VERSION "created by canmatrix"

NS_ :

BS_:

BU_: MD1_ECM ETC NODE_5 BSM_EBS RM_IRCS IC_Multic SGW BCM_NBM VCM NODE_31 ETS NODE_45 FCCU DICO NODE_72 FMReceiver SGW2 VCU ADCU MRGEN DTCO MBMS TPMS AI_CAID ELC ELC_R NODE_F7 BMS3 TUROLLA PCM SRR_Front_Left SRR_Rear_Right SRR_Front_Right SRR_Front SRR_Rear_Left ELFA3_S THERMOKING_M TMU_HP_Rr NODE_B1 NODE_B2 NODE_B3 NODE_B4 NODE_B5 NODE_B6 NODE_B7 NODE_B8 BMS2 NODE_B9 NODE_BA NODE_FC NODE_BB NODE_BC NODE_BE NODE_BD NODE_BF ACU NODE_C0 BMS1 NODE_C1 FCU NODE_C3 NODE_C4 NODE_EC NODE_C5 NODE_C6 NODE_C7 NODE_C8 VCU2 NODE_CA NODE_CB NODE_CD NODE_CE NODE_CF NODE_ED ST_ScanTool MASTER68_STD1 NODE_D1 NODE_F2 NODE_FD NODE_D2 MCSL NODE_EB NODE_D3 NODE_D4 NODE_D5 NODE_D6 VCCU NODE_D8 NODE_D9 NODE_F9 DiagTool NODE_DA NODE_DB NODE_DC NODE_DD NODE_DE NODE_DF NODE_E0 NODE_E1 NODE_E2 NODE_E9 NODE_E3 SAS NODE_FB NODE_F8 NODE_E6 ELFA3 NODE_F THERMOKING_D FMS MULTIC_S MULTIC_2 BMS4 BMS5 BMS6 BMS7 BMS8 BMS9 BMS10 BMS11 NODE_71

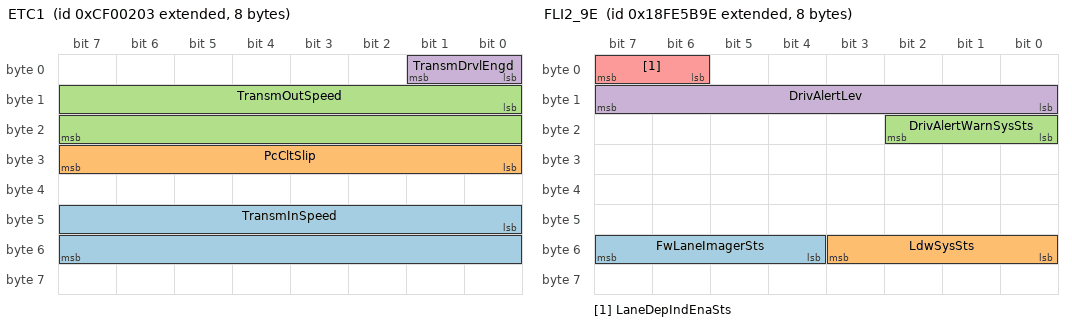
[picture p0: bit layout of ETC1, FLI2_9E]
BO_ 2364539395 ETC1: 8 ETC
 SG_ TransmInSpeed : 40|16@1+ (0.125,0) [0|8031.875] "rpm"  PCM
 SG_ PcCltSlip : 24|8@1+ (0.4,0) [0|100] "%"  PCM
 SG_ TransmOutSpeed : 8|16@1+ (0.125,0) [0|8031.875] "rpm"  PCM
 SG_ TransmDrvlEngd : 0|2@1+ (1,0) [0|3] ""  PCM

BO_ 2565866755 ETC2: 8 ETC
 SG_ TransmCurGear : 24|8@1+ (1,-125) [-125|125] "gear value"  PCM
 SG_ TransmSelGear : 0|8@1+ (1,-125) [-125|125] "gear value"  PCM

BO_ 2566826755 ETC6_P6: 8 ETC
 SG_ LowPossGear : 16|8@1+ (1,-125) [-125|125] "gear value"  PCM
 SG_ HighPossGear : 8|8@1+ (1,-125) [-125|125] "gear value"  PCM

BO_ 2364541955 ETC8: 8 ETC
 SG_ TransmTrqConvRatio : 0|16@1+ (0.001,0) [0|64.255] ""  PCM

BO_ 2566831393 FD1_21: 8 BCM_NBM
 SG_ FanSpeed : 16|16@1+ (0.125,0) [0|8031.875] "rpm"  PCM

BO_ 2431649694 FLI1_9E: 8 ADCU
 SG_ LaneDepImmLh : 6|2@1+ (1,0) [0|3] ""  PCM
 SG_ LaneDepImmRh : 4|2@1+ (1,0) [0|3] ""  PCM

BO_ 2566806430 FLI2_9E: 8 ADCU
 SG_ FwLaneImagerSts : 52|4@1+ (1,0) [0|15] ""  PCM
 SG_ LdwSysSts : 48|4@1+ (1,0) [0|15] ""  PCM
 SG_ DrivAlertWarnSysSts : 16|3@1+ (1,0) [0|7] ""  PCM
 SG_ DrivAlertLev : 8|8@1+ (0.4,0) [0|100] "%"  PCM
 SG_ LaneDepIndEnaSts : 6|2@1+ (1,0) [0|3] ""  PCM

BO_ 2566841600 HOURS: 8 MD1_ECM
 SG_ EngTotHrOfOp : 0|32@1+ (0.05,0) [0|210554060.75] "h"  PCM

BO_ 2566719744 HRLFC: 8 MD1_ECM
 SG_ EngTotFuelUsedHr : 32|32@1+ (0.001,0) [0|4211081.215] "L"  PCM

BO_ 2566837793 HSI1_21: 8 BCM_NBM
 SG_ HybSysCoastRegenBrkLevSel : 16|8@1+ (0.4,0) [0|100] "%"  PCM
 SG_ HybSysPwrElnCoolLevSw : 4|2@1+ (1,0) [0|3] ""  PCM

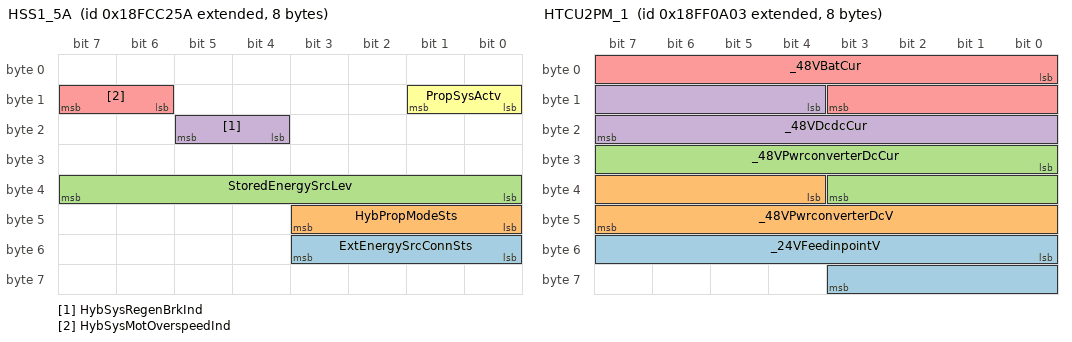
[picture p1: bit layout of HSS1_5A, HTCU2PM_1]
BO_ 2566701658 HSS1_5A: 8 DICO
 SG_ ExtEnergySrcConnSts : 48|4@1+ (1,0) [0|15] ""  PCM
 SG_ HybPropModeSts : 40|4@1+ (1,0) [0|15] ""  PCM
 SG_ StoredEnergySrcLev : 32|8@1+ (0.4,0) [0|100] "%"  PCM
 SG_ HybSysRegenBrkInd : 20|2@1+ (1,0) [0|3] ""  PCM
 SG_ HybSysMotOverspeedInd : 14|2@1+ (1,0) [0|3] ""  PCM
 SG_ PropSysActv : 8|2@1+ (1,0) [0|3] ""  PCM

BO_ 2566698842 HSS2_5A: 8 DICO
 SG_ HybSysEassRemPc : 16|8@1+ (0.4,0) [0|100] "%"  PCM
 SG_ HybBatRemChg : 0|16@1+ (0.0025,0) [0|160.6375] "%"  PCM

BO_ 2566850819 HTCU2BC_03: 8 ETC
 SG_ StsOfHealt : 56|8@1+ (0.5,0) [0|100] "%"  PCM
 SG_ Soc : 44|12@1+ (0.1,-200) [-200|209.5] "%"  PCM

BO_ 2566851075 HTCU2PM_1: 8 ETC
 SG_ _24VFeedinpointV : 48|12@1+ (0.025,0) [0|100.375] "V"  PCM
 SG_ _48VPwrconverterDcV : 36|12@1+ (0.025,0) [0|100.375] "V"  PCM
 SG_ _48VPwrconverterDcCur : 24|12@1+ (0.5,-1000) [-1000|1007.5] "A"  PCM
 SG_ _48VDcdcCur : 12|12@1+ (0.5,-1000) [-1000|1007.5] "A"  PCM
 SG_ _48VBatCur : 0|12@1+ (0.5,-1000) [-1000|1007.5] "A"  PCM

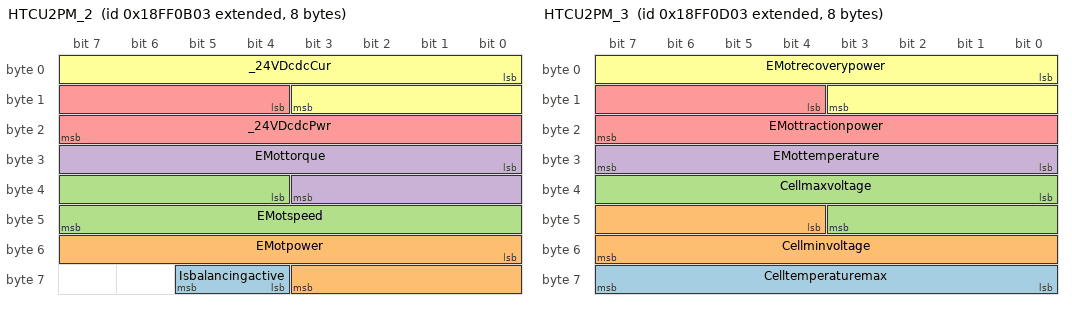
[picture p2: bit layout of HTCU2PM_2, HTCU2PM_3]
BO_ 2566851331 HTCU2PM_2: 8 ETC
 SG_ Isbalancingactive : 60|2@1+ (1,0) [0|3] ""  PCM
 SG_ EMotpower : 48|12@1+ (25,-50000) [-50000|52375] ""  PCM
 SG_ EMotspeed : 36|12@1+ (1,-500) [-500|3515] "rpm"  PCM
 SG_ EMottorque : 24|12@1+ (0.2,-400) [-400|403] "Nm"  PCM
 SG_ _24VDcdcPwr : 12|12@1+ (25,-50000) [-50000|52375] "W"  PCM
 SG_ _24VDcdcCur : 0|12@1+ (0.5,-1000) [-1000|1007.5] "A"  PCM

BO_ 2566851843 HTCU2PM_3: 8 ETC
 SG_ Celltemperaturemax : 56|8@1+ (1,-40) [-40|210] "°C"  PCM
 SG_ Cellminvoltage : 44|12@1+ (0.002,0) [0|8.03] "V"  PCM
 SG_ Cellmaxvoltage : 32|12@1+ (0.002,0) [0|8.03] "V"  PCM
 SG_ EMottemperature : 24|8@1+ (1,-40) [-40|210] "°C"  PCM
 SG_ EMottractionpower : 12|12@1+ (25,-50000) [-50000|52375] "W"  PCM
 SG_ EMotrecoverypower : 0|12@1+ (25,-50000) [-50000|52375] "W"  PCM

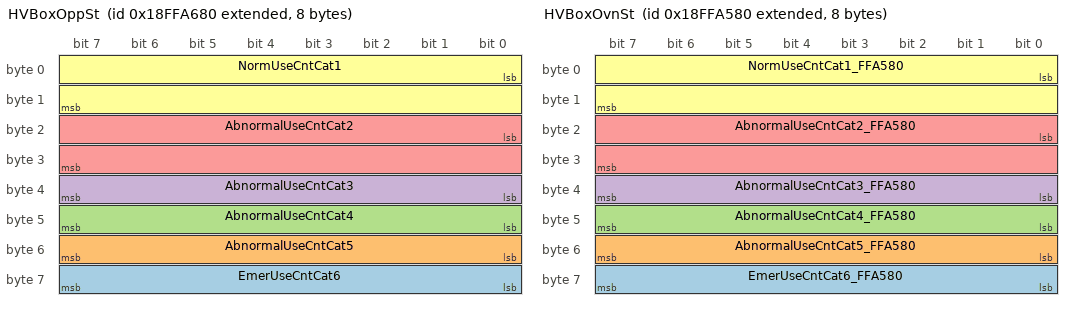
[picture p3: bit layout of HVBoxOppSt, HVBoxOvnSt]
BO_ 2566891136 HVBoxOppSt: 8 VCU
 SG_ EmerUseCntCat6 : 56|8@1+ (1,0) [0|250] "count"  PCM
 SG_ AbnormalUseCntCat5 : 48|8@1+ (1,0) [0|250] "count"  PCM
 SG_ AbnormalUseCntCat4 : 40|8@1+ (5,0) [0|1250] "count"  PCM
 SG_ AbnormalUseCntCat3 : 32|8@1+ (200,0) [0|50000] "count"  PCM
 SG_ AbnormalUseCntCat2 : 16|16@1+ (2,0) [0|128510] "count"  PCM
 SG_ NormUseCntCat1 : 0|16@1+ (5,0) [0|321275] "count"  PCM

BO_ 2566890880 HVBoxOvnSt: 8 VCU
 SG_ EmerUseCntCat6_FFA580 : 56|8@1+ (1,0) [0|250] "count"  PCM
 SG_ AbnormalUseCntCat5_FFA580 : 48|8@1+ (1,0) [0|250] "count"  PCM
 SG_ AbnormalUseCntCat4_FFA580 : 40|8@1+ (5,0) [0|1250] "count"  PCM
 SG_ AbnormalUseCntCat3_FFA580 : 32|8@1+ (200,0) [0|50000] "count"  PCM
 SG_ AbnormalUseCntCat2_FFA580 : 16|16@1+ (2,0) [0|128510] "count"  PCM
 SG_ NormUseCntCat1_FFA580 : 0|16@1+ (5,0) [0|321275] "count"  PCM

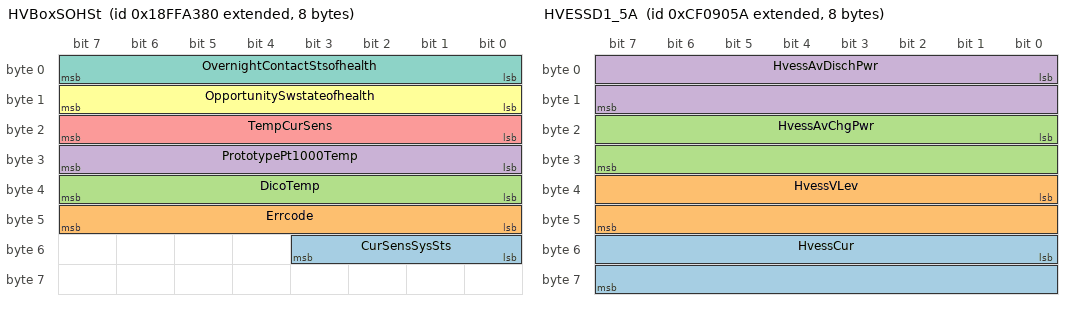
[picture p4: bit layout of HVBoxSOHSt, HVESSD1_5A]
BO_ 2566890368 HVBoxSOHSt: 8 VCU
 SG_ CurSensSysSts : 48|4@1+ (1,0) [0|15] ""  PCM
 SG_ Errcode : 40|8@1+ (1,0) [0|250] ""  PCM
 SG_ DicoTemp : 32|8@1+ (1,-40) [-40|120] "°C"  PCM
 SG_ PrototypePt1000Temp : 24|8@1+ (1,-40) [-40|120] "°C"  PCM
 SG_ TempCurSens : 16|8@1+ (1,-40) [-40|80] "°C"  PCM
 SG_ OpportunitySwstateofhealth : 8|8@1+ (0.4,0) [0|100] "%"  PCM
 SG_ OvernightContactStsofhealth : 0|8@1+ (0.4,0) [0|100] "%"  PCM

BO_ 2364575834 HVESSD1_5A: 8 DICO
 SG_ HvessCur : 48|16@1+ (0.05,-1600) [-1600|1612.75] "A"  PCM
 SG_ HvessVLev : 32|16@1+ (0.05,0) [0|3212.75] "V"  PCM
 SG_ HvessAvChgPwr : 16|16@1+ (0.05,0) [0|3212.75] "kW"  PCM
 SG_ HvessAvDischPwr : 0|16@1+ (0.05,0) [0|3212.75] "kW"  PCM

BO_ 2365349619 HVESSHIST_F3: 11 MBMS
 SG_ HvessTotAccumChg : 56|32@1+ (100,0) [0|421108121500] "Ah"  PCM
 SG_ HvessTotEnergyTput : 24|32@1+ (100,0) [0|421108121500] "Watt-hour"  PCM
 SG_ HvessSoh : 0|8@1+ (0.4,0) [0|100] "%"  PCM

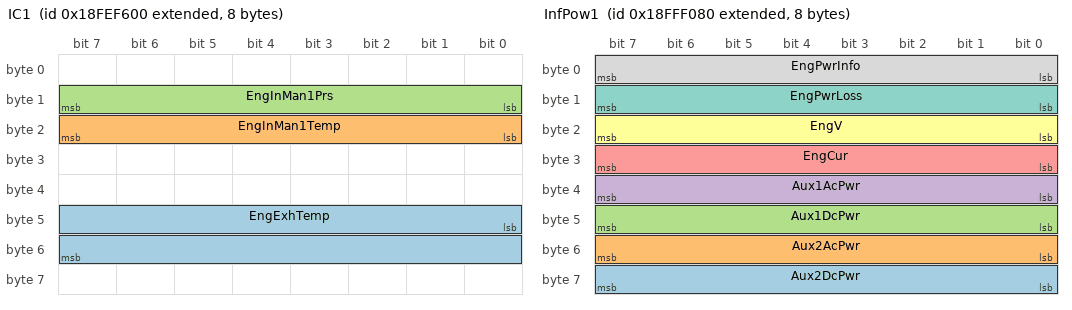
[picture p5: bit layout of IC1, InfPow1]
BO_ 2566845952 IC1: 8 MD1_ECM
 SG_ EngExhTemp : 40|16@1+ (0.03125,-273) [-273|1734.96875] "°C"  PCM
 SG_ EngInMan1Temp : 16|8@1+ (1,-40) [-40|210] "°C"  PCM
 SG_ EngInMan1Prs : 8|8@1+ (2,0) [0|500] "kPa"  PCM

BO_ 2566910080 InfPow1: 8 VCU
 SG_ Aux2DcPwr : 56|8@1+ (0.2,0) [0|50] "KW"  PCM
 SG_ Aux2AcPwr : 48|8@1+ (0.2,0) [0|50] "KW"  PCM
 SG_ Aux1DcPwr : 40|8@1+ (0.2,0) [0|50] "KW"  PCM
 SG_ Aux1AcPwr : 32|8@1+ (0.2,0) [0|50] "KW"  PCM
 SG_ EngCur : 24|8@1+ (4,-500) [-500|500] "A"  PCM
 SG_ EngV : 16|8@1+ (3.4,0) [0|850] "V"  PCM
 SG_ EngPwrLoss : 8|8@1+ (0.2,0) [0|50] "KW"  PCM
 SG_ EngPwrInfo : 0|8@1+ (4,-500) [-500|500] "KW"  PCM

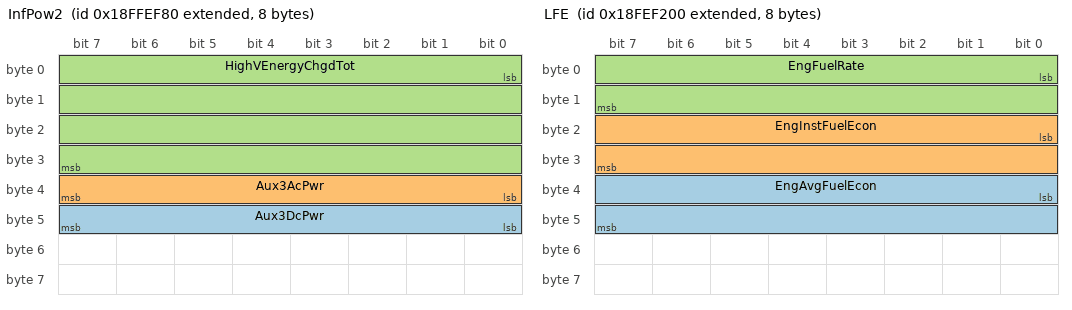
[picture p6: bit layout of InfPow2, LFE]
BO_ 2566909824 InfPow2: 8 VCU
 SG_ Aux3DcPwr : 40|8@1+ (0.2,0) [0|50] "KW"  PCM
 SG_ Aux3AcPwr : 32|8@1+ (0.2,0) [0|50] "KW"  PCM
 SG_ HighVEnergyChgdTot : 0|32@1+ (0.1,0) [0|199999999.9] "KWh"  PCM

BO_ 2566786839 LC_17: 8 IC_Multic
 SG_ LangCodeCmd : 0|16@1+ (1,0) [0|65535] "ASCII"  PCM

BO_ 2566842624 LFC: 8 MD1_ECM
 SG_ EngTotFuelUsed : 32|32@1+ (0.5,0) [0|2105540607.5] "L"  PCM

BO_ 2566844928 LFE: 8 MD1_ECM
 SG_ EngAvgFuelEcon : 32|16@1+ (0.001953125,0) [0|125.498046875] "km/L"  PCM
 SG_ EngInstFuelEcon : 16|16@1+ (0.001953125,0) [0|125.498046875] "km/L"  PCM
 SG_ EngFuelRate : 0|16@1+ (0.05,0) [0|3212.75] "L/h"  PCM

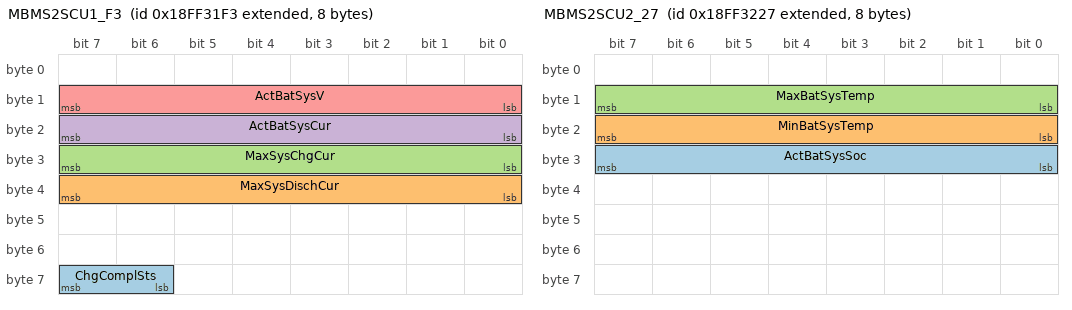
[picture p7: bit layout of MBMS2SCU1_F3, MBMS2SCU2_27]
BO_ 2566861299 MBMS2SCU1_F3: 8 MBMS
 SG_ ChgComplSts : 62|2@1+ (1,0) [0|3] ""  PCM
 SG_ MaxSysDischCur : 32|8@1+ (3,0) [0|750] "A"  PCM
 SG_ MaxSysChgCur : 24|8@1+ (3,0) [0|750] "A"  PCM
 SG_ ActBatSysCur : 16|8@1+ (4,-500) [-500|500] "A"  PCM
 SG_ ActBatSysV : 8|8@1+ (3.4,0) [0|850] "V"  PCM

BO_ 2566861351 MBMS2SCU2_27: 8 VCM
 SG_ ActBatSysSoc : 24|8@1+ (0.4,0) [0|100] "%"  PCM
 SG_ MinBatSysTemp : 16|8@1+ (1,-40) [-40|210] "°C"  PCM
 SG_ MaxBatSysTemp : 8|8@1+ (1,-40) [-40|210] "°C"  PCM

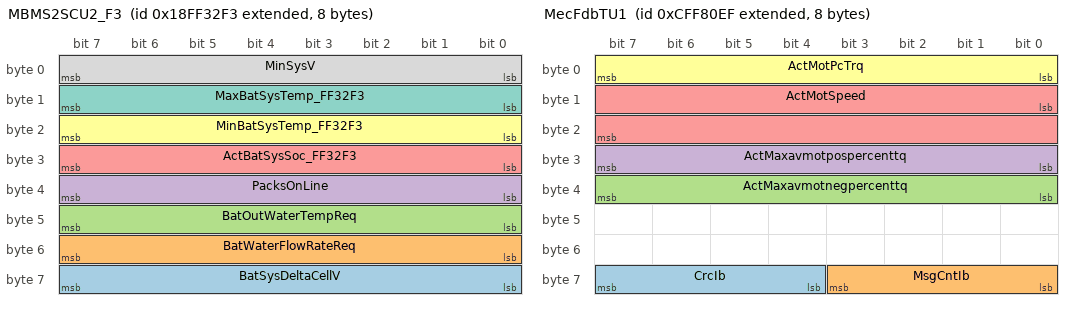
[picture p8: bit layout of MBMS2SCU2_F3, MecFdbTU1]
BO_ 2566861555 MBMS2SCU2_F3: 8 MBMS
 SG_ BatSysDeltaCellV : 56|8@1+ (10,0) [0|2500] "Mv"  PCM
 SG_ BatWaterFlowRateReq : 48|8@1+ (50,0) [0|12500] "L/h"  PCM
 SG_ BatOutWaterTempReq : 40|8@1+ (1,-40) [-40|210] "°C"  PCM
 SG_ PacksOnLine : 32|8@1+ (1,0) [0|250] "pack"  PCM
 SG_ ActBatSysSoc_FF32F3 : 24|8@1+ (0.4,0) [0|100] "%"  PCM
 SG_ MinBatSysTemp_FF32F3 : 16|8@1+ (1,-40) [-40|210] "°C"  PCM
 SG_ MaxBatSysTemp_FF32F3 : 8|8@1+ (1,-40) [-40|210] "°C"  PCM
 SG_ MinSysV : 0|8@1+ (3.4,0) [0|850] "V"  PCM

BO_ 2365554927 MecFdbTU1: 8 ELFA3
 SG_ CrcIb : 60|4@1+ (1,0) [0|15] ""  PCM
 SG_ MsgCntIb : 56|4@1+ (1,0) [0|15] ""  PCM
 SG_ ActMaxavmotnegpercenttq : 32|8@1+ (1,-125) [-125|0] "%"  PCM
 SG_ ActMaxavmotpospercenttq : 24|8@1+ (1,-125) [0|125] "%"  PCM
 SG_ ActMotSpeed : 8|16@1+ (1,-32127) [-32127|32128] "rpm"  PCM
 SG_ ActMotPcTrq : 0|8@1+ (1,-125) [-125|125] "%"  PCM

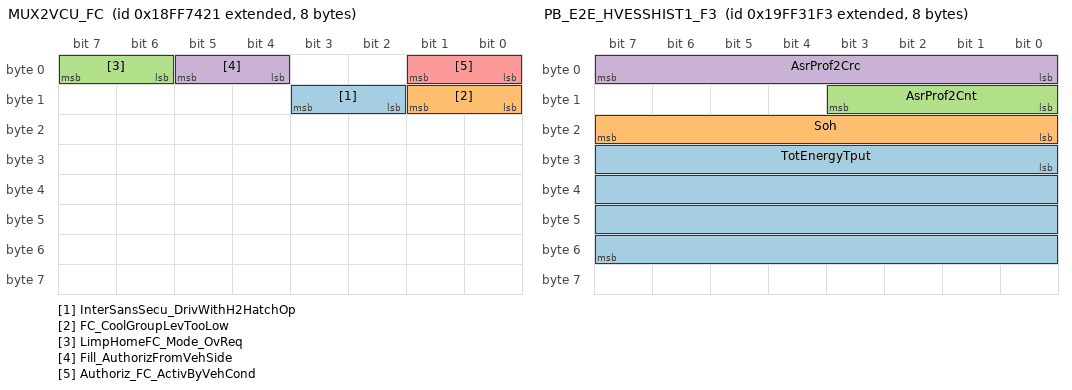
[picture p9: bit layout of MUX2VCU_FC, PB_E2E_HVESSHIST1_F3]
BO_ 2566878241 MUX2VCU_FC: 8 BCM_NBM
 SG_ InterSansSecu_DrivWithH2HatchOp : 10|2@1+ (1,0) [0|1] ""  PCM
 SG_ FC_CoolGroupLevTooLow : 8|2@1+ (1,0) [0|1] ""  PCM
 SG_ LimpHomeFC_Mode_OvReq : 6|2@1+ (1,0) [0|1] ""  PCM
 SG_ Fill_AuthorizFromVehSide : 4|2@1+ (1,0) [0|1] ""  PCM
 SG_ Authoriz_FC_ActivByVehCond : 0|2@1+ (1,0) [0|3] ""  PCM

BO_ 2566776097 MVS_21: 8 BCM_NBM
 SG_ AppliedVsl : 56|8@1+ (1,0) [0|250] "km/h"  PCM
 SG_ MaxVsl1 : 0|8@1+ (1,0) [0|250] "km/h"  PCM

BO_ 2365443105 OEL: 8 BCM_NBM
 SG_ TurnSigSw : 8|4@1+ (1,0) [0|15] ""  PCM

BO_ 2566769953 OWW_21: 8 BCM_NBM
 SG_ FrontOpWasherSw : 45|3@1+ (1,0) [0|7] ""  PCM
 SG_ FrontOpWiperSw : 4|4@1+ (1,0) [0|15] ""  PCM

BO_ 2633959399 PB_ACU: 8 ACU
 SG_ StopLamp : 6|2@1+ (1,0) [0|3] ""  PCM
 SG_ FunctLamp : 4|2@1+ (1,0) [0|3] ""  PCM

BO_ 2566850535 PB_ACU_E7: 8 ACU
 SG_ StopLamp_FF07E7 : 6|2@1+ (1,0) [0|3] ""  PCM
 SG_ FunctLamp_FF07E7 : 4|2@1+ (1,0) [0|3] ""  PCM

BO_ 2566908574 PB_AIDI_9E: 8 ADCU
 SG_ DdawRunMode : 8|3@1+ (1,0) [0|7] ""  PCM
 SG_ DrowsDrivLev : 3|3@1+ (1,0) [0|7] ""  PCM

BO_ 2583638515 PB_E2E_HVESSHIST1_F3: 8 MBMS
 SG_ TotEnergyTput : 24|32@1+ (1000,0) [0|4211081215000] "Watt-hour"  PCM
 SG_ Soh : 16|8@1+ (0.4,0) [0|100] "%"  PCM
 SG_ AsrProf2Cnt : 8|4@1+ (1,0) [0|15] ""  PCM
 SG_ AsrProf2Crc : 0|8@1+ (1,0) [0|255] ""  PCM

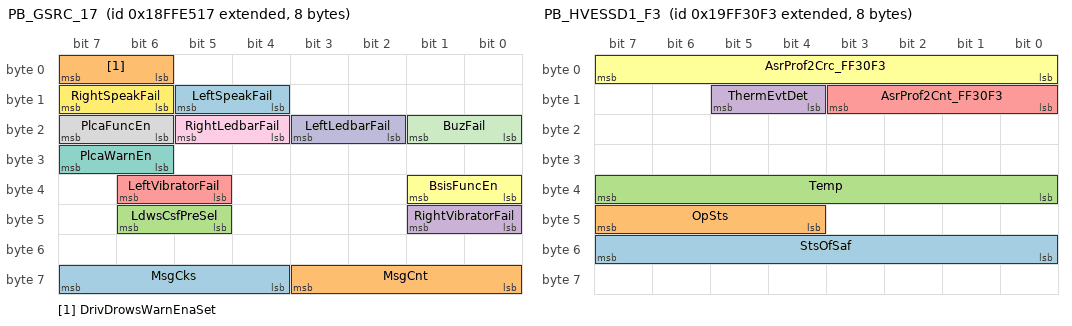
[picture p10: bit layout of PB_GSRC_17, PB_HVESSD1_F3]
BO_ 2566907159 PB_GSRC_17: 8 IC_Multic
 SG_ MsgCks : 60|4@1+ (1,0) [0|15] "count"  PCM
 SG_ MsgCnt : 56|4@1+ (1,0) [0|15] "count"  PCM
 SG_ LdwsCsfPreSel : 45|2@1+ (1,0) [0|3] ""  PCM
 SG_ RightVibratorFail : 40|2@1+ (1,0) [0|3] ""  PCM
 SG_ LeftVibratorFail : 37|2@1+ (1,0) [0|3] ""  PCM
 SG_ BsisFuncEn : 32|2@1+ (1,0) [0|3] ""  PCM
 SG_ PlcaWarnEn : 30|2@1+ (1,0) [0|3] ""  PCM
 SG_ PlcaFuncEn : 22|2@1+ (1,0) [0|3] ""  PCM
 SG_ RightLedbarFail : 20|2@1+ (1,0) [0|3] ""  PCM
 SG_ LeftLedbarFail : 18|2@1+ (1,0) [0|3] ""  PCM
 SG_ BuzFail : 16|2@1+ (1,0) [0|3] ""  PCM
 SG_ RightSpeakFail : 14|2@1+ (1,0) [0|3] ""  PCM
 SG_ LeftSpeakFail : 12|2@1+ (1,0) [0|3] ""  PCM
 SG_ DrivDrowsWarnEnaSet : 6|2@1+ (1,0) [0|3] ""  PCM

BO_ 2583638259 PB_HVESSD1_F3: 8 MBMS
 SG_ StsOfSaf : 48|8@1+ (0.4,0) [0|100] "%"  PCM
 SG_ OpSts : 44|4@1+ (1,0) [0|15] ""  PCM
 SG_ Temp : 32|8@1+ (1,-40) [-40|210] "°C"  PCM
 SG_ ThermEvtDet : 12|2@1+ (1,0) [0|3] ""  PCM
 SG_ AsrProf2Cnt_FF30F3 : 8|4@1+ (1,0) [0|15] ""  PCM
 SG_ AsrProf2Crc_FF30F3 : 0|8@1+ (1,0) [0|255] ""  PCM

BO_ 2650750451 PB_HVESSHIST_F3: 11 MBMS
 SG_ HvessTotAccumChg_FF3DF3 : 56|32@1+ (100,0) [0|421108121500] "Ah"  PCM
 SG_ HvessTotEnergyTput_FF3DF3 : 24|32@1+ (100,0) [0|421108121500] "Watt-hour"  PCM
 SG_ HvessSoh_FF3DF3 : 0|8@1+ (0.4,0) [0|100] "%"  PCM

BO_ 2566894871 PB_ISA_17: 8 IC_Multic
 SG_ CntryCode : 22|10@1+ (1,0) [0|1023] ""  PCM
 SG_ IntlSpeedAssantActv : 8|3@1+ (1,0) [0|7] ""  PCM

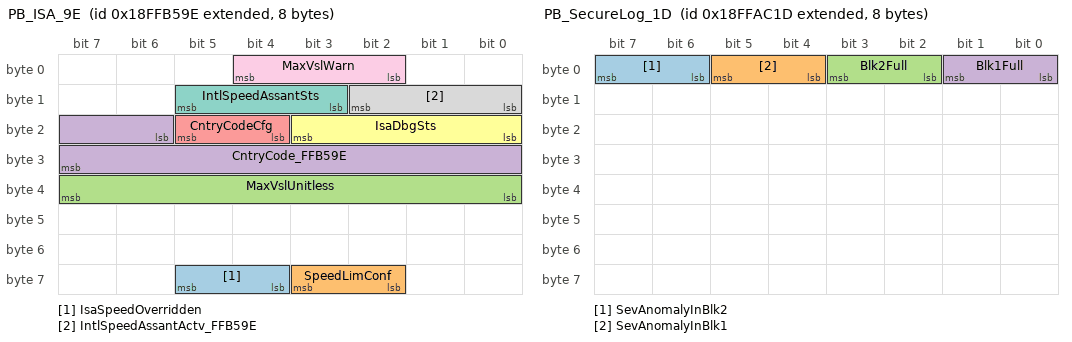
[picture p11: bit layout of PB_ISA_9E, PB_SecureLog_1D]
BO_ 2566895006 PB_ISA_9E: 8 ADCU
 SG_ IsaSpeedOverridden : 60|2@1+ (1,0) [0|3] ""  PCM
 SG_ SpeedLimConf : 58|2@1+ (1,0) [0|3] ""  PCM
 SG_ MaxVslUnitless : 32|8@1+ (1,0) [0|140] ""  PCM
 SG_ CntryCode_FFB59E : 22|10@1+ (1,0) [0|1023] ""  PCM
 SG_ CntryCodeCfg : 20|2@1+ (1,0) [0|3] ""  PCM
 SG_ IsaDbgSts : 16|4@1+ (1,0) [0|15] ""  PCM
 SG_ IntlSpeedAssantSts : 11|3@1+ (1,0) [0|7] ""  PCM
 SG_ IntlSpeedAssantActv_FFB59E : 8|3@1+ (1,0) [0|7] ""  PCM
 SG_ MaxVslWarn : 2|3@1+ (1,0) [0|3] ""  PCM

BO_ 2365575713 PB_NmM: 8 BCM_NBM
 SG_ EngStarterSts : 20|2@1+ (1,0) [0|3] ""  PCM
 SG_ IgnOn : 4|2@1+ (1,0) [0|3] ""  PCM

BO_ 2566892573 PB_SecureLog_1D: 8 SGW
 SG_ SevAnomalyInBlk2 : 6|2@1+ (1,0) [0|3] ""  PCM
 SG_ SevAnomalyInBlk1 : 4|2@1+ (1,0) [0|3] ""  PCM
 SG_ Blk2Full : 2|2@1+ (1,0) [0|3] ""  PCM
 SG_ Blk1Full : 0|2@1+ (1,0) [0|3] ""  PCM

BO_ 2566892618 PB_SecureLog_4A: 8 PCM
 SG_ WarnRx : 8|2@1+ (1,0) [0|3] "" Vector__XXX

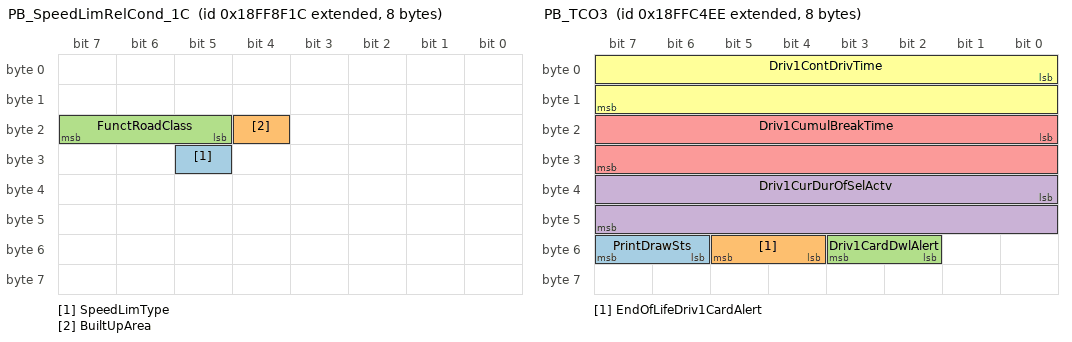
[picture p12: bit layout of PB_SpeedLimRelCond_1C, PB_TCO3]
BO_ 2566885148 PB_SpeedLimRelCond_1C: 8 PCM
 SG_ SpeedLimType : 29|1@0+ (1,0) [0|1] "" Vector__XXX
 SG_ BuiltUpArea : 20|1@0+ (1,0) [0|1] "" Vector__XXX
 SG_ FunctRoadClass : 23|3@0+ (1,0) [0|7] "" Vector__XXX

BO_ 2566898670 PB_TCO2: 21 DTCO
 SG_ WFact : 152|16@1+ (0.001,0) [2.4|25] "pulse/m"  PCM
 SG_ NextCalDateYr : 144|8@1+ (1,1985) [1985|2235] "year"  PCM
 SG_ NextCalDateMonth : 136|8@1+ (1,0) [1|12] "month"  PCM
 SG_ NextCalDateDay : 128|8@1+ (0.25,0) [0.25|31.75] "day"  PCM
 SG_ PrefLang : 112|16@1+ (1,0) [0|255] "ASCII"  PCM
 SG_ Driv1Id_FFC3EE : 0|8@1+ (1,0) [0|255] "ASCII"  PCM

BO_ 2566898926 PB_TCO3: 8 DTCO
 SG_ PrintDrawSts : 54|2@1+ (1,0) [0|3] ""  PCM
 SG_ EndOfLifeDriv1CardAlert : 52|2@1+ (1,0) [0|3] ""  PCM
 SG_ Driv1CardDwlAlert : 50|2@1+ (1,0) [0|3] ""  PCM
 SG_ Driv1CurDurOfSelActv : 32|16@1+ (1,0) [0|64255] "min"  PCM
 SG_ Driv1CumulBreakTime : 16|16@1+ (1,0) [0|64255] "min"  PCM
 SG_ Driv1ContDrivTime : 0|16@1+ (1,0) [0|64255] "min"  PCM

BO_ 2566899694 PB_TCO4: 44 DTCO
 SG_ AvCnt : 336|16@1+ (1,0) [0|64255] "min"  PCM
 SG_ WorkCnt : 320|16@1+ (1,0) [0|64255] "min"  PCM
 SG_ DrivCnt : 304|16@1+ (1,0) [0|64255] "min"  PCM
 SG_ TwoWeeksTotOdo : 288|16@1+ (1,0) [0|64255] "km"  PCM
 SG_ WeekTotOdo : 272|16@1+ (1,0) [0|64255] "km"  PCM
 SG_ DayOdo : 256|16@1+ (1,0) [0|64255] "km"  PCM
 SG_ DayRestPer7Flag : 255|1@1+ (1,0) [0|1] ""  PCM
 SG_ DayRestPer7 : 240|15@1+ (1,0) [0|31487] "min"  PCM
 SG_ DayRestPer6Flag : 239|1@1+ (1,0) [0|1] ""  PCM
 SG_ DayRestPer6 : 224|15@1+ (1,0) [0|31487] "min"  PCM
 SG_ DayRestPer5Flag : 223|1@1+ (1,0) [0|1] ""  PCM
 SG_ DayRestPer5 : 208|15@1+ (1,0) [0|31487] "min"  PCM
 SG_ DayRestPer4Flag : 207|1@1+ (1,0) [0|1] ""  PCM
 SG_ DayRestPer4 : 192|15@1+ (1,0) [0|31487] "min"  PCM
 SG_ DayRestPer3Flag : 191|1@1+ (1,0) [0|1] ""  PCM
 SG_ DayRestPer3 : 176|15@1+ (1,0) [0|31487] "min"  PCM
 SG_ DayRestPer2Flag : 175|1@1+ (1,0) [0|1] ""  PCM
 SG_ DayRestPer2 : 160|15@1+ (1,0) [0|31487] "min"  PCM
 SG_ DayRestPer1Flag : 159|1@1+ (1,0) [0|1] ""  PCM
 SG_ DayRestPer1 : 144|15@1+ (1,0) [0|31487] "min"  PCM
 SG_ DayDrivTimeShift6Flag : 143|1@1+ (1,0) [0|1] ""  PCM
 SG_ DayDrivTimeShift6 : 128|15@1+ (1,0) [0|31487] "min"  PCM
 SG_ DayDrivTimeShift5Flag : 127|1@1+ (1,0) [0|1] ""  PCM
 SG_ DayDrivTimeShift5 : 112|15@1+ (1,0) [0|31487] "min"  PCM
 SG_ DayDrivTimeShift4Flag : 111|1@1+ (1,0) [0|1] ""  PCM
 SG_ DayDrivTimeShift4 : 96|15@1+ (1,0) [0|31487] "min"  PCM
 SG_ DayDrivTimeShift3Flag : 95|1@1+ (1,0) [0|1] ""  PCM
 SG_ DayDrivTimeShift3 : 80|15@1+ (1,0) [0|31487] "min"  PCM
 SG_ DayDrivTimeShift2Flag : 79|1@1+ (1,0) [0|1] ""  PCM
 SG_ DayDrivTimeShift2 : 64|15@1+ (1,0) [0|31487] "min"  PCM
 SG_ DayDrivTimeShift1Flag : 63|1@1+ (1,0) [0|1] ""  PCM
 SG_ DayDrivTimeShift1 : 48|15@1+ (1,0) [0|31487] "min"  PCM
 SG_ DayDrivTimeFlag : 47|1@1+ (1,0) [0|1] ""  PCM
 SG_ DayDrivTime : 32|15@1+ (1,0) [0|31487] "min"  PCM
 SG_ WeekTotDrivTime : 16|16@1+ (1,0) [0|64255] "min"  PCM
 SG_ TwoWeeksTotDrivTime : 0|16@1+ (1,0) [0|64255] "min"  PCM

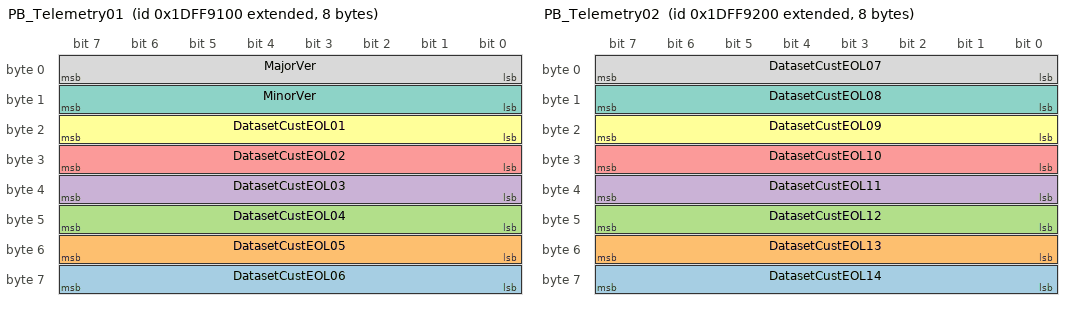
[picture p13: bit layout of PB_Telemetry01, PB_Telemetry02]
BO_ 2650771712 PB_Telemetry01: 8 MD1_ECM
 SG_ DatasetCustEOL06 : 56|8@1+ (1,0) [0|255] ""  PCM
 SG_ DatasetCustEOL05 : 48|8@1+ (1,0) [0|255] ""  PCM
 SG_ DatasetCustEOL04 : 40|8@1+ (1,0) [0|255] ""  PCM
 SG_ DatasetCustEOL03 : 32|8@1+ (1,0) [0|255] ""  PCM
 SG_ DatasetCustEOL02 : 24|8@1+ (1,0) [0|255] ""  PCM
 SG_ DatasetCustEOL01 : 16|8@1+ (1,0) [0|255] ""  PCM
 SG_ MinorVer : 8|8@1+ (1,0) [0|255] ""  PCM
 SG_ MajorVer : 0|8@1+ (1,0) [0|255] ""  PCM

BO_ 2650771968 PB_Telemetry02: 8 MD1_ECM
 SG_ DatasetCustEOL14 : 56|8@1+ (1,0) [0|255] ""  PCM
 SG_ DatasetCustEOL13 : 48|8@1+ (1,0) [0|255] ""  PCM
 SG_ DatasetCustEOL12 : 40|8@1+ (1,0) [0|255] ""  PCM
 SG_ DatasetCustEOL11 : 32|8@1+ (1,0) [0|255] ""  PCM
 SG_ DatasetCustEOL10 : 24|8@1+ (1,0) [0|255] ""  PCM
 SG_ DatasetCustEOL09 : 16|8@1+ (1,0) [0|255] ""  PCM
 SG_ DatasetCustEOL08 : 8|8@1+ (1,0) [0|255] ""  PCM
 SG_ DatasetCustEOL07 : 0|8@1+ (1,0) [0|255] ""  PCM

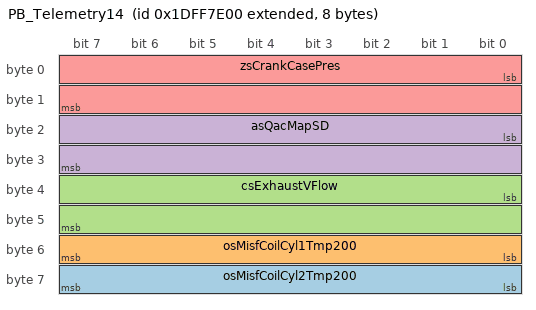
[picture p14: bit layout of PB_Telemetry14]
BO_ 2650766848 PB_Telemetry14: 8 MD1_ECM
 SG_ osMisfCoilCyl2Tmp200 : 56|8@1+ (1,0) [0|255] "adm"  PCM
 SG_ osMisfCoilCyl1Tmp200 : 48|8@1+ (1,0) [0|255] "adm"  PCM
 SG_ csExhaustVFlow : 32|16@1+ (0.2,0) [0|13107] "m^3/h"  PCM
 SG_ asQacMapSD : 16|16@1+ (0.125,0) [0|8191.875] "mg/cc"  PCM
 SG_ zsCrankCasePres : 0|16@1+ (0.5,0) [-16384|16385.5] "mbar"  PCM

CM_ SG_ 2364539395 TransmInSpeed "- CUC.C.PCM..3..TELEM: Optional";
CM_ SG_ 2364539395 PcCltSlip "- CUC.C.PCM..3..TELEM: Optional
- EBC.ZF.BSM..27..VDB: not sent by AGB ZF Ecolife 2 + on FEV";
CM_ BO_ 2565866755 "- All Powertrain except manual transmission.
-  Full elec: J1939 codification, but only D/N/R and +1/0/-1 are used as there is no gearBox).
-  Multi-PG association valid when VCM is the sender of the message. Transmitted when no ETC, received otherwise
- IC1.A.IC.MulticS.24.CwFE.VDB: Update in according with ''OPL_Supermap'' request (line 50).";
CM_ SG_ 2565866755 TransmCurGear "- Negative values are reverse gears, positive values are forward gears, zero is neutral. 251(0xFB) is park";
CM_ SG_ 2565866755 TransmSelGear "- Negative values are reverse gears, positive values are forward gears, zero is neutral. 251(0xFB) is park
- MC.A.VCU..24..VDB: Only Gx (ELFA2)";
CM_ BO_ 2566826755 "- Only with manual transmission. SAE recommanded priority=7";
CM_ SG_ 2566826755 LowPossGear "- At least 3 gears below the maximum possible to indicate Splitter Low, 0xFF otherwise";
CM_ SG_ 2566826755 HighPossGear "- At least 3 gears above the maximum possible to indicate Splitter High, 0xFF otherwise";
CM_ BO_ 2364541955 "- 100ms in case torque converter locked. 20ms otherwise";
CM_ BO_ 2566831393 "- Only on UW Diesel CNG";
CM_ BO_ 2431649694 "- Fastest transmission rate 50ms when requested / not send when not requested
-  Transmitted when Lane Departure is active and at least once afterwards.";
CM_ BO_ 2566841600 "- All engines available, even if SA=00.
-  Cyclic Transmission Rate as result of PGN requests
-  SGW requests this PGN with RQST_1D_00
- VS2.B.SGW2..23..VDB: Used in freeze frames parameters.";
CM_ SG_ 2566841600 EngTotHrOfOp "- SAE J1939/73 Freeze Frame parameter";
CM_ BO_ 2566719744 "- Accumulated amount of fuel used during vehicle operation.";
CM_ BO_ 2566837793 "- Specific to Siemens Full Elec vehicles";
CM_ SG_ 2566837793 HybSysCoastRegenBrkLevSel "- Signal name Intercity file: Hybrid System Handlever Retarder";
CM_ BO_ 2566701658 "- Specific to Siemens Full Elec vehicles.
-  Transmision: Now 100ms, previously 1000ms, 100ms on change";
CM_ BO_ 2566698842 "- Specific to Siemens Full Elec vehicles";
CM_ SG_ 2566698842 HybBatRemChg "- Indicates the hybrid battery pack remaining charge. 0% means no charge remaining, 100% means full charge remaining. 0.0025 %/bit . offset 0 . 0 to 160.6375 %.";
CM_ BO_ 2566850819 "- Related to Voith Mild Hybrid project";
CM_ BO_ 2566851075 "- Related to Voith Mild Hybrid project
- CUC.C.PCM..3..TELEM: - Predisposal";
CM_ BO_ 2566851331 "- Related to Voith Mild Hybrid project
-  UW Mild Hybrid only";
CM_ BO_ 2566851843 "- Related to Voith Mild Hybrid project";
CM_ BO_ 2566891136 "- Specific to Siemens Full Elec vehicles";
CM_ BO_ 2566890880 "- Specific to Siemens Full Elec vehicles";
CM_ BO_ 2566890368 "- Specific to Siemens Full Elec vehicles. PCM Traction: in according with VCU file";
CM_ SG_ 2566890368 Errcode "- On event: in case of change of the errorCode the message will be send out acyclic.";
CM_ BO_ 2364575834 "- Specific to Siemens Full Elec vehicles.";
CM_ SG_ 2364575834 HvessCur "- A positive value represents current into (charging) the energy storage system.  A negative value represents current out of (discharging) the energy storage system.";
CM_ SG_ 2364575834 HvessAvChgPwr "- Send to NA value";
CM_ SG_ 2364575834 HvessAvDischPwr "- Send to NA value";
CM_ BO_ 2365349619 "- Specific to Siemens Full Elec vehicles - Predispo for PCM.
-  With Foresee batteries (GX with ELFA2): HVESSHIST_F3 message ID 0x 0C FC 5E F3";
CM_ SG_ 2566845952 EngExhTemp "- FE00h in case of defective sensor";
CM_ SG_ 2566845952 EngInMan1Temp "- FEh in case of defective sensor";
CM_ SG_ 2566845952 EngInMan1Prs "- FEh in case of defective sensor";
CM_ BO_ 2566910080 "- Specific to Siemens Full Elec vehicles";
CM_ BO_ 2566909824 "- Specific to Siemens Full Elec vehicles. Predisposal";
CM_ SG_ 2566909824 HighVEnergyChgdTot "- Total energy charged in the high voltage batteries in the vehicle life time";
CM_ SG_ 2566786839 LangCodeCmd "- Uses the 2-character string country codes in ISO 639.";
CM_ BO_ 2566842624 "- All engines except Full elec. CAN Engine: Only ''On Request''. Others Cyclic Transmission Rate as result of PGN requests";
CM_ BO_ 2566844928 "- All engines, without Full elec";
CM_ SG_ 2566844928 EngAvgFuelEcon "- Not emitted with C9 CNG";
CM_ BO_ 2566861299 "- Specific to Siemens Full Elec vehicles.
- CLC1.Tk.ACM....VDB: Filled in according with Intercity file";
CM_ BO_ 2566861351 "- Specific to Siemens Full Elec vehicles. Timeout (ms): 3000 ms";
CM_ BO_ 2566861555 "- Specific to Siemens Full Elec vehicles";
CM_ BO_ 2365554927 "- Specific to Siemens Full Elec vehicles. PCM: Fill in according with VCU file (CAN Traction)";
CM_ BO_ 2566776097 "- Specific to Siemens Full Elec vehicles.";
CM_ BO_ 2365443105 "- ADC.ZF.ADCU..24..VDB: Transmission rate may differ: ADCU VDB: 1000/On change";
CM_ BO_ 2633959399 "- 18m only.
-  In some applications used: Priority 6 (Id message 18 FF 07 E7)";
CM_ BO_ 2566850535 "- 18m only. Requested in Priority 6 (0x18). 19.07.2024";
CM_ BO_ 2566908574 "- Bus load periodic : 0.13";
CM_ SG_ 2566908574 DdawRunMode "- Valid for BUS MY24 DDAW indirect application";
CM_ SG_ 2566908574 DrowsDrivLev "- Valid for BUS MY24 DDAW indirect application";
CM_ SG_ 2566907159 DrivDrowsWarnEnaSet "- Valid for BUS MY24 DDAW indirect application";
CM_ BO_ 2650750451 "- Specific to Siemens Full Elec vehicles - Predispo for PCM.
-  With Microvast batteries (all other FE configs): HVESSHIST_F3_P7 message ID 0x1D FF 3D F3";
CM_ SG_ 2566895006 SpeedLimConf "- CW only
-  SPN Position Changed.";
CM_ SG_ 2566895006 MaxVslUnitless "- SPN Position Changed";
CM_ BO_ 2365575713 "- Transmission Rate [ms] can be: 50 / 1000 / OnChange
- SIU.B.SAS..27..VDB: Faster Transmission Rate till wakeup (2s max), then every 1s when active. First message to be sent, as soon as possible.";
CM_ BO_ 2566892573 "- Sent 10 times each 2 seconds. SGW will stop the transmission when PB_SecureLog_4A is received";
CM_ BO_ 2566885148 "- Fonction ISA (ADCU requested)";
CM_ BO_ 2566898670 "- Multipacket message handled by SAE Transport Protocol (J1939/21, par 5.10, Multipacket Broadcast with TP.CM/BAM, TP.DT)
-  Update filled in acc with DTCO4.1 (New file). TBC.";
CM_ SG_ 2566898670 Driv1Id_FFC3EE "- Signal length 112 bits (14 ASCII chars)";
CM_ BO_ 2566898926 "- TbC";
CM_ SG_ 2566898926 PrintDrawSts "- Driver1 - additional information";
CM_ SG_ 2566898926 EndOfLifeDriv1CardAlert "- Driver1 - additional information";
CM_ SG_ 2566898926 Driv1CardDwlAlert "- Driver1 - additional information";
CM_ BO_ 2566899694 "- Update filled in acc with DTCO4.1 (New file). TBC.";
CM_ SG_ 2566899694 AvCnt "- Currently not used";
CM_ SG_ 2566899694 WorkCnt "- Currently not used";
CM_ SG_ 2566899694 DrivCnt "- Currently not used";
CM_ SG_ 2566899694 TwoWeeksTotOdo "- Currently not used";
CM_ SG_ 2566899694 WeekTotOdo "- Currently not used";
CM_ SG_ 2566899694 DayOdo "- Currently not used";
CM_ SG_ 2566899694 DayRestPer7Flag "- 1b also when the info is Not Available";
CM_ SG_ 2566899694 DayRestPer6Flag "- 1b also when the info is Not Available";
CM_ SG_ 2566899694 DayRestPer5Flag "- 1b also when the info is Not Available";
CM_ SG_ 2566899694 DayRestPer4Flag "- 1b also when the info is Not Available";
CM_ SG_ 2566899694 DayRestPer3Flag "- 1b also when the info is Not Available";
CM_ SG_ 2566899694 DayRestPer2Flag "- 1b also when the info is Not Available";
CM_ SG_ 2566899694 DayRestPer1Flag "- 1b also when the info is Not Available";
CM_ SG_ 2566899694 DayDrivTimeShift6Flag "- 1b also when the info is Not Available";
CM_ SG_ 2566899694 DayDrivTimeShift5Flag "- 1b also when the info is Not Available";
CM_ SG_ 2566899694 DayDrivTimeShift4Flag "- 1b also when the info is Not Available";
CM_ SG_ 2566899694 DayDrivTimeShift3Flag "- 1b also when the info is Not Available";
CM_ SG_ 2566899694 DayDrivTimeShift2Flag "- 1b also when the info is Not Available";
CM_ SG_ 2566899694 DayDrivTimeShift1Flag "- 1b also when the info is Not Available";
CM_ SG_ 2566899694 DayDrivTimeFlag "- 1b also when the info is Not Available";
CM_ BO_ 2650771712 "- Telemetry purpose. NEF CNG only";
CM_ BO_ 2650771968 "- Telemetry purpose. NEF CNG only";
CM_ BO_ 2650766848 "- Telemetry purpose. NEF CNG only";
BA_DEF_ BO_  "CI_MsgDefinition" STRING ;
BA_DEF_ BO_  "CI_MsgId" INT 0 2147483647;
BA_DEF_ BO_  "CI_MsgName" STRING ;
BA_DEF_ BO_  "GenMsgCycleTime" INT 0 3600000;
BA_DEF_ BO_  "GenMsgCycleTimeFast" INT 0 3600000;
BA_DEF_ BO_  "GenMsgDelayTime" INT 0 3600000;
BA_DEF_ BO_  "GenMsgILSupport" ENUM  "No","Yes";
BA_DEF_ BO_  "GenMsgNrOfRepetition" INT 0 1000000;
BA_DEF_ BO_  "GenMsgRequestable" INT 0 1;
BA_DEF_ BO_  "GenMsgSendType" ENUM  "cyclic","NotUsed","NotUsed","NotUsed","NotUsed","NotUsed","NotUsed","IfActive","noMsgSendType";
BA_DEF_ BO_  "GenMsgStartDelayTime" INT 0 100000;
BA_DEF_ BO_  "TpJ1939VarDlc" ENUM  "No","Yes";
BA_DEF_ BO_  "VFrameFormat" ENUM  "StandardCAN","ExtendedCAN","reserved","J1939PG";
BA_DEF_ SG_  "CI_ParId" STRING ;
BA_DEF_ SG_  "CI_SigId" INT 0 2147483647;
BA_DEF_ SG_  "CI_SigName" STRING ;
BA_DEF_ SG_  "GenSigEVName" STRING ;
BA_DEF_ SG_  "GenSigILSupport" ENUM  "No","Yes";
BA_DEF_ SG_  "GenSigInactiveValue" INT 0 2147483647;
BA_DEF_ SG_  "GenSigSendType" ENUM  "Cyclic","OnWrite","OnWriteWithRepetition","OnChange","OnChangeWithRepetition","IfActive","IfActiveWithRepetition","NoSigSendType";
BA_DEF_ SG_  "GenSigStartValue" INT 0 2147483647;
BA_DEF_ SG_  "GenSigTimeoutTime_ACM_CANAIR" INT 0 3600000;
BA_DEF_ SG_  "GenSigTimeoutTime_ACU" INT 0 3600000;
BA_DEF_ SG_  "GenSigTimeoutTime_ADCU" INT 0 3600000;
BA_DEF_ SG_  "GenSigTimeoutTime_AI_CAID" INT 0 3600000;
BA_DEF_ SG_  "GenSigTimeoutTime_ASM_ELC5_Fr" INT 0 3600000;
BA_DEF_ SG_  "GenSigTimeoutTime_AVAS" INT 0 3600000;
BA_DEF_ SG_  "GenSigTimeoutTime_Av2HP" INT 0 3600000;
BA_DEF_ SG_  "GenSigTimeoutTime_BCM_NBM" INT 0 3600000;
BA_DEF_ SG_  "GenSigTimeoutTime_BSM_EBS" INT 0 3600000;
BA_DEF_ SG_  "GenSigTimeoutTime_DICO" INT 0 3600000;
BA_DEF_ SG_  "GenSigTimeoutTime_DMS" INT 0 3600000;
BA_DEF_ SG_  "GenSigTimeoutTime_EBS_EBR" INT 0 3600000;
BA_DEF_ SG_  "GenSigTimeoutTime_ECM_MD1_D" INT 0 3600000;
BA_DEF_ SG_  "GenSigTimeoutTime_ECM_MD1_G" INT 0 3600000;
BA_DEF_ SG_  "GenSigTimeoutTime_ETC_DiwaNXT" INT 0 3600000;
BA_DEF_ SG_  "GenSigTimeoutTime_ETC_DiwaNXT_MH" INT 0 3600000;
BA_DEF_ SG_  "GenSigTimeoutTime_ETC_Ecolife2" INT 0 3600000;
BA_DEF_ SG_  "GenSigTimeoutTime_FCCU" INT 0 3600000;
BA_DEF_ SG_  "GenSigTimeoutTime_FMS_FMS4" INT 0 3600000;
BA_DEF_ SG_  "GenSigTimeoutTime_FMS_FMS5" INT 0 3600000;
BA_DEF_ SG_  "GenSigTimeoutTime_HVPDU_HV_BOX" INT 0 3600000;
BA_DEF_ SG_  "GenSigTimeoutTime_IC_MulticII" INT 0 3600000;
BA_DEF_ SG_  "GenSigTimeoutTime_IC_MulticS" INT 0 3600000;
BA_DEF_ SG_  "GenSigTimeoutTime_INVEM1_ELFA3" INT 0 3600000;
BA_DEF_ SG_  "GenSigTimeoutTime_MBMS" INT 0 3600000;
BA_DEF_ SG_  "GenSigTimeoutTime_MCSL" INT 0 3600000;
BA_DEF_ SG_  "GenSigTimeoutTime_MPPxPTFE2" INT 0 3600000;
BA_DEF_ SG_  "GenSigTimeoutTime_PCM" INT 0 3600000;
BA_DEF_ SG_  "GenSigTimeoutTime_RDAB_SmtRadio" INT 0 3600000;
BA_DEF_ SG_  "GenSigTimeoutTime_RM_INTD" INT 0 3600000;
BA_DEF_ SG_  "GenSigTimeoutTime_RM_IRCS" INT 0 3600000;
BA_DEF_ SG_  "GenSigTimeoutTime_SAS" INT 0 3600000;
BA_DEF_ SG_  "GenSigTimeoutTime_SGW" INT 0 3600000;
BA_DEF_ SG_  "GenSigTimeoutTime_SGW2" INT 0 3600000;
BA_DEF_ SG_  "GenSigTimeoutTime_TASM_ETS" INT 0 3600000;
BA_DEF_ SG_  "GenSigTimeoutTime_TMU_HP_Fr" INT 0 3600000;
BA_DEF_ SG_  "GenSigTimeoutTime_TMU_HP_Rr" INT 0 3600000;
BA_DEF_ SG_  "GenSigTimeoutTime_TPMS" INT 0 3600000;
BA_DEF_ SG_  "GenSigTimeoutTime_Tacho_DTCO" INT 0 3600000;
BA_DEF_ SG_  "GenSigTimeoutTime_Tacho_MTCO" INT 0 3600000;
BA_DEF_ SG_  "GenSigTimeoutTime_Tacho_TSU" INT 0 3600000;
BA_DEF_ SG_  "GenSigTimeoutTime_VCM" INT 0 3600000;
BA_DEF_ SG_  "GenSigTimeoutTime_VCU" INT 0 3600000;
BA_DEF_ SG_  "GenSigTimeoutTime_VMU" INT 0 3600000;
BA_DEF_ SG_  "SPN" INT 0 524287;
BA_DEF_ SG_  "SigType" ENUM  "Default","Range","RangeSigned","ASCII","Discrete","Control","ReferencePGN","DTC","StringDelimiter","StringLength","StringLengthControl";
BA_DEF_DEF_  "CI_MsgDefinition" "";
BA_DEF_DEF_  "CI_MsgId" 0;
BA_DEF_DEF_  "CI_MsgName" "";
BA_DEF_DEF_  "GenMsgCycleTime" 0;
BA_DEF_DEF_  "GenMsgCycleTimeFast" 0;
BA_DEF_DEF_  "GenMsgDelayTime" 1;
BA_DEF_DEF_  "GenMsgILSupport" "Yes";
BA_DEF_DEF_  "GenMsgNrOfRepetition" 0;
BA_DEF_DEF_  "GenMsgRequestable" 0;
BA_DEF_DEF_  "GenMsgSendType" "noMsgSendType";
BA_DEF_DEF_  "GenMsgStartDelayTime" 0;
BA_DEF_DEF_  "TpJ1939VarDlc" "No";
BA_DEF_DEF_  "VFrameFormat" "J1939PG";
BA_DEF_DEF_  "CI_ParId" "";
BA_DEF_DEF_  "CI_SigId" 0;
BA_DEF_DEF_  "CI_SigName" "";
BA_DEF_DEF_  "GenSigEVName" "Env@Nodename_@Signame";
BA_DEF_DEF_  "GenSigILSupport" "Yes";
BA_DEF_DEF_  "GenSigInactiveValue" 0;
BA_DEF_DEF_  "GenSigSendType" "NoSigSendType";
BA_DEF_DEF_  "GenSigStartValue" 0;
BA_DEF_DEF_  "GenSigTimeoutTime_ACM_CANAIR" 0;
BA_DEF_DEF_  "GenSigTimeoutTime_ACU" 0;
BA_DEF_DEF_  "GenSigTimeoutTime_ADCU" 0;
BA_DEF_DEF_  "GenSigTimeoutTime_AI_CAID" 0;
BA_DEF_DEF_  "GenSigTimeoutTime_ASM_ELC5_Fr" 0;
BA_DEF_DEF_  "GenSigTimeoutTime_AVAS" 0;
BA_DEF_DEF_  "GenSigTimeoutTime_Av2HP" 0;
BA_DEF_DEF_  "GenSigTimeoutTime_BCM_NBM" 0;
BA_DEF_DEF_  "GenSigTimeoutTime_BSM_EBS" 0;
BA_DEF_DEF_  "GenSigTimeoutTime_DICO" 0;
BA_DEF_DEF_  "GenSigTimeoutTime_DMS" 0;
BA_DEF_DEF_  "GenSigTimeoutTime_EBS_EBR" 0;
BA_DEF_DEF_  "GenSigTimeoutTime_ECM_MD1_D" 0;
BA_DEF_DEF_  "GenSigTimeoutTime_ECM_MD1_G" 0;
BA_DEF_DEF_  "GenSigTimeoutTime_ETC_DiwaNXT" 0;
BA_DEF_DEF_  "GenSigTimeoutTime_ETC_DiwaNXT_MH" 0;
BA_DEF_DEF_  "GenSigTimeoutTime_ETC_Ecolife2" 0;
BA_DEF_DEF_  "GenSigTimeoutTime_FCCU" 0;
BA_DEF_DEF_  "GenSigTimeoutTime_FMS_FMS4" 0;
BA_DEF_DEF_  "GenSigTimeoutTime_FMS_FMS5" 0;
BA_DEF_DEF_  "GenSigTimeoutTime_HVPDU_HV_BOX" 0;
BA_DEF_DEF_  "GenSigTimeoutTime_IC_MulticII" 0;
BA_DEF_DEF_  "GenSigTimeoutTime_IC_MulticS" 0;
BA_DEF_DEF_  "GenSigTimeoutTime_INVEM1_ELFA3" 0;
BA_DEF_DEF_  "GenSigTimeoutTime_MBMS" 0;
BA_DEF_DEF_  "GenSigTimeoutTime_MCSL" 0;
BA_DEF_DEF_  "GenSigTimeoutTime_MPPxPTFE2" 0;
BA_DEF_DEF_  "GenSigTimeoutTime_PCM" 0;
BA_DEF_DEF_  "GenSigTimeoutTime_RDAB_SmtRadio" 0;
BA_DEF_DEF_  "GenSigTimeoutTime_RM_INTD" 0;
BA_DEF_DEF_  "GenSigTimeoutTime_RM_IRCS" 0;
BA_DEF_DEF_  "GenSigTimeoutTime_SAS" 0;
BA_DEF_DEF_  "GenSigTimeoutTime_SGW" 0;
BA_DEF_DEF_  "GenSigTimeoutTime_SGW2" 0;
BA_DEF_DEF_  "GenSigTimeoutTime_TASM_ETS" 0;
BA_DEF_DEF_  "GenSigTimeoutTime_TMU_HP_Fr" 0;
BA_DEF_DEF_  "GenSigTimeoutTime_TMU_HP_Rr" 0;
BA_DEF_DEF_  "GenSigTimeoutTime_TPMS" 0;
BA_DEF_DEF_  "GenSigTimeoutTime_Tacho_DTCO" 0;
BA_DEF_DEF_  "GenSigTimeoutTime_Tacho_MTCO" 0;
BA_DEF_DEF_  "GenSigTimeoutTime_Tacho_TSU" 0;
BA_DEF_DEF_  "GenSigTimeoutTime_VCM" 0;
BA_DEF_DEF_  "GenSigTimeoutTime_VCU" 0;
BA_DEF_DEF_  "GenSigTimeoutTime_VMU" 0;
BA_DEF_DEF_  "SPN" 0;
BA_DEF_DEF_  "SigType" "Default";
BA_ "GenMsgSendType" BO_ 2364539395 0;
BA_ "GenMsgDelayTime" BO_ 2364539395 5;
BA_ "GenMsgCycleTimeFast" BO_ 2364539395 10;
BA_ "GenMsgCycleTime" BO_ 2364539395 10;
BA_ "CI_MsgName" BO_ 2364539395 "ETC1 - Electronic Transmission Controller 1";
BA_ "CI_MsgId" BO_ 2364539395 529;
BA_ "CI_MsgDefinition" BO_ 2364539395 "J1939DA";
BA_ "GenMsgStartDelayTime" BO_ 2565866755 8;
BA_ "GenMsgSendType" BO_ 2565866755 0;
BA_ "GenMsgDelayTime" BO_ 2565866755 50;
BA_ "GenMsgCycleTimeFast" BO_ 2565866755 100;
BA_ "GenMsgCycleTime" BO_ 2565866755 100;
BA_ "CI_MsgName" BO_ 2565866755 "ETC2 - Electronic Transmission Controller 2";
BA_ "CI_MsgId" BO_ 2565866755 541;
BA_ "CI_MsgDefinition" BO_ 2565866755 "J1939DA";
BA_ "GenMsgStartDelayTime" BO_ 2566826755 29;
BA_ "GenMsgSendType" BO_ 2566826755 0;
BA_ "GenMsgDelayTime" BO_ 2566826755 125;
BA_ "GenMsgCycleTimeFast" BO_ 2566826755 250;
BA_ "GenMsgCycleTime" BO_ 2566826755 250;
BA_ "CI_MsgName" BO_ 2566826755 "ETC6_P6 - Electronic Transmission Controller 6";
BA_ "CI_MsgId" BO_ 2566826755 564;
BA_ "CI_MsgDefinition" BO_ 2566826755 "J1939DA";
BA_ "GenMsgStartDelayTime" BO_ 2364541955 9;
BA_ "GenMsgSendType" BO_ 2364541955 0;
BA_ "GenMsgDelayTime" BO_ 2364541955 10;
BA_ "GenMsgCycleTimeFast" BO_ 2364541955 20;
BA_ "GenMsgCycleTime" BO_ 2364541955 100;
BA_ "CI_MsgName" BO_ 2364541955 "ETC8 - Electronic Transmission Controller #8";
BA_ "CI_MsgId" BO_ 2364541955 625;
BA_ "CI_MsgDefinition" BO_ 2364541955 "J1939DA";
BA_ "GenMsgStartDelayTime" BO_ 2566831393 123;
BA_ "GenMsgSendType" BO_ 2566831393 0;
BA_ "GenMsgDelayTime" BO_ 2566831393 500;
BA_ "GenMsgCycleTimeFast" BO_ 2566831393 1000;
BA_ "GenMsgCycleTime" BO_ 2566831393 1000;
BA_ "CI_MsgName" BO_ 2566831393 "FD1_21 - Fan Drive #1";
BA_ "CI_MsgId" BO_ 2566831393 2180;
BA_ "CI_MsgDefinition" BO_ 2566831393 "J1939DA";
BA_ "GenMsgStartDelayTime" BO_ 2431649694 4;
BA_ "GenMsgSendType" BO_ 2431649694 0;
BA_ "GenMsgNrOfRepetition" BO_ 2431649694 4;
BA_ "GenMsgDelayTime" BO_ 2431649694 25;
BA_ "GenMsgCycleTimeFast" BO_ 2431649694 50;
BA_ "GenMsgCycleTime" BO_ 2431649694 50;
BA_ "CI_MsgName" BO_ 2431649694 "FLI1_9E - Forward Lane Image 1";
BA_ "CI_MsgId" BO_ 2431649694 3104;
BA_ "CI_MsgDefinition" BO_ 2431649694 "J1939DA";
BA_ "GenMsgStartDelayTime" BO_ 2566806430 8;
BA_ "GenMsgSendType" BO_ 2566806430 0;
BA_ "GenMsgDelayTime" BO_ 2566806430 50;
BA_ "GenMsgCycleTimeFast" BO_ 2566806430 100;
BA_ "GenMsgCycleTime" BO_ 2566806430 100;
BA_ "CI_MsgName" BO_ 2566806430 "FLI2_9E - Forward Lane Image 2";
BA_ "CI_MsgId" BO_ 2566806430 3118;
BA_ "CI_MsgDefinition" BO_ 2566806430 "J1939DA";
BA_ "GenMsgStartDelayTime" BO_ 2566841600 38;
BA_ "GenMsgSendType" BO_ 2566841600 0;
BA_ "GenMsgDelayTime" BO_ 2566841600 500;
BA_ "GenMsgCycleTimeFast" BO_ 2566841600 1000;
BA_ "GenMsgCycleTime" BO_ 2566841600 1000;
BA_ "CI_MsgName" BO_ 2566841600 "HOURS - Engine Hours, Revolutions";
BA_ "CI_MsgId" BO_ 2566841600 1093;
BA_ "CI_MsgDefinition" BO_ 2566841600 "J1939DA";
BA_ "GenMsgStartDelayTime" BO_ 2566719744 44;
BA_ "GenMsgSendType" BO_ 2566719744 0;
BA_ "GenMsgDelayTime" BO_ 2566719744 500;
BA_ "GenMsgCycleTimeFast" BO_ 2566719744 1000;
BA_ "GenMsgCycleTime" BO_ 2566719744 1000;
BA_ "CI_MsgName" BO_ 2566719744 "HRLFC - High Resolution Fuel Consumption (Liquid)";
BA_ "CI_MsgId" BO_ 2566719744 1147;
BA_ "CI_MsgDefinition" BO_ 2566719744 "J1939DA";
BA_ "GenMsgStartDelayTime" BO_ 2566837793 57;
BA_ "GenMsgSendType" BO_ 2566837793 0;
BA_ "GenMsgDelayTime" BO_ 2566837793 50;
BA_ "GenMsgCycleTimeFast" BO_ 2566837793 100;
BA_ "GenMsgCycleTime" BO_ 2566837793 100;
BA_ "CI_MsgName" BO_ 2566837793 "HSI1_21 - Hybrid System Inputs 1";
BA_ "CI_MsgId" BO_ 2566837793 2221;
BA_ "CI_MsgDefinition" BO_ 2566837793 "J1939DA";
BA_ "GenMsgStartDelayTime" BO_ 2566701658 14;
BA_ "GenMsgSendType" BO_ 2566701658 0;
BA_ "GenMsgDelayTime" BO_ 2566701658 100;
BA_ "GenMsgCycleTimeFast" BO_ 2566701658 100;
BA_ "GenMsgCycleTime" BO_ 2566701658 100;
BA_ "CI_MsgName" BO_ 2566701658 "HSS1_5A - Hybrid System Status 1";
BA_ "CI_MsgId" BO_ 2566701658 2233;
BA_ "CI_MsgDefinition" BO_ 2566701658 "J1939DA";
BA_ "GenMsgStartDelayTime" BO_ 2566698842 30;
BA_ "GenMsgSendType" BO_ 2566698842 0;
BA_ "GenMsgDelayTime" BO_ 2566698842 500;
BA_ "GenMsgCycleTimeFast" BO_ 2566698842 1000;
BA_ "GenMsgCycleTime" BO_ 2566698842 1000;
BA_ "CI_MsgName" BO_ 2566698842 "HSS2_5A - Hybrid System Status 2";
BA_ "CI_MsgId" BO_ 2566698842 2275;
BA_ "CI_MsgDefinition" BO_ 2566698842 "J1939DA";
BA_ "GenMsgStartDelayTime" BO_ 2566850819 27;
BA_ "GenMsgSendType" BO_ 2566850819 0;
BA_ "GenMsgDelayTime" BO_ 2566850819 50;
BA_ "GenMsgCycleTimeFast" BO_ 2566850819 100;
BA_ "GenMsgCycleTime" BO_ 2566850819 100;
BA_ "CI_MsgName" BO_ 2566850819 "HTCU2BC_03 - HTCU to BC (Mild Hybrid)";
BA_ "CI_MsgId" BO_ 2566850819 2278;
BA_ "CI_MsgDefinition" BO_ 2566850819 "FPT Proprietary";
BA_ "GenMsgStartDelayTime" BO_ 2566851075 22;
BA_ "GenMsgSendType" BO_ 2566851075 0;
BA_ "GenMsgDelayTime" BO_ 2566851075 150;
BA_ "GenMsgCycleTimeFast" BO_ 2566851075 300;
BA_ "GenMsgCycleTime" BO_ 2566851075 300;
BA_ "CI_MsgName" BO_ 2566851075 "HTCU2PM_1 - HTCU 2 PREDICTIVE MAINTENANCE #1";
BA_ "CI_MsgId" BO_ 2566851075 2306;
BA_ "CI_MsgDefinition" BO_ 2566851075 "Iveco Proprietary";
BA_ "GenMsgStartDelayTime" BO_ 2566851331 36;
BA_ "GenMsgSendType" BO_ 2566851331 0;
BA_ "GenMsgDelayTime" BO_ 2566851331 150;
BA_ "GenMsgCycleTimeFast" BO_ 2566851331 300;
BA_ "GenMsgCycleTime" BO_ 2566851331 300;
BA_ "CI_MsgName" BO_ 2566851331 "HTCU2PM_2 - HTCU 2 PREDICTIVE MAINTENANCE #2";
BA_ "CI_MsgId" BO_ 2566851331 2312;
BA_ "CI_MsgDefinition" BO_ 2566851331 "Iveco Proprietary";
BA_ "GenMsgStartDelayTime" BO_ 2566851843 24;
BA_ "GenMsgSendType" BO_ 2566851843 0;
BA_ "GenMsgDelayTime" BO_ 2566851843 150;
BA_ "GenMsgCycleTimeFast" BO_ 2566851843 300;
BA_ "GenMsgCycleTime" BO_ 2566851843 300;
BA_ "CI_MsgName" BO_ 2566851843 "HTCU2PM_3 - HTCU 2 PREDICTIVE MAINTENANCE #3";
BA_ "CI_MsgId" BO_ 2566851843 2319;
BA_ "CI_MsgDefinition" BO_ 2566851843 "Iveco Proprietary";
BA_ "GenMsgStartDelayTime" BO_ 2566891136 34;
BA_ "GenMsgSendType" BO_ 2566891136 0;
BA_ "GenMsgDelayTime" BO_ 2566891136 500;
BA_ "GenMsgCycleTimeFast" BO_ 2566891136 1000;
BA_ "GenMsgCycleTime" BO_ 2566891136 1000;
BA_ "CI_MsgName" BO_ 2566891136 "HVBoxOppSt - HV-Box opportunity contactor state";
BA_ "CI_MsgId" BO_ 2566891136 1374;
BA_ "CI_MsgDefinition" BO_ 2566891136 "Iveco Proprietary";
BA_ "GenMsgStartDelayTime" BO_ 2566890880 32;
BA_ "GenMsgSendType" BO_ 2566890880 0;
BA_ "GenMsgDelayTime" BO_ 2566890880 500;
BA_ "GenMsgCycleTimeFast" BO_ 2566890880 1000;
BA_ "GenMsgCycleTime" BO_ 2566890880 1000;
BA_ "CI_MsgName" BO_ 2566890880 "HVBoxOvnSt - HV-Box overnight contactor state";
BA_ "CI_MsgId" BO_ 2566890880 1381;
BA_ "CI_MsgDefinition" BO_ 2566890880 "Iveco Proprietary";
BA_ "GenMsgStartDelayTime" BO_ 2566890368 46;
BA_ "GenMsgSendType" BO_ 2566890368 0;
BA_ "GenMsgDelayTime" BO_ 2566890368 2500;
BA_ "GenMsgCycleTimeFast" BO_ 2566890368 5000;
BA_ "GenMsgCycleTime" BO_ 2566890368 5000;
BA_ "CI_MsgName" BO_ 2566890368 "HVBoxSOHSt - Contactor SOH (state of health)";
BA_ "CI_MsgId" BO_ 2566890368 1388;
BA_ "CI_MsgDefinition" BO_ 2566890368 "Iveco Proprietary";
BA_ "GenMsgStartDelayTime" BO_ 2364575834 28;
BA_ "GenMsgSendType" BO_ 2364575834 0;
BA_ "GenMsgDelayTime" BO_ 2364575834 500;
BA_ "GenMsgCycleTimeFast" BO_ 2364575834 1000;
BA_ "GenMsgCycleTime" BO_ 2364575834 1000;
BA_ "CI_MsgName" BO_ 2364575834 "HVESSD1_5A - High Voltage Energy Storage System Data 1";
BA_ "CI_MsgId" BO_ 2364575834 2326;
BA_ "CI_MsgDefinition" BO_ 2364575834 "J1939DA";
BA_ "GenMsgStartDelayTime" BO_ 2365349619 2;
BA_ "GenMsgSendType" BO_ 2365349619 0;
BA_ "GenMsgDelayTime" BO_ 2365349619 500;
BA_ "GenMsgCycleTimeFast" BO_ 2365349619 1000;
BA_ "GenMsgCycleTime" BO_ 2365349619 1000;
BA_ "CI_MsgName" BO_ 2365349619 "HVESSHIST_F3 - Historical data for High Voltage Energy Storage System";
BA_ "CI_MsgId" BO_ 2365349619 2518;
BA_ "CI_MsgDefinition" BO_ 2365349619 "J1939DA";
BA_ "GenMsgStartDelayTime" BO_ 2566845952 18;
BA_ "GenMsgSendType" BO_ 2566845952 0;
BA_ "GenMsgDelayTime" BO_ 2566845952 50;
BA_ "GenMsgCycleTimeFast" BO_ 2566845952 100;
BA_ "GenMsgCycleTime" BO_ 2566845952 100;
BA_ "CI_MsgName" BO_ 2566845952 "IC1 - Intake/Exhaust Conditions 1";
BA_ "CI_MsgId" BO_ 2566845952 1097;
BA_ "CI_MsgDefinition" BO_ 2566845952 "J1939DA";
BA_ "GenMsgStartDelayTime" BO_ 2566910080 26;
BA_ "GenMsgSendType" BO_ 2566910080 0;
BA_ "GenMsgDelayTime" BO_ 2566910080 250;
BA_ "GenMsgCycleTimeFast" BO_ 2566910080 500;
BA_ "GenMsgCycleTime" BO_ 2566910080 500;
BA_ "CI_MsgName" BO_ 2566910080 "InfPow1 - Power information 1 from driveline";
BA_ "CI_MsgId" BO_ 2566910080 1120;
BA_ "CI_MsgDefinition" BO_ 2566910080 "Iveco Proprietary";
BA_ "GenMsgStartDelayTime" BO_ 2566909824 52;
BA_ "GenMsgSendType" BO_ 2566909824 0;
BA_ "GenMsgDelayTime" BO_ 2566909824 500;
BA_ "GenMsgCycleTimeFast" BO_ 2566909824 1000;
BA_ "GenMsgCycleTime" BO_ 2566909824 1000;
BA_ "CI_MsgName" BO_ 2566909824 "InfPow2 - Power information 2 from driveline";
BA_ "CI_MsgId" BO_ 2566909824 1129;
BA_ "CI_MsgDefinition" BO_ 2566909824 "Iveco Proprietary";
BA_ "GenMsgStartDelayTime" BO_ 2566786839 72;
BA_ "GenMsgSendType" BO_ 2566786839 0;
BA_ "GenMsgDelayTime" BO_ 2566786839 500;
BA_ "GenMsgCycleTimeFast" BO_ 2566786839 1000;
BA_ "GenMsgCycleTime" BO_ 2566786839 1000;
BA_ "CI_MsgName" BO_ 2566786839 "LC_17 - Language Command";
BA_ "CI_MsgId" BO_ 2566786839 2644;
BA_ "CI_MsgDefinition" BO_ 2566786839 "ISO11783-7";
BA_ "GenMsgStartDelayTime" BO_ 2566842624 56;
BA_ "GenMsgSendType" BO_ 2566842624 0;
BA_ "GenMsgDelayTime" BO_ 2566842624 500;
BA_ "GenMsgCycleTimeFast" BO_ 2566842624 1000;
BA_ "GenMsgCycleTime" BO_ 2566842624 1000;
BA_ "CI_MsgName" BO_ 2566842624 "LFC - Fuel Consumption (Liquid)";
BA_ "CI_MsgId" BO_ 2566842624 1105;
BA_ "CI_MsgDefinition" BO_ 2566842624 "J1939DA";
BA_ "GenMsgStartDelayTime" BO_ 2566844928 15;
BA_ "GenMsgSendType" BO_ 2566844928 0;
BA_ "GenMsgDelayTime" BO_ 2566844928 50;
BA_ "GenMsgCycleTimeFast" BO_ 2566844928 100;
BA_ "GenMsgCycleTime" BO_ 2566844928 100;
BA_ "CI_MsgName" BO_ 2566844928 "LFE - Fuel Economy";
BA_ "CI_MsgId" BO_ 2566844928 1172;
BA_ "CI_MsgDefinition" BO_ 2566844928 "J1939DA";
BA_ "GenMsgStartDelayTime" BO_ 2566861299 30;
BA_ "GenMsgSendType" BO_ 2566861299 0;
BA_ "GenMsgDelayTime" BO_ 2566861299 2500;
BA_ "GenMsgCycleTimeFast" BO_ 2566861299 5000;
BA_ "GenMsgCycleTime" BO_ 2566861299 5000;
BA_ "CI_MsgName" BO_ 2566861299 "MBMS2SCU1_F3 - ABMS";
BA_ "CI_MsgId" BO_ 2566861299 1481;
BA_ "CI_MsgDefinition" BO_ 2566861299 "Iveco Bus Proprietary";
BA_ "GenMsgStartDelayTime" BO_ 2566861351 18;
BA_ "GenMsgSendType" BO_ 2566861351 0;
BA_ "GenMsgDelayTime" BO_ 2566861351 500;
BA_ "GenMsgCycleTimeFast" BO_ 2566861351 1000;
BA_ "GenMsgCycleTime" BO_ 2566861351 1000;
BA_ "CI_MsgName" BO_ 2566861351 "MBMS2SCU2_27 - ABMS1";
BA_ "CI_MsgId" BO_ 2566861351 1516;
BA_ "CI_MsgDefinition" BO_ 2566861351 "Iveco Bus Proprietary";
BA_ "GenMsgStartDelayTime" BO_ 2566861555 36;
BA_ "GenMsgSendType" BO_ 2566861555 0;
BA_ "GenMsgDelayTime" BO_ 2566861555 2500;
BA_ "GenMsgCycleTimeFast" BO_ 2566861555 5000;
BA_ "GenMsgCycleTime" BO_ 2566861555 5000;
BA_ "CI_MsgName" BO_ 2566861555 "MBMS2SCU2_F3 - ABMS1";
BA_ "CI_MsgId" BO_ 2566861555 1507;
BA_ "CI_MsgDefinition" BO_ 2566861555 "Iveco Bus Proprietary";
BA_ "GenMsgStartDelayTime" BO_ 2365554927 2;
BA_ "GenMsgSendType" BO_ 2365554927 0;
BA_ "GenMsgDelayTime" BO_ 2365554927 5;
BA_ "GenMsgCycleTimeFast" BO_ 2365554927 10;
BA_ "GenMsgCycleTime" BO_ 2365554927 10;
BA_ "CI_MsgName" BO_ 2365554927 "MecFdbTU1 - MecFeedbackTractUnit1";
BA_ "CI_MsgId" BO_ 2365554927 1406;
BA_ "CI_MsgDefinition" BO_ 2365554927 "Iveco Proprietary";
BA_ "GenMsgStartDelayTime" BO_ 2566878241 78;
BA_ "GenMsgSendType" BO_ 2566878241 0;
BA_ "GenMsgDelayTime" BO_ 2566878241 50;
BA_ "GenMsgCycleTimeFast" BO_ 2566878241 100;
BA_ "GenMsgCycleTime" BO_ 2566878241 100;
BA_ "CI_MsgName" BO_ 2566878241 "MUX2VCU_FC - MUX2VCU_FuelCell";
BA_ "CI_MsgId" BO_ 2566878241 18957;
BA_ "CI_MsgDefinition" BO_ 2566878241 "Iveco Bus Proprietary";
BA_ "GenMsgStartDelayTime" BO_ 2566776097 111;
BA_ "GenMsgSendType" BO_ 2566776097 0;
BA_ "GenMsgDelayTime" BO_ 2566776097 500;
BA_ "GenMsgCycleTimeFast" BO_ 2566776097 1000;
BA_ "GenMsgCycleTime" BO_ 2566776097 1000;
BA_ "CI_MsgName" BO_ 2566776097 "MVS_21 - Maximum Vehicle Speed Limit Status";
BA_ "CI_MsgId" BO_ 2566776097 2175;
BA_ "CI_MsgDefinition" BO_ 2566776097 "J1939DA";
BA_ "GenMsgStartDelayTime" BO_ 2365443105 87;
BA_ "GenMsgSendType" BO_ 2365443105 0;
BA_ "GenMsgDelayTime" BO_ 2365443105 100;
BA_ "GenMsgCycleTimeFast" BO_ 2365443105 250;
BA_ "GenMsgCycleTime" BO_ 2365443105 250;
BA_ "CI_MsgName" BO_ 2365443105 "OEL - Operators External Light Controls Message";
BA_ "CI_MsgId" BO_ 2365443105 2626;
BA_ "CI_MsgDefinition" BO_ 2365443105 "J1939DA";
BA_ "GenMsgStartDelayTime" BO_ 2566769953 106;
BA_ "GenMsgSendType" BO_ 2566769953 0;
BA_ "GenMsgDelayTime" BO_ 2566769953 100;
BA_ "GenMsgCycleTimeFast" BO_ 2566769953 1000;
BA_ "GenMsgCycleTime" BO_ 2566769953 1000;
BA_ "CI_MsgName" BO_ 2566769953 "OWW_21 - Operator Wiper and Washer Controls Message";
BA_ "CI_MsgId" BO_ 2566769953 2634;
BA_ "CI_MsgDefinition" BO_ 2566769953 "J1939DA";
BA_ "GenMsgStartDelayTime" BO_ 2633959399 2;
BA_ "GenMsgSendType" BO_ 2633959399 0;
BA_ "GenMsgDelayTime" BO_ 2633959399 50;
BA_ "GenMsgCycleTimeFast" BO_ 2633959399 100;
BA_ "GenMsgCycleTime" BO_ 2633959399 100;
BA_ "CI_MsgName" BO_ 2633959399 "PB_ACU - Articulation";
BA_ "CI_MsgId" BO_ 2633959399 12749;
BA_ "CI_MsgDefinition" BO_ 2633959399 "Iveco Proprietary";
BA_ "GenMsgSendType" BO_ 2566850535 0;
BA_ "GenMsgDelayTime" BO_ 2566850535 50;
BA_ "GenMsgCycleTimeFast" BO_ 2566850535 100;
BA_ "GenMsgCycleTime" BO_ 2566850535 100;
BA_ "CI_MsgName" BO_ 2566850535 "PB_ACU_E7 - Articulation";
BA_ "CI_MsgId" BO_ 2566850535 12740;
BA_ "CI_MsgDefinition" BO_ 2566850535 "Iveco Proprietary";
BA_ "GenMsgStartDelayTime" BO_ 2566908574 12;
BA_ "GenMsgSendType" BO_ 2566908574 0;
BA_ "GenMsgDelayTime" BO_ 2566908574 100;
BA_ "GenMsgCycleTimeFast" BO_ 2566908574 200;
BA_ "GenMsgCycleTime" BO_ 2566908574 200;
BA_ "CI_MsgName" BO_ 2566908574 "PB_AIDI_9E - Proprietary B - Alcohol Interlock and Driver Information";
BA_ "CI_MsgId" BO_ 2566908574 627;
BA_ "CI_MsgDefinition" BO_ 2566908574 "Iveco Proprietary";
BA_ "GenMsgStartDelayTime" BO_ 2583638515 24;
BA_ "GenMsgSendType" BO_ 2583638515 0;
BA_ "GenMsgDelayTime" BO_ 2583638515 750;
BA_ "GenMsgCycleTimeFast" BO_ 2583638515 1500;
BA_ "GenMsgCycleTime" BO_ 2583638515 1500;
BA_ "CI_MsgName" BO_ 2583638515 "PB_E2E_HVESSHIST1_F3 - Proprietary B - High Voltage Energy Storage System History 1";
BA_ "CI_MsgId" BO_ 2583638515 21475;
BA_ "CI_MsgDefinition" BO_ 2583638515 "Iveco Proprietary";
BA_ "GenMsgStartDelayTime" BO_ 2566907159 58;
BA_ "GenMsgSendType" BO_ 2566907159 0;
BA_ "GenMsgDelayTime" BO_ 2566907159 50;
BA_ "GenMsgCycleTimeFast" BO_ 2566907159 100;
BA_ "GenMsgCycleTime" BO_ 2566907159 100;
BA_ "CI_MsgName" BO_ 2566907159 "PB_GSRC_17 - Proprietary B - GSR Content";
BA_ "CI_MsgId" BO_ 2566907159 4018;
BA_ "CI_MsgDefinition" BO_ 2566907159 "Iveco Proprietary";
BA_ "GenMsgSendType" BO_ 2583638259 0;
BA_ "GenMsgDelayTime" BO_ 2583638259 125;
BA_ "GenMsgCycleTimeFast" BO_ 2583638259 250;
BA_ "GenMsgCycleTime" BO_ 2583638259 250;
BA_ "CI_MsgName" BO_ 2583638259 "PB_HVESSD1_F3 - Proprietary B - High Voltage Energy Storage System Data 1";
BA_ "CI_MsgId" BO_ 2583638259 21372;
BA_ "CI_MsgDefinition" BO_ 2583638259 "Iveco Proprietary";
BA_ "GenMsgStartDelayTime" BO_ 2650750451 22;
BA_ "GenMsgSendType" BO_ 2650750451 0;
BA_ "GenMsgDelayTime" BO_ 2650750451 500;
BA_ "GenMsgCycleTimeFast" BO_ 2650750451 1500;
BA_ "GenMsgCycleTime" BO_ 2650750451 1500;
BA_ "CI_MsgName" BO_ 2650750451 "PB_HVESSHIST_F3 - Proprietary B - Historical data for High Voltage Energy Storage System";
BA_ "CI_MsgId" BO_ 2650750451 13900;
BA_ "CI_MsgDefinition" BO_ 2650750451 "Iveco Bus Proprietary";
BA_ "GenMsgStartDelayTime" BO_ 2566894871 115;
BA_ "GenMsgSendType" BO_ 2566894871 0;
BA_ "GenMsgDelayTime" BO_ 2566894871 100;
BA_ "GenMsgCycleTimeFast" BO_ 2566894871 1000;
BA_ "GenMsgCycleTime" BO_ 2566894871 1000;
BA_ "CI_MsgName" BO_ 2566894871 "PB_ISA_17 - Proprietary B - Intelligent Speed Assistant";
BA_ "CI_MsgId" BO_ 2566894871 2812;
BA_ "CI_MsgDefinition" BO_ 2566894871 "Iveco Proprietary";
BA_ "GenMsgStartDelayTime" BO_ 2566895006 22;
BA_ "GenMsgSendType" BO_ 2566895006 0;
BA_ "GenMsgDelayTime" BO_ 2566895006 100;
BA_ "GenMsgCycleTimeFast" BO_ 2566895006 1000;
BA_ "GenMsgCycleTime" BO_ 2566895006 1000;
BA_ "CI_MsgName" BO_ 2566895006 "PB_ISA_9E - Proprietary B - Intelligent Speed Assistant";
BA_ "CI_MsgId" BO_ 2566895006 2802;
BA_ "CI_MsgDefinition" BO_ 2566895006 "Iveco Proprietary";
BA_ "GenMsgStartDelayTime" BO_ 2365575713 37;
BA_ "GenMsgSendType" BO_ 2365575713 0;
BA_ "GenMsgDelayTime" BO_ 2365575713 500;
BA_ "GenMsgCycleTimeFast" BO_ 2365575713 1000;
BA_ "GenMsgCycleTime" BO_ 2365575713 1000;
BA_ "CI_MsgName" BO_ 2365575713 "PB_NmM - Proprietary B - Iveco Network Management (Master Node)";
BA_ "CI_MsgId" BO_ 2365575713 10485;
BA_ "CI_MsgDefinition" BO_ 2365575713 "Iveco SPR1 Proprietary";
BA_ "GenMsgDelayTime" BO_ 2566892573 50;
BA_ "CI_MsgName" BO_ 2566892573 "PB_SecureLog_1D - Proprietary B - Secure Log";
BA_ "CI_MsgId" BO_ 2566892573 2511;
BA_ "CI_MsgDefinition" BO_ 2566892573 "Iveco Proprietary";
BA_ "GenMsgDelayTime" BO_ 2566892618 50;
BA_ "CI_MsgName" BO_ 2566892618 "PB_SecureLog_4A - Proprietary B - Secure Log";
BA_ "CI_MsgId" BO_ 2566892618 2516;
BA_ "CI_MsgDefinition" BO_ 2566892618 "Iveco Proprietary";
BA_ "GenMsgStartDelayTime" BO_ 2566885148 164;
BA_ "GenMsgSendType" BO_ 2566885148 0;
BA_ "GenMsgDelayTime" BO_ 2566885148 500;
BA_ "GenMsgCycleTimeFast" BO_ 2566885148 1000;
BA_ "GenMsgCycleTime" BO_ 2566885148 1000;
BA_ "CI_MsgName" BO_ 2566885148 "PB_SpeedLimRelCond_1C - Proprietary B - Speed Limit Related Condition";
BA_ "CI_MsgId" BO_ 2566885148 12990;
BA_ "CI_MsgDefinition" BO_ 2566885148 "Iveco Proprietary";
BA_ "GenMsgStartDelayTime" BO_ 2566898670 55;
BA_ "GenMsgSendType" BO_ 2566898670 0;
BA_ "GenMsgDelayTime" BO_ 2566898670 1000;
BA_ "GenMsgCycleTimeFast" BO_ 2566898670 60000;
BA_ "GenMsgCycleTime" BO_ 2566898670 60000;
BA_ "CI_MsgName" BO_ 2566898670 "PB_TCO2 - TCO2 (Continental Proprietary)";
BA_ "CI_MsgId" BO_ 2566898670 745;
BA_ "CI_MsgDefinition" BO_ 2566898670 "Continental Proprietary";
BA_ "GenMsgStartDelayTime" BO_ 2566898926 49;
BA_ "GenMsgSendType" BO_ 2566898926 0;
BA_ "GenMsgDelayTime" BO_ 2566898926 5000;
BA_ "GenMsgCycleTimeFast" BO_ 2566898926 10000;
BA_ "GenMsgCycleTime" BO_ 2566898926 10000;
BA_ "CI_MsgName" BO_ 2566898926 "PB_TCO3 - TCO3 (Continental Proprietary)";
BA_ "CI_MsgId" BO_ 2566898926 752;
BA_ "CI_MsgDefinition" BO_ 2566898926 "Continental Proprietary";
BA_ "GenMsgStartDelayTime" BO_ 2566899694 57;
BA_ "GenMsgSendType" BO_ 2566899694 0;
BA_ "GenMsgDelayTime" BO_ 2566899694 1000;
BA_ "GenMsgCycleTimeFast" BO_ 2566899694 60000;
BA_ "GenMsgCycleTime" BO_ 2566899694 60000;
BA_ "CI_MsgName" BO_ 2566899694 "PB_TCO4 - Tachograph 4";
BA_ "CI_MsgId" BO_ 2566899694 759;
BA_ "CI_MsgDefinition" BO_ 2566899694 "Continental Proprietary";
BA_ "GenMsgStartDelayTime" BO_ 2650771712 72;
BA_ "GenMsgSendType" BO_ 2650771712 0;
BA_ "GenMsgDelayTime" BO_ 2650771712 2500;
BA_ "GenMsgCycleTimeFast" BO_ 2650771712 5000;
BA_ "GenMsgCycleTime" BO_ 2650771712 5000;
BA_ "CI_MsgName" BO_ 2650771712 "PB_Telemetry01 - Proprietary B - Telemetry 01";
BA_ "CI_MsgId" BO_ 2650771712 17420;
BA_ "CI_MsgDefinition" BO_ 2650771712 "Iveco Proprietary";
BA_ "GenMsgStartDelayTime" BO_ 2650771968 73;
BA_ "GenMsgSendType" BO_ 2650771968 0;
BA_ "GenMsgDelayTime" BO_ 2650771968 2500;
BA_ "GenMsgCycleTimeFast" BO_ 2650771968 5000;
BA_ "GenMsgCycleTime" BO_ 2650771968 5000;
BA_ "CI_MsgName" BO_ 2650771968 "PB_Telemetry02 - Proprietary B - Telemetry 02";
BA_ "CI_MsgId" BO_ 2650771968 17429;
BA_ "CI_MsgDefinition" BO_ 2650771968 "Iveco Proprietary";
BA_ "GenMsgStartDelayTime" BO_ 2650766848 31;
BA_ "GenMsgSendType" BO_ 2650766848 0;
BA_ "GenMsgDelayTime" BO_ 2650766848 250;
BA_ "GenMsgCycleTimeFast" BO_ 2650766848 500;
BA_ "GenMsgCycleTime" BO_ 2650766848 500;
BA_ "CI_MsgName" BO_ 2650766848 "PB_Telemetry14 - Proprietary B - Telemetry 14";
BA_ "CI_MsgId" BO_ 2650766848 17438;
BA_ "CI_MsgDefinition" BO_ 2650766848 "Iveco Proprietary";
BA_ "SigType" SG_ 2364539395 TransmInSpeed 1;
BA_ "SPN" SG_ 2364539395 TransmInSpeed 161;
BA_ "GenSigTimeoutTime_VMU" SG_ 2364539395 TransmInSpeed 500;
BA_ "GenSigTimeoutTime_VCU" SG_ 2364539395 TransmInSpeed 500;
BA_ "GenSigTimeoutTime_VCM" SG_ 2364539395 TransmInSpeed 500;
BA_ "GenSigTimeoutTime_SGW" SG_ 2364539395 TransmInSpeed 500;
BA_ "GenSigTimeoutTime_PCM" SG_ 2364539395 TransmInSpeed 500;
BA_ "GenSigTimeoutTime_MPPxPTFE2" SG_ 2364539395 TransmInSpeed 500;
BA_ "GenSigTimeoutTime_FMS_FMS5" SG_ 2364539395 TransmInSpeed 500;
BA_ "GenSigTimeoutTime_FMS_FMS4" SG_ 2364539395 TransmInSpeed 500;
BA_ "GenSigTimeoutTime_BSM_EBS" SG_ 2364539395 TransmInSpeed 500;
BA_ "CI_SigName" SG_ 2364539395 TransmInSpeed "Transmission 1 Input Shaft Speed";
BA_ "CI_SigId" SG_ 2364539395 TransmInSpeed 539;
BA_ "CI_ParId" SG_ 2364539395 TransmInSpeed "161";
BA_ "SigType" SG_ 2364539395 PcCltSlip 1;
BA_ "SPN" SG_ 2364539395 PcCltSlip 522;
BA_ "GenSigTimeoutTime_VCM" SG_ 2364539395 PcCltSlip 500;
BA_ "GenSigTimeoutTime_SGW" SG_ 2364539395 PcCltSlip 500;
BA_ "GenSigTimeoutTime_PCM" SG_ 2364539395 PcCltSlip 500;
BA_ "GenSigTimeoutTime_FMS_FMS5" SG_ 2364539395 PcCltSlip 500;
BA_ "GenSigTimeoutTime_FMS_FMS4" SG_ 2364539395 PcCltSlip 500;
BA_ "GenSigTimeoutTime_ECM_MD1_G" SG_ 2364539395 PcCltSlip 500;
BA_ "GenSigTimeoutTime_ECM_MD1_D" SG_ 2364539395 PcCltSlip 500;
BA_ "GenSigTimeoutTime_BSM_EBS" SG_ 2364539395 PcCltSlip 500;
BA_ "GenSigTimeoutTime_ADCU" SG_ 2364539395 PcCltSlip 500;
BA_ "CI_SigName" SG_ 2364539395 PcCltSlip "Percent Clutch Slip";
BA_ "CI_SigId" SG_ 2364539395 PcCltSlip 535;
BA_ "CI_ParId" SG_ 2364539395 PcCltSlip "522";
BA_ "SigType" SG_ 2364539395 TransmOutSpeed 1;
BA_ "SPN" SG_ 2364539395 TransmOutSpeed 191;
BA_ "GenSigTimeoutTime_VMU" SG_ 2364539395 TransmOutSpeed 500;
BA_ "GenSigTimeoutTime_VCU" SG_ 2364539395 TransmOutSpeed 500;
BA_ "GenSigTimeoutTime_VCM" SG_ 2364539395 TransmOutSpeed 500;
BA_ "GenSigTimeoutTime_SGW" SG_ 2364539395 TransmOutSpeed 500;
BA_ "GenSigTimeoutTime_PCM" SG_ 2364539395 TransmOutSpeed 500;
BA_ "GenSigTimeoutTime_MPPxPTFE2" SG_ 2364539395 TransmOutSpeed 500;
BA_ "GenSigTimeoutTime_FMS_FMS5" SG_ 2364539395 TransmOutSpeed 500;
BA_ "GenSigTimeoutTime_FMS_FMS4" SG_ 2364539395 TransmOutSpeed 500;
BA_ "GenSigTimeoutTime_ECM_MD1_G" SG_ 2364539395 TransmOutSpeed 500;
BA_ "GenSigTimeoutTime_ECM_MD1_D" SG_ 2364539395 TransmOutSpeed 500;
BA_ "GenSigTimeoutTime_BSM_EBS" SG_ 2364539395 TransmOutSpeed 500;
BA_ "GenSigTimeoutTime_ADCU" SG_ 2364539395 TransmOutSpeed 500;
BA_ "CI_SigName" SG_ 2364539395 TransmOutSpeed "Transmission 1 Output Shaft Speed";
BA_ "CI_SigId" SG_ 2364539395 TransmOutSpeed 534;
BA_ "CI_ParId" SG_ 2364539395 TransmOutSpeed "191";
BA_ "SigType" SG_ 2364539395 TransmDrvlEngd 4;
BA_ "SPN" SG_ 2364539395 TransmDrvlEngd 560;
BA_ "GenSigTimeoutTime_VMU" SG_ 2364539395 TransmDrvlEngd 500;
BA_ "GenSigTimeoutTime_VCU" SG_ 2364539395 TransmDrvlEngd 500;
BA_ "GenSigTimeoutTime_VCM" SG_ 2364539395 TransmDrvlEngd 500;
BA_ "GenSigTimeoutTime_SGW" SG_ 2364539395 TransmDrvlEngd 500;
BA_ "GenSigTimeoutTime_PCM" SG_ 2364539395 TransmDrvlEngd 500;
BA_ "GenSigTimeoutTime_MPPxPTFE2" SG_ 2364539395 TransmDrvlEngd 500;
BA_ "GenSigTimeoutTime_FMS_FMS5" SG_ 2364539395 TransmDrvlEngd 500;
BA_ "GenSigTimeoutTime_FMS_FMS4" SG_ 2364539395 TransmDrvlEngd 500;
BA_ "GenSigTimeoutTime_ECM_MD1_G" SG_ 2364539395 TransmDrvlEngd 500;
BA_ "GenSigTimeoutTime_ECM_MD1_D" SG_ 2364539395 TransmDrvlEngd 500;
BA_ "GenSigTimeoutTime_BSM_EBS" SG_ 2364539395 TransmDrvlEngd 500;
BA_ "GenSigTimeoutTime_ADCU" SG_ 2364539395 TransmDrvlEngd 500;
BA_ "CI_SigName" SG_ 2364539395 TransmDrvlEngd "Transmission Driveline Engaged";
BA_ "CI_SigId" SG_ 2364539395 TransmDrvlEngd 530;
BA_ "CI_ParId" SG_ 2364539395 TransmDrvlEngd "560";
BA_ "SigType" SG_ 2565866755 TransmCurGear 1;
BA_ "SPN" SG_ 2565866755 TransmCurGear 523;
BA_ "GenSigTimeoutTime_VMU" SG_ 2565866755 TransmCurGear 500;
BA_ "GenSigTimeoutTime_VCU" SG_ 2565866755 TransmCurGear 500;
BA_ "GenSigTimeoutTime_VCM" SG_ 2565866755 TransmCurGear 500;
BA_ "GenSigTimeoutTime_SGW" SG_ 2565866755 TransmCurGear 500;
BA_ "GenSigTimeoutTime_PCM" SG_ 2565866755 TransmCurGear 500;
BA_ "GenSigTimeoutTime_MPPxPTFE2" SG_ 2565866755 TransmCurGear 500;
BA_ "GenSigTimeoutTime_IC_MulticS" SG_ 2565866755 TransmCurGear 500;
BA_ "GenSigTimeoutTime_IC_MulticII" SG_ 2565866755 TransmCurGear 500;
BA_ "GenSigTimeoutTime_FMS_FMS5" SG_ 2565866755 TransmCurGear 500;
BA_ "GenSigTimeoutTime_FMS_FMS4" SG_ 2565866755 TransmCurGear 500;
BA_ "GenSigTimeoutTime_ECM_MD1_G" SG_ 2565866755 TransmCurGear 500;
BA_ "GenSigTimeoutTime_ECM_MD1_D" SG_ 2565866755 TransmCurGear 500;
BA_ "GenSigTimeoutTime_BSM_EBS" SG_ 2565866755 TransmCurGear 500;
BA_ "GenSigTimeoutTime_BCM_NBM" SG_ 2565866755 TransmCurGear 500;
BA_ "GenSigTimeoutTime_Av2HP" SG_ 2565866755 TransmCurGear 500;
BA_ "GenSigTimeoutTime_AVAS" SG_ 2565866755 TransmCurGear 500;
BA_ "GenSigTimeoutTime_ADCU" SG_ 2565866755 TransmCurGear 500;
BA_ "GenSigTimeoutTime_ACU" SG_ 2565866755 TransmCurGear 500;
BA_ "CI_SigName" SG_ 2565866755 TransmCurGear "Transmission Current Gear";
BA_ "CI_SigId" SG_ 2565866755 TransmCurGear 544;
BA_ "CI_ParId" SG_ 2565866755 TransmCurGear "523";
BA_ "SigType" SG_ 2565866755 TransmSelGear 1;
BA_ "SPN" SG_ 2565866755 TransmSelGear 524;
BA_ "GenSigTimeoutTime_VMU" SG_ 2565866755 TransmSelGear 500;
BA_ "GenSigTimeoutTime_VCU" SG_ 2565866755 TransmSelGear 500;
BA_ "GenSigTimeoutTime_VCM" SG_ 2565866755 TransmSelGear 500;
BA_ "GenSigTimeoutTime_SGW" SG_ 2565866755 TransmSelGear 500;
BA_ "GenSigTimeoutTime_PCM" SG_ 2565866755 TransmSelGear 500;
BA_ "GenSigTimeoutTime_MPPxPTFE2" SG_ 2565866755 TransmSelGear 500;
BA_ "GenSigTimeoutTime_IC_MulticS" SG_ 2565866755 TransmSelGear 500;
BA_ "GenSigTimeoutTime_IC_MulticII" SG_ 2565866755 TransmSelGear 500;
BA_ "GenSigTimeoutTime_FMS_FMS5" SG_ 2565866755 TransmSelGear 500;
BA_ "GenSigTimeoutTime_FMS_FMS4" SG_ 2565866755 TransmSelGear 500;
BA_ "GenSigTimeoutTime_ECM_MD1_G" SG_ 2565866755 TransmSelGear 500;
BA_ "GenSigTimeoutTime_ECM_MD1_D" SG_ 2565866755 TransmSelGear 500;
BA_ "GenSigTimeoutTime_BCM_NBM" SG_ 2565866755 TransmSelGear 500;
BA_ "GenSigTimeoutTime_ADCU" SG_ 2565866755 TransmSelGear 500;
BA_ "GenSigTimeoutTime_ACU" SG_ 2565866755 TransmSelGear 500;
BA_ "GenSigStartValue" SG_ 2565866755 TransmSelGear 125;
BA_ "CI_SigName" SG_ 2565866755 TransmSelGear "Transmission Selected Gear";
BA_ "CI_SigId" SG_ 2565866755 TransmSelGear 542;
BA_ "CI_ParId" SG_ 2565866755 TransmSelGear "524";
BA_ "SigType" SG_ 2566826755 LowPossGear 1;
BA_ "SPN" SG_ 2566826755 LowPossGear 1114;
BA_ "GenSigTimeoutTime_SGW" SG_ 2566826755 LowPossGear 1250;
BA_ "GenSigTimeoutTime_PCM" SG_ 2566826755 LowPossGear 1250;
BA_ "GenSigTimeoutTime_IC_MulticS" SG_ 2566826755 LowPossGear 1250;
BA_ "GenSigStartValue" SG_ 2566826755 LowPossGear 125;
BA_ "CI_SigName" SG_ 2566826755 LowPossGear "Lowest Possible Gear";
BA_ "CI_SigId" SG_ 2566826755 LowPossGear 567;
BA_ "CI_ParId" SG_ 2566826755 LowPossGear "1114";
BA_ "SigType" SG_ 2566826755 HighPossGear 1;
BA_ "SPN" SG_ 2566826755 HighPossGear 1115;
BA_ "GenSigTimeoutTime_SGW" SG_ 2566826755 HighPossGear 1250;
BA_ "GenSigTimeoutTime_PCM" SG_ 2566826755 HighPossGear 1250;
BA_ "GenSigTimeoutTime_IC_MulticS" SG_ 2566826755 HighPossGear 1250;
BA_ "GenSigStartValue" SG_ 2566826755 HighPossGear 125;
BA_ "CI_SigName" SG_ 2566826755 HighPossGear "Highest Possible Gear";
BA_ "CI_SigId" SG_ 2566826755 HighPossGear 566;
BA_ "CI_ParId" SG_ 2566826755 HighPossGear "1115";
BA_ "SPN" SG_ 2364541955 TransmTrqConvRatio 3030;
BA_ "GenSigTimeoutTime_SGW" SG_ 2364541955 TransmTrqConvRatio 500;
BA_ "GenSigTimeoutTime_PCM" SG_ 2364541955 TransmTrqConvRatio 500;
BA_ "GenSigTimeoutTime_BSM_EBS" SG_ 2364541955 TransmTrqConvRatio 500;
BA_ "CI_SigName" SG_ 2364541955 TransmTrqConvRatio "Transmission Torque Converter Ratio";
BA_ "CI_SigId" SG_ 2364541955 TransmTrqConvRatio 626;
BA_ "CI_ParId" SG_ 2364541955 TransmTrqConvRatio "3030";
BA_ "SigType" SG_ 2566831393 FanSpeed 1;
BA_ "SPN" SG_ 2566831393 FanSpeed 1639;
BA_ "GenSigTimeoutTime_SGW" SG_ 2566831393 FanSpeed 5000;
BA_ "GenSigTimeoutTime_PCM" SG_ 2566831393 FanSpeed 5000;
BA_ "CI_SigName" SG_ 2566831393 FanSpeed "Fan Speed";
BA_ "CI_SigId" SG_ 2566831393 FanSpeed 2183;
BA_ "CI_ParId" SG_ 2566831393 FanSpeed "1639";
BA_ "SigType" SG_ 2431649694 LaneDepImmLh 4;
BA_ "SPN" SG_ 2431649694 LaneDepImmLh 1700;
BA_ "GenSigTimeoutTime_SGW" SG_ 2431649694 LaneDepImmLh 500;
BA_ "GenSigTimeoutTime_PCM" SG_ 2431649694 LaneDepImmLh 500;
BA_ "GenSigTimeoutTime_IC_MulticS" SG_ 2431649694 LaneDepImmLh 500;
BA_ "GenSigTimeoutTime_IC_MulticII" SG_ 2431649694 LaneDepImmLh 500;
BA_ "GenSigTimeoutTime_BCM_NBM" SG_ 2431649694 LaneDepImmLh 500;
BA_ "GenSigSendType" SG_ 2431649694 LaneDepImmLh 6;
BA_ "CI_SigName" SG_ 2431649694 LaneDepImmLh "Lane Departure Imminent, Left Side";
BA_ "CI_SigId" SG_ 2431649694 LaneDepImmLh 3108;
BA_ "CI_ParId" SG_ 2431649694 LaneDepImmLh "1700";
BA_ "SigType" SG_ 2431649694 LaneDepImmRh 4;
BA_ "SPN" SG_ 2431649694 LaneDepImmRh 1701;
BA_ "GenSigTimeoutTime_SGW" SG_ 2431649694 LaneDepImmRh 500;
BA_ "GenSigTimeoutTime_PCM" SG_ 2431649694 LaneDepImmRh 500;
BA_ "GenSigTimeoutTime_IC_MulticS" SG_ 2431649694 LaneDepImmRh 500;
BA_ "GenSigTimeoutTime_IC_MulticII" SG_ 2431649694 LaneDepImmRh 500;
BA_ "GenSigTimeoutTime_BCM_NBM" SG_ 2431649694 LaneDepImmRh 500;
BA_ "GenSigSendType" SG_ 2431649694 LaneDepImmRh 6;
BA_ "CI_SigName" SG_ 2431649694 LaneDepImmRh "Lane Departure Imminent, Right Side";
BA_ "CI_SigId" SG_ 2431649694 LaneDepImmRh 3107;
BA_ "CI_ParId" SG_ 2431649694 LaneDepImmRh "1701";
BA_ "SPN" SG_ 2566806430 FwLaneImagerSts 8142;
BA_ "GenSigTimeoutTime_SGW" SG_ 2566806430 FwLaneImagerSts 500;
BA_ "GenSigTimeoutTime_PCM" SG_ 2566806430 FwLaneImagerSts 500;
BA_ "GenSigTimeoutTime_IC_MulticS" SG_ 2566806430 FwLaneImagerSts 500;
BA_ "GenSigTimeoutTime_IC_MulticII" SG_ 2566806430 FwLaneImagerSts 500;
BA_ "CI_SigName" SG_ 2566806430 FwLaneImagerSts "Forward Lane Imager Status";
BA_ "CI_SigId" SG_ 2566806430 FwLaneImagerSts 3127;
BA_ "CI_ParId" SG_ 2566806430 FwLaneImagerSts "8142";
BA_ "SPN" SG_ 2566806430 LdwSysSts 8141;
BA_ "GenSigTimeoutTime_SGW" SG_ 2566806430 LdwSysSts 500;
BA_ "GenSigTimeoutTime_PCM" SG_ 2566806430 LdwSysSts 500;
BA_ "GenSigTimeoutTime_IC_MulticS" SG_ 2566806430 LdwSysSts 500;
BA_ "CI_SigName" SG_ 2566806430 LdwSysSts "Lane Departure Warning System State";
BA_ "CI_SigId" SG_ 2566806430 LdwSysSts 3126;
BA_ "CI_ParId" SG_ 2566806430 LdwSysSts "8141";
BA_ "SPN" SG_ 2566806430 DrivAlertWarnSysSts 7475;
BA_ "GenSigTimeoutTime_SGW" SG_ 2566806430 DrivAlertWarnSysSts 500;
BA_ "GenSigTimeoutTime_PCM" SG_ 2566806430 DrivAlertWarnSysSts 500;
BA_ "GenSigTimeoutTime_IC_MulticS" SG_ 2566806430 DrivAlertWarnSysSts 500;
BA_ "CI_SigName" SG_ 2566806430 DrivAlertWarnSysSts "Driver Alertness Warning System State";
BA_ "CI_SigId" SG_ 2566806430 DrivAlertWarnSysSts 3123;
BA_ "CI_ParId" SG_ 2566806430 DrivAlertWarnSysSts "7475";
BA_ "SigType" SG_ 2566806430 DrivAlertLev 1;
BA_ "SPN" SG_ 2566806430 DrivAlertLev 7474;
BA_ "GenSigTimeoutTime_SGW" SG_ 2566806430 DrivAlertLev 500;
BA_ "GenSigTimeoutTime_PCM" SG_ 2566806430 DrivAlertLev 500;
BA_ "GenSigTimeoutTime_IC_MulticS" SG_ 2566806430 DrivAlertLev 500;
BA_ "CI_SigName" SG_ 2566806430 DrivAlertLev "Driver Alertness Level";
BA_ "CI_SigId" SG_ 2566806430 DrivAlertLev 3122;
BA_ "CI_ParId" SG_ 2566806430 DrivAlertLev "7474";
BA_ "SigType" SG_ 2566806430 LaneDepIndEnaSts 4;
BA_ "SPN" SG_ 2566806430 LaneDepIndEnaSts 1702;
BA_ "GenSigTimeoutTime_VCM" SG_ 2566806430 LaneDepIndEnaSts 500;
BA_ "GenSigTimeoutTime_SGW" SG_ 2566806430 LaneDepIndEnaSts 500;
BA_ "GenSigTimeoutTime_PCM" SG_ 2566806430 LaneDepIndEnaSts 500;
BA_ "CI_SigName" SG_ 2566806430 LaneDepIndEnaSts "Lane Departure Indication Enable Status";
BA_ "CI_SigId" SG_ 2566806430 LaneDepIndEnaSts 3121;
BA_ "CI_ParId" SG_ 2566806430 LaneDepIndEnaSts "1702";
BA_ "SigType" SG_ 2566841600 EngTotHrOfOp 1;
BA_ "SPN" SG_ 2566841600 EngTotHrOfOp 247;
BA_ "GenSigTimeoutTime_VCM" SG_ 2566841600 EngTotHrOfOp 5000;
BA_ "GenSigTimeoutTime_SGW2" SG_ 2566841600 EngTotHrOfOp 5000;
BA_ "GenSigTimeoutTime_SGW" SG_ 2566841600 EngTotHrOfOp 5000;
BA_ "GenSigTimeoutTime_PCM" SG_ 2566841600 EngTotHrOfOp 5000;
BA_ "GenSigTimeoutTime_MPPxPTFE2" SG_ 2566841600 EngTotHrOfOp 5000;
BA_ "GenSigTimeoutTime_MBMS" SG_ 2566841600 EngTotHrOfOp 5000;
BA_ "GenSigTimeoutTime_IC_MulticS" SG_ 2566841600 EngTotHrOfOp 5000;
BA_ "GenSigTimeoutTime_FMS_FMS5" SG_ 2566841600 EngTotHrOfOp 5000;
BA_ "GenSigTimeoutTime_FMS_FMS4" SG_ 2566841600 EngTotHrOfOp 5000;
BA_ "GenSigTimeoutTime_EBS_EBR" SG_ 2566841600 EngTotHrOfOp 5000;
BA_ "GenSigTimeoutTime_DMS" SG_ 2566841600 EngTotHrOfOp 5000;
BA_ "GenSigTimeoutTime_BSM_EBS" SG_ 2566841600 EngTotHrOfOp 5000;
BA_ "GenSigTimeoutTime_ADCU" SG_ 2566841600 EngTotHrOfOp 5000;
BA_ "CI_SigName" SG_ 2566841600 EngTotHrOfOp "Engine Total Hours of Operation";
BA_ "CI_SigId" SG_ 2566841600 EngTotHrOfOp 1094;
BA_ "CI_ParId" SG_ 2566841600 EngTotHrOfOp "247";
BA_ "SigType" SG_ 2566719744 EngTotFuelUsedHr 1;
BA_ "SPN" SG_ 2566719744 EngTotFuelUsedHr 5054;
BA_ "GenSigTimeoutTime_VCM" SG_ 2566719744 EngTotFuelUsedHr 5000;
BA_ "GenSigTimeoutTime_SGW" SG_ 2566719744 EngTotFuelUsedHr 5000;
BA_ "GenSigTimeoutTime_PCM" SG_ 2566719744 EngTotFuelUsedHr 5000;
BA_ "GenSigTimeoutTime_IC_MulticS" SG_ 2566719744 EngTotFuelUsedHr 5000;
BA_ "GenSigTimeoutTime_FMS_FMS5" SG_ 2566719744 EngTotFuelUsedHr 5000;
BA_ "GenSigTimeoutTime_FMS_FMS4" SG_ 2566719744 EngTotFuelUsedHr 5000;
BA_ "CI_SigName" SG_ 2566719744 EngTotFuelUsedHr "Engine Total Fuel Used (High Resolution)";
BA_ "CI_SigId" SG_ 2566719744 EngTotFuelUsedHr 1149;
BA_ "CI_ParId" SG_ 2566719744 EngTotFuelUsedHr "5054";
BA_ "SigType" SG_ 2566837793 HybSysCoastRegenBrkLevSel 1;
BA_ "SPN" SG_ 2566837793 HybSysCoastRegenBrkLevSel 7556;
BA_ "GenSigTimeoutTime_VMU" SG_ 2566837793 HybSysCoastRegenBrkLevSel 500;
BA_ "GenSigTimeoutTime_VCU" SG_ 2566837793 HybSysCoastRegenBrkLevSel 500;
BA_ "GenSigTimeoutTime_SGW" SG_ 2566837793 HybSysCoastRegenBrkLevSel 500;
BA_ "GenSigTimeoutTime_PCM" SG_ 2566837793 HybSysCoastRegenBrkLevSel 500;
BA_ "GenSigTimeoutTime_MPPxPTFE2" SG_ 2566837793 HybSysCoastRegenBrkLevSel 500;
BA_ "GenSigTimeoutTime_FMS_FMS4" SG_ 2566837793 HybSysCoastRegenBrkLevSel 500;
BA_ "CI_SigName" SG_ 2566837793 HybSysCoastRegenBrkLevSel "Hybrid System Coasting Regenerative Braking Level Selector";
BA_ "CI_SigId" SG_ 2566837793 HybSysCoastRegenBrkLevSel 2230;
BA_ "CI_ParId" SG_ 2566837793 HybSysCoastRegenBrkLevSel "7556";
BA_ "SigType" SG_ 2566837793 HybSysPwrElnCoolLevSw 4;
BA_ "SPN" SG_ 2566837793 HybSysPwrElnCoolLevSw 7550;
BA_ "GenSigTimeoutTime_SGW" SG_ 2566837793 HybSysPwrElnCoolLevSw 500;
BA_ "GenSigTimeoutTime_PCM" SG_ 2566837793 HybSysPwrElnCoolLevSw 500;
BA_ "GenSigTimeoutTime_MPPxPTFE2" SG_ 2566837793 HybSysPwrElnCoolLevSw 500;
BA_ "GenSigTimeoutTime_FMS_FMS4" SG_ 2566837793 HybSysPwrElnCoolLevSw 500;
BA_ "CI_SigName" SG_ 2566837793 HybSysPwrElnCoolLevSw "Hybrid System Power Electronics Coolant Level Switch";
BA_ "CI_SigId" SG_ 2566837793 HybSysPwrElnCoolLevSw 2224;
BA_ "CI_ParId" SG_ 2566837793 HybSysPwrElnCoolLevSw "7550";
BA_ "SPN" SG_ 2566701658 ExtEnergySrcConnSts 7898;
BA_ "GenSigTimeoutTime_SGW" SG_ 2566701658 ExtEnergySrcConnSts 500;
BA_ "GenSigTimeoutTime_PCM" SG_ 2566701658 ExtEnergySrcConnSts 500;
BA_ "GenSigTimeoutTime_MPPxPTFE2" SG_ 2566701658 ExtEnergySrcConnSts 500;
BA_ "GenSigTimeoutTime_FMS_FMS5" SG_ 2566701658 ExtEnergySrcConnSts 500;
BA_ "GenSigTimeoutTime_FMS_FMS4" SG_ 2566701658 ExtEnergySrcConnSts 500;
BA_ "GenSigTimeoutTime_BCM_NBM" SG_ 2566701658 ExtEnergySrcConnSts 500;
BA_ "CI_SigName" SG_ 2566701658 ExtEnergySrcConnSts "External Energy Source Connection Status";
BA_ "CI_SigId" SG_ 2566701658 ExtEnergySrcConnSts 2252;
BA_ "CI_ParId" SG_ 2566701658 ExtEnergySrcConnSts "7898";
BA_ "SPN" SG_ 2566701658 HybPropModeSts 7896;
BA_ "GenSigTimeoutTime_SGW" SG_ 2566701658 HybPropModeSts 500;
BA_ "GenSigTimeoutTime_PCM" SG_ 2566701658 HybPropModeSts 500;
BA_ "GenSigTimeoutTime_MPPxPTFE2" SG_ 2566701658 HybPropModeSts 500;
BA_ "GenSigTimeoutTime_FMS_FMS5" SG_ 2566701658 HybPropModeSts 500;
BA_ "GenSigTimeoutTime_FMS_FMS4" SG_ 2566701658 HybPropModeSts 500;
BA_ "GenSigTimeoutTime_BCM_NBM" SG_ 2566701658 HybPropModeSts 500;
BA_ "CI_SigName" SG_ 2566701658 HybPropModeSts "Hybrid Propulsion Mode Status";
BA_ "CI_SigId" SG_ 2566701658 HybPropModeSts 2250;
BA_ "CI_ParId" SG_ 2566701658 HybPropModeSts "7896";
BA_ "SigType" SG_ 2566701658 StoredEnergySrcLev 1;
BA_ "SPN" SG_ 2566701658 StoredEnergySrcLev 7895;
BA_ "GenSigTimeoutTime_SGW" SG_ 2566701658 StoredEnergySrcLev 500;
BA_ "GenSigTimeoutTime_PCM" SG_ 2566701658 StoredEnergySrcLev 500;
BA_ "GenSigTimeoutTime_MPPxPTFE2" SG_ 2566701658 StoredEnergySrcLev 500;
BA_ "GenSigTimeoutTime_FMS_FMS5" SG_ 2566701658 StoredEnergySrcLev 500;
BA_ "GenSigTimeoutTime_FMS_FMS4" SG_ 2566701658 StoredEnergySrcLev 500;
BA_ "GenSigTimeoutTime_BCM_NBM" SG_ 2566701658 StoredEnergySrcLev 500;
BA_ "CI_SigName" SG_ 2566701658 StoredEnergySrcLev "Stored Energy Source Level";
BA_ "CI_SigId" SG_ 2566701658 StoredEnergySrcLev 2249;
BA_ "CI_ParId" SG_ 2566701658 StoredEnergySrcLev "7895";
BA_ "SigType" SG_ 2566701658 HybSysRegenBrkInd 4;
BA_ "SPN" SG_ 2566701658 HybSysRegenBrkInd 7452;
BA_ "GenSigTimeoutTime_SGW" SG_ 2566701658 HybSysRegenBrkInd 500;
BA_ "GenSigTimeoutTime_PCM" SG_ 2566701658 HybSysRegenBrkInd 500;
BA_ "GenSigTimeoutTime_MPPxPTFE2" SG_ 2566701658 HybSysRegenBrkInd 500;
BA_ "GenSigTimeoutTime_FMS_FMS5" SG_ 2566701658 HybSysRegenBrkInd 500;
BA_ "GenSigTimeoutTime_FMS_FMS4" SG_ 2566701658 HybSysRegenBrkInd 500;
BA_ "GenSigTimeoutTime_BCM_NBM" SG_ 2566701658 HybSysRegenBrkInd 500;
BA_ "CI_SigName" SG_ 2566701658 HybSysRegenBrkInd "Hybrid System Regenerative Braking Indicator";
BA_ "CI_SigId" SG_ 2566701658 HybSysRegenBrkInd 2244;
BA_ "CI_ParId" SG_ 2566701658 HybSysRegenBrkInd "7452";
BA_ "SigType" SG_ 2566701658 HybSysMotOverspeedInd 4;
BA_ "SPN" SG_ 2566701658 HybSysMotOverspeedInd 7449;
BA_ "GenSigTimeoutTime_SGW" SG_ 2566701658 HybSysMotOverspeedInd 500;
BA_ "GenSigTimeoutTime_PCM" SG_ 2566701658 HybSysMotOverspeedInd 500;
BA_ "GenSigTimeoutTime_MPPxPTFE2" SG_ 2566701658 HybSysMotOverspeedInd 500;
BA_ "GenSigTimeoutTime_FMS_FMS5" SG_ 2566701658 HybSysMotOverspeedInd 500;
BA_ "GenSigTimeoutTime_FMS_FMS4" SG_ 2566701658 HybSysMotOverspeedInd 500;
BA_ "GenSigTimeoutTime_BCM_NBM" SG_ 2566701658 HybSysMotOverspeedInd 500;
BA_ "CI_SigName" SG_ 2566701658 HybSysMotOverspeedInd "Hybrid System Motor Overspeed Indicator";
BA_ "CI_SigId" SG_ 2566701658 HybSysMotOverspeedInd 2241;
BA_ "CI_ParId" SG_ 2566701658 HybSysMotOverspeedInd "7449";
BA_ "SigType" SG_ 2566701658 PropSysActv 4;
BA_ "SPN" SG_ 2566701658 PropSysActv 7315;
BA_ "GenSigTimeoutTime_SGW" SG_ 2566701658 PropSysActv 500;
BA_ "GenSigTimeoutTime_PCM" SG_ 2566701658 PropSysActv 500;
BA_ "GenSigTimeoutTime_MPPxPTFE2" SG_ 2566701658 PropSysActv 500;
BA_ "GenSigTimeoutTime_FMS_FMS5" SG_ 2566701658 PropSysActv 500;
BA_ "GenSigTimeoutTime_FMS_FMS4" SG_ 2566701658 PropSysActv 500;
BA_ "GenSigTimeoutTime_BCM_NBM" SG_ 2566701658 PropSysActv 500;
BA_ "CI_SigName" SG_ 2566701658 PropSysActv "Propulsion System Active";
BA_ "CI_SigId" SG_ 2566701658 PropSysActv 2238;
BA_ "CI_ParId" SG_ 2566701658 PropSysActv "7315";
BA_ "SigType" SG_ 2566698842 HybSysEassRemPc 1;
BA_ "SPN" SG_ 2566698842 HybSysEassRemPc 8558;
BA_ "GenSigTimeoutTime_SGW" SG_ 2566698842 HybSysEassRemPc 5000;
BA_ "GenSigTimeoutTime_PCM" SG_ 2566698842 HybSysEassRemPc 5000;
BA_ "GenSigTimeoutTime_BCM_NBM" SG_ 2566698842 HybSysEassRemPc 5000;
BA_ "CI_SigName" SG_ 2566698842 HybSysEassRemPc "Hybrid System Engine Stop-Start Remaining Percentage";
BA_ "CI_SigId" SG_ 2566698842 HybSysEassRemPc 2277;
BA_ "CI_ParId" SG_ 2566698842 HybSysEassRemPc "8558";
BA_ "SigType" SG_ 2566698842 HybBatRemChg 1;
BA_ "SPN" SG_ 2566698842 HybBatRemChg 5464;
BA_ "GenSigTimeoutTime_SGW" SG_ 2566698842 HybBatRemChg 5000;
BA_ "GenSigTimeoutTime_PCM" SG_ 2566698842 HybBatRemChg 5000;
BA_ "GenSigTimeoutTime_MPPxPTFE2" SG_ 2566698842 HybBatRemChg 5000;
BA_ "GenSigTimeoutTime_IC_MulticS" SG_ 2566698842 HybBatRemChg 5000;
BA_ "GenSigTimeoutTime_FMS_FMS5" SG_ 2566698842 HybBatRemChg 5000;
BA_ "GenSigTimeoutTime_FMS_FMS4" SG_ 2566698842 HybBatRemChg 5000;
BA_ "CI_SigName" SG_ 2566698842 HybBatRemChg "Hybrid Battery Pack Remaining Charge";
BA_ "CI_SigId" SG_ 2566698842 HybBatRemChg 2276;
BA_ "CI_ParId" SG_ 2566698842 HybBatRemChg "5464";
BA_ "SigType" SG_ 2566850819 StsOfHealt 1;
BA_ "GenSigTimeoutTime_VCM" SG_ 2566850819 StsOfHealt 500;
BA_ "GenSigTimeoutTime_SGW" SG_ 2566850819 StsOfHealt 500;
BA_ "GenSigTimeoutTime_PCM" SG_ 2566850819 StsOfHealt 500;
BA_ "GenSigTimeoutTime_ECM_MD1_G" SG_ 2566850819 StsOfHealt 500;
BA_ "GenSigTimeoutTime_ECM_MD1_D" SG_ 2566850819 StsOfHealt 500;
BA_ "CI_SigName" SG_ 2566850819 StsOfHealt "State of healt";
BA_ "CI_SigId" SG_ 2566850819 StsOfHealt 2292;
BA_ "CI_ParId" SG_ 2566850819 StsOfHealt "IB277";
BA_ "GenSigTimeoutTime_VCM" SG_ 2566850819 Soc 500;
BA_ "GenSigTimeoutTime_SGW" SG_ 2566850819 Soc 500;
BA_ "GenSigTimeoutTime_PCM" SG_ 2566850819 Soc 500;
BA_ "GenSigTimeoutTime_IC_MulticS" SG_ 2566850819 Soc 500;
BA_ "GenSigTimeoutTime_ECM_MD1_G" SG_ 2566850819 Soc 500;
BA_ "GenSigTimeoutTime_ECM_MD1_D" SG_ 2566850819 Soc 500;
BA_ "GenSigTimeoutTime_BCM_NBM" SG_ 2566850819 Soc 500;
BA_ "GenSigStartValue" SG_ 2566850819 Soc 2000;
BA_ "CI_SigName" SG_ 2566850819 Soc "State of charge";
BA_ "CI_SigId" SG_ 2566850819 Soc 2291;
BA_ "CI_ParId" SG_ 2566850819 Soc "IB276";
BA_ "GenSigTimeoutTime_SGW" SG_ 2566851075 _24VFeedinpointV 1500;
BA_ "GenSigTimeoutTime_PCM" SG_ 2566851075 _24VFeedinpointV 1500;
BA_ "CI_SigName" SG_ 2566851075 _24VFeedinpointV "24V FeedInPoint Voltage";
BA_ "CI_SigId" SG_ 2566851075 _24VFeedinpointV 2311;
BA_ "CI_ParId" SG_ 2566851075 _24VFeedinpointV "IB1070";
BA_ "GenSigTimeoutTime_SGW" SG_ 2566851075 _48VPwrconverterDcV 1500;
BA_ "GenSigTimeoutTime_PCM" SG_ 2566851075 _48VPwrconverterDcV 1500;
BA_ "CI_SigName" SG_ 2566851075 _48VPwrconverterDcV "48V_PowerConverter_DC_Voltage";
BA_ "CI_SigId" SG_ 2566851075 _48VPwrconverterDcV 2310;
BA_ "CI_ParId" SG_ 2566851075 _48VPwrconverterDcV "IB882";
BA_ "GenSigTimeoutTime_SGW" SG_ 2566851075 _48VPwrconverterDcCur 1500;
BA_ "GenSigTimeoutTime_PCM" SG_ 2566851075 _48VPwrconverterDcCur 1500;
BA_ "GenSigStartValue" SG_ 2566851075 _48VPwrconverterDcCur 2000;
BA_ "CI_SigName" SG_ 2566851075 _48VPwrconverterDcCur "48V_PowerConverter_DC_Current";
BA_ "CI_SigId" SG_ 2566851075 _48VPwrconverterDcCur 2309;
BA_ "CI_ParId" SG_ 2566851075 _48VPwrconverterDcCur "IB881";
BA_ "GenSigTimeoutTime_SGW" SG_ 2566851075 _48VDcdcCur 1500;
BA_ "GenSigTimeoutTime_PCM" SG_ 2566851075 _48VDcdcCur 1500;
BA_ "GenSigStartValue" SG_ 2566851075 _48VDcdcCur 2000;
BA_ "CI_SigName" SG_ 2566851075 _48VDcdcCur "48V_DCDC_Current";
BA_ "CI_SigId" SG_ 2566851075 _48VDcdcCur 2308;
BA_ "CI_ParId" SG_ 2566851075 _48VDcdcCur "IB880";
BA_ "GenSigTimeoutTime_SGW" SG_ 2566851075 _48VBatCur 1500;
BA_ "GenSigTimeoutTime_PCM" SG_ 2566851075 _48VBatCur 1500;
BA_ "GenSigStartValue" SG_ 2566851075 _48VBatCur 2000;
BA_ "CI_SigName" SG_ 2566851075 _48VBatCur "48V_Battery_Current";
BA_ "CI_SigId" SG_ 2566851075 _48VBatCur 2307;
BA_ "CI_ParId" SG_ 2566851075 _48VBatCur "IB879";
BA_ "SigType" SG_ 2566851331 Isbalancingactive 4;
BA_ "GenSigTimeoutTime_VCM" SG_ 2566851331 Isbalancingactive 1500;
BA_ "GenSigTimeoutTime_SGW" SG_ 2566851331 Isbalancingactive 1500;
BA_ "GenSigTimeoutTime_PCM" SG_ 2566851331 Isbalancingactive 1500;
BA_ "GenSigTimeoutTime_ECM_MD1_G" SG_ 2566851331 Isbalancingactive 1500;
BA_ "GenSigTimeoutTime_ECM_MD1_D" SG_ 2566851331 Isbalancingactive 1500;
BA_ "CI_SigName" SG_ 2566851331 Isbalancingactive "isBalancingActive";
BA_ "CI_SigId" SG_ 2566851331 Isbalancingactive 2318;
BA_ "CI_ParId" SG_ 2566851331 Isbalancingactive "IB878";
BA_ "GenSigTimeoutTime_VCM" SG_ 2566851331 EMotpower 1500;
BA_ "GenSigTimeoutTime_SGW" SG_ 2566851331 EMotpower 1500;
BA_ "GenSigTimeoutTime_PCM" SG_ 2566851331 EMotpower 1500;
BA_ "GenSigTimeoutTime_ECM_MD1_G" SG_ 2566851331 EMotpower 1500;
BA_ "GenSigTimeoutTime_ECM_MD1_D" SG_ 2566851331 EMotpower 1500;
BA_ "GenSigStartValue" SG_ 2566851331 EMotpower 2000;
BA_ "CI_SigName" SG_ 2566851331 EMotpower "E_MotorPower";
BA_ "CI_SigId" SG_ 2566851331 EMotpower 2317;
BA_ "CI_ParId" SG_ 2566851331 EMotpower "IB877";
BA_ "GenSigTimeoutTime_VCM" SG_ 2566851331 EMotspeed 1500;
BA_ "GenSigTimeoutTime_SGW" SG_ 2566851331 EMotspeed 1500;
BA_ "GenSigTimeoutTime_PCM" SG_ 2566851331 EMotspeed 1500;
BA_ "GenSigTimeoutTime_ECM_MD1_G" SG_ 2566851331 EMotspeed 1500;
BA_ "GenSigTimeoutTime_ECM_MD1_D" SG_ 2566851331 EMotspeed 1500;
BA_ "GenSigStartValue" SG_ 2566851331 EMotspeed 500;
BA_ "CI_SigName" SG_ 2566851331 EMotspeed "E_MotorSpeed";
BA_ "CI_SigId" SG_ 2566851331 EMotspeed 2316;
BA_ "CI_ParId" SG_ 2566851331 EMotspeed "IB876";
BA_ "GenSigTimeoutTime_VCM" SG_ 2566851331 EMottorque 1500;
BA_ "GenSigTimeoutTime_SGW" SG_ 2566851331 EMottorque 1500;
BA_ "GenSigTimeoutTime_PCM" SG_ 2566851331 EMottorque 1500;
BA_ "GenSigTimeoutTime_ECM_MD1_G" SG_ 2566851331 EMottorque 1500;
BA_ "GenSigTimeoutTime_ECM_MD1_D" SG_ 2566851331 EMottorque 1500;
BA_ "GenSigStartValue" SG_ 2566851331 EMottorque 2000;
BA_ "CI_SigName" SG_ 2566851331 EMottorque "E_MotorTorque";
BA_ "CI_SigId" SG_ 2566851331 EMottorque 2315;
BA_ "CI_ParId" SG_ 2566851331 EMottorque "IB875";
BA_ "GenSigTimeoutTime_VCM" SG_ 2566851331 _24VDcdcPwr 1500;
BA_ "GenSigTimeoutTime_SGW" SG_ 2566851331 _24VDcdcPwr 1500;
BA_ "GenSigTimeoutTime_PCM" SG_ 2566851331 _24VDcdcPwr 1500;
BA_ "GenSigTimeoutTime_ECM_MD1_G" SG_ 2566851331 _24VDcdcPwr 1500;
BA_ "GenSigTimeoutTime_ECM_MD1_D" SG_ 2566851331 _24VDcdcPwr 1500;
BA_ "GenSigStartValue" SG_ 2566851331 _24VDcdcPwr 2000;
BA_ "CI_SigName" SG_ 2566851331 _24VDcdcPwr "24V_DCDC_Power";
BA_ "CI_SigId" SG_ 2566851331 _24VDcdcPwr 2314;
BA_ "CI_ParId" SG_ 2566851331 _24VDcdcPwr "IB874";
BA_ "GenSigTimeoutTime_VCM" SG_ 2566851331 _24VDcdcCur 1500;
BA_ "GenSigTimeoutTime_SGW" SG_ 2566851331 _24VDcdcCur 1500;
BA_ "GenSigTimeoutTime_PCM" SG_ 2566851331 _24VDcdcCur 1500;
BA_ "GenSigTimeoutTime_ECM_MD1_G" SG_ 2566851331 _24VDcdcCur 1500;
BA_ "GenSigTimeoutTime_ECM_MD1_D" SG_ 2566851331 _24VDcdcCur 1500;
BA_ "GenSigStartValue" SG_ 2566851331 _24VDcdcCur 2000;
BA_ "CI_SigName" SG_ 2566851331 _24VDcdcCur "24V_DCDC_Current";
BA_ "CI_SigId" SG_ 2566851331 _24VDcdcCur 2313;
BA_ "CI_ParId" SG_ 2566851331 _24VDcdcCur "IB873";
BA_ "SigType" SG_ 2566851843 Celltemperaturemax 1;
BA_ "GenSigTimeoutTime_SGW" SG_ 2566851843 Celltemperaturemax 1500;
BA_ "GenSigTimeoutTime_PCM" SG_ 2566851843 Celltemperaturemax 1500;
BA_ "GenSigStartValue" SG_ 2566851843 Celltemperaturemax 40;
BA_ "CI_SigName" SG_ 2566851843 Celltemperaturemax "CellTemperatureMax";
BA_ "CI_SigId" SG_ 2566851843 Celltemperaturemax 2325;
BA_ "CI_ParId" SG_ 2566851843 Celltemperaturemax "IB888";
BA_ "GenSigTimeoutTime_SGW" SG_ 2566851843 Cellminvoltage 1500;
BA_ "GenSigTimeoutTime_PCM" SG_ 2566851843 Cellminvoltage 1500;
BA_ "CI_SigName" SG_ 2566851843 Cellminvoltage "CellMinVoltage";
BA_ "CI_SigId" SG_ 2566851843 Cellminvoltage 2324;
BA_ "CI_ParId" SG_ 2566851843 Cellminvoltage "IB887";
BA_ "GenSigTimeoutTime_SGW" SG_ 2566851843 Cellmaxvoltage 1500;
BA_ "GenSigTimeoutTime_PCM" SG_ 2566851843 Cellmaxvoltage 1500;
BA_ "CI_SigName" SG_ 2566851843 Cellmaxvoltage "CellMaxVoltage";
BA_ "CI_SigId" SG_ 2566851843 Cellmaxvoltage 2323;
BA_ "CI_ParId" SG_ 2566851843 Cellmaxvoltage "IB886";
BA_ "SigType" SG_ 2566851843 EMottemperature 1;
BA_ "GenSigTimeoutTime_SGW" SG_ 2566851843 EMottemperature 1500;
BA_ "GenSigTimeoutTime_PCM" SG_ 2566851843 EMottemperature 1500;
BA_ "GenSigStartValue" SG_ 2566851843 EMottemperature 40;
BA_ "CI_SigName" SG_ 2566851843 EMottemperature "E_MotorTemperature";
BA_ "CI_SigId" SG_ 2566851843 EMottemperature 2322;
BA_ "CI_ParId" SG_ 2566851843 EMottemperature "IB885";
BA_ "GenSigTimeoutTime_SGW" SG_ 2566851843 EMottractionpower 1500;
BA_ "GenSigTimeoutTime_PCM" SG_ 2566851843 EMottractionpower 1500;
BA_ "GenSigStartValue" SG_ 2566851843 EMottractionpower 2000;
BA_ "CI_SigName" SG_ 2566851843 EMottractionpower "E_MotorTractionPower";
BA_ "CI_SigId" SG_ 2566851843 EMottractionpower 2321;
BA_ "CI_ParId" SG_ 2566851843 EMottractionpower "IB884";
BA_ "GenSigTimeoutTime_SGW" SG_ 2566851843 EMotrecoverypower 1500;
BA_ "GenSigTimeoutTime_PCM" SG_ 2566851843 EMotrecoverypower 1500;
BA_ "GenSigStartValue" SG_ 2566851843 EMotrecoverypower 2000;
BA_ "CI_SigName" SG_ 2566851843 EMotrecoverypower "E_MotorRecoveryPower";
BA_ "CI_SigId" SG_ 2566851843 EMotrecoverypower 2320;
BA_ "CI_ParId" SG_ 2566851843 EMotrecoverypower "IB883";
BA_ "SigType" SG_ 2566891136 EmerUseCntCat6 1;
BA_ "GenSigTimeoutTime_SGW" SG_ 2566891136 EmerUseCntCat6 5000;
BA_ "GenSigTimeoutTime_PCM" SG_ 2566891136 EmerUseCntCat6 5000;
BA_ "CI_SigName" SG_ 2566891136 EmerUseCntCat6 "Emergency use counter CAT6";
BA_ "CI_SigId" SG_ 2566891136 EmerUseCntCat6 1380;
BA_ "CI_ParId" SG_ 2566891136 EmerUseCntCat6 "IB112";
BA_ "SigType" SG_ 2566891136 AbnormalUseCntCat5 1;
BA_ "GenSigTimeoutTime_SGW" SG_ 2566891136 AbnormalUseCntCat5 5000;
BA_ "GenSigTimeoutTime_PCM" SG_ 2566891136 AbnormalUseCntCat5 5000;
BA_ "CI_SigName" SG_ 2566891136 AbnormalUseCntCat5 "Abnormal use counter CAT5";
BA_ "CI_SigId" SG_ 2566891136 AbnormalUseCntCat5 1379;
BA_ "CI_ParId" SG_ 2566891136 AbnormalUseCntCat5 "IB111";
BA_ "SigType" SG_ 2566891136 AbnormalUseCntCat4 1;
BA_ "GenSigTimeoutTime_SGW" SG_ 2566891136 AbnormalUseCntCat4 5000;
BA_ "GenSigTimeoutTime_PCM" SG_ 2566891136 AbnormalUseCntCat4 5000;
BA_ "CI_SigName" SG_ 2566891136 AbnormalUseCntCat4 "Abnormal use counter CAT4";
BA_ "CI_SigId" SG_ 2566891136 AbnormalUseCntCat4 1378;
BA_ "CI_ParId" SG_ 2566891136 AbnormalUseCntCat4 "IB110";
BA_ "SigType" SG_ 2566891136 AbnormalUseCntCat3 1;
BA_ "GenSigTimeoutTime_SGW" SG_ 2566891136 AbnormalUseCntCat3 5000;
BA_ "GenSigTimeoutTime_PCM" SG_ 2566891136 AbnormalUseCntCat3 5000;
BA_ "CI_SigName" SG_ 2566891136 AbnormalUseCntCat3 "Abnormal use counter CAT3";
BA_ "CI_SigId" SG_ 2566891136 AbnormalUseCntCat3 1377;
BA_ "CI_ParId" SG_ 2566891136 AbnormalUseCntCat3 "IB109";
BA_ "SigType" SG_ 2566891136 AbnormalUseCntCat2 1;
BA_ "GenSigTimeoutTime_SGW" SG_ 2566891136 AbnormalUseCntCat2 5000;
BA_ "GenSigTimeoutTime_PCM" SG_ 2566891136 AbnormalUseCntCat2 5000;
BA_ "CI_SigName" SG_ 2566891136 AbnormalUseCntCat2 "Abnormal use counter CAT2";
BA_ "CI_SigId" SG_ 2566891136 AbnormalUseCntCat2 1376;
BA_ "CI_ParId" SG_ 2566891136 AbnormalUseCntCat2 "IB108";
BA_ "SigType" SG_ 2566891136 NormUseCntCat1 1;
BA_ "GenSigTimeoutTime_SGW" SG_ 2566891136 NormUseCntCat1 5000;
BA_ "GenSigTimeoutTime_PCM" SG_ 2566891136 NormUseCntCat1 5000;
BA_ "CI_SigName" SG_ 2566891136 NormUseCntCat1 "Normal use counter CAT1";
BA_ "CI_SigId" SG_ 2566891136 NormUseCntCat1 1375;
BA_ "CI_ParId" SG_ 2566891136 NormUseCntCat1 "IB107";
BA_ "SigType" SG_ 2566890880 EmerUseCntCat6_FFA580 1;
BA_ "GenSigTimeoutTime_SGW" SG_ 2566890880 EmerUseCntCat6_FFA580 5000;
BA_ "GenSigTimeoutTime_PCM" SG_ 2566890880 EmerUseCntCat6_FFA580 5000;
BA_ "CI_SigName" SG_ 2566890880 EmerUseCntCat6_FFA580 "Emergency use counter CAT6";
BA_ "CI_SigId" SG_ 2566890880 EmerUseCntCat6_FFA580 1387;
BA_ "CI_ParId" SG_ 2566890880 EmerUseCntCat6_FFA580 "IB112";
BA_ "SigType" SG_ 2566890880 AbnormalUseCntCat5_FFA580 1;
BA_ "GenSigTimeoutTime_SGW" SG_ 2566890880 AbnormalUseCntCat5_FFA580 5000;
BA_ "GenSigTimeoutTime_PCM" SG_ 2566890880 AbnormalUseCntCat5_FFA580 5000;
BA_ "CI_SigName" SG_ 2566890880 AbnormalUseCntCat5_FFA580 "Abnormal use counter CAT5";
BA_ "CI_SigId" SG_ 2566890880 AbnormalUseCntCat5_FFA580 1386;
BA_ "CI_ParId" SG_ 2566890880 AbnormalUseCntCat5_FFA580 "IB111";
BA_ "SigType" SG_ 2566890880 AbnormalUseCntCat4_FFA580 1;
BA_ "GenSigTimeoutTime_SGW" SG_ 2566890880 AbnormalUseCntCat4_FFA580 5000;
BA_ "GenSigTimeoutTime_PCM" SG_ 2566890880 AbnormalUseCntCat4_FFA580 5000;
BA_ "CI_SigName" SG_ 2566890880 AbnormalUseCntCat4_FFA580 "Abnormal use counter CAT4";
BA_ "CI_SigId" SG_ 2566890880 AbnormalUseCntCat4_FFA580 1385;
BA_ "CI_ParId" SG_ 2566890880 AbnormalUseCntCat4_FFA580 "IB110";
BA_ "SigType" SG_ 2566890880 AbnormalUseCntCat3_FFA580 1;
BA_ "GenSigTimeoutTime_SGW" SG_ 2566890880 AbnormalUseCntCat3_FFA580 5000;
BA_ "GenSigTimeoutTime_PCM" SG_ 2566890880 AbnormalUseCntCat3_FFA580 5000;
BA_ "CI_SigName" SG_ 2566890880 AbnormalUseCntCat3_FFA580 "Abnormal use counter CAT3";
BA_ "CI_SigId" SG_ 2566890880 AbnormalUseCntCat3_FFA580 1384;
BA_ "CI_ParId" SG_ 2566890880 AbnormalUseCntCat3_FFA580 "IB109";
BA_ "SigType" SG_ 2566890880 AbnormalUseCntCat2_FFA580 1;
BA_ "GenSigTimeoutTime_SGW" SG_ 2566890880 AbnormalUseCntCat2_FFA580 5000;
BA_ "GenSigTimeoutTime_PCM" SG_ 2566890880 AbnormalUseCntCat2_FFA580 5000;
BA_ "CI_SigName" SG_ 2566890880 AbnormalUseCntCat2_FFA580 "Abnormal use counter CAT2";
BA_ "CI_SigId" SG_ 2566890880 AbnormalUseCntCat2_FFA580 1383;
BA_ "CI_ParId" SG_ 2566890880 AbnormalUseCntCat2_FFA580 "IB108";
BA_ "SigType" SG_ 2566890880 NormUseCntCat1_FFA580 1;
BA_ "GenSigTimeoutTime_SGW" SG_ 2566890880 NormUseCntCat1_FFA580 5000;
BA_ "GenSigTimeoutTime_PCM" SG_ 2566890880 NormUseCntCat1_FFA580 5000;
BA_ "CI_SigName" SG_ 2566890880 NormUseCntCat1_FFA580 "Normal use counter CAT1";
BA_ "CI_SigId" SG_ 2566890880 NormUseCntCat1_FFA580 1382;
BA_ "CI_ParId" SG_ 2566890880 NormUseCntCat1_FFA580 "IB107";
BA_ "GenSigTimeoutTime_SGW" SG_ 2566890368 CurSensSysSts 25000;
BA_ "GenSigTimeoutTime_PCM" SG_ 2566890368 CurSensSysSts 25000;
BA_ "CI_SigName" SG_ 2566890368 CurSensSysSts "Current Sensor System State";
BA_ "CI_SigId" SG_ 2566890368 CurSensSysSts 1395;
BA_ "CI_ParId" SG_ 2566890368 CurSensSysSts "IB119";
BA_ "GenSigTimeoutTime_VMU" SG_ 2566890368 Errcode 25000;
BA_ "GenSigTimeoutTime_VCU" SG_ 2566890368 Errcode 25000;
BA_ "GenSigTimeoutTime_SGW" SG_ 2566890368 Errcode 25000;
BA_ "GenSigTimeoutTime_PCM" SG_ 2566890368 Errcode 25000;
BA_ "CI_SigName" SG_ 2566890368 Errcode "ErrorCode";
BA_ "CI_SigId" SG_ 2566890368 Errcode 1394;
BA_ "CI_ParId" SG_ 2566890368 Errcode "IB118";
BA_ "SigType" SG_ 2566890368 DicoTemp 1;
BA_ "GenSigTimeoutTime_SGW" SG_ 2566890368 DicoTemp 25000;
BA_ "GenSigTimeoutTime_PCM" SG_ 2566890368 DicoTemp 25000;
BA_ "GenSigStartValue" SG_ 2566890368 DicoTemp 40;
BA_ "CI_SigName" SG_ 2566890368 DicoTemp "DICO Temperature";
BA_ "CI_SigId" SG_ 2566890368 DicoTemp 1393;
BA_ "CI_ParId" SG_ 2566890368 DicoTemp "IB117";
BA_ "SigType" SG_ 2566890368 PrototypePt1000Temp 1;
BA_ "GenSigTimeoutTime_VMU" SG_ 2566890368 PrototypePt1000Temp 25000;
BA_ "GenSigTimeoutTime_VCU" SG_ 2566890368 PrototypePt1000Temp 25000;
BA_ "GenSigTimeoutTime_SGW" SG_ 2566890368 PrototypePt1000Temp 25000;
BA_ "GenSigTimeoutTime_PCM" SG_ 2566890368 PrototypePt1000Temp 25000;
BA_ "GenSigStartValue" SG_ 2566890368 PrototypePt1000Temp 40;
BA_ "CI_SigName" SG_ 2566890368 PrototypePt1000Temp "Prototype PT1000 Temperature";
BA_ "CI_SigId" SG_ 2566890368 PrototypePt1000Temp 1392;
BA_ "CI_ParId" SG_ 2566890368 PrototypePt1000Temp "IB116";
BA_ "SigType" SG_ 2566890368 TempCurSens 1;
BA_ "GenSigTimeoutTime_SGW" SG_ 2566890368 TempCurSens 25000;
BA_ "GenSigTimeoutTime_PCM" SG_ 2566890368 TempCurSens 25000;
BA_ "GenSigStartValue" SG_ 2566890368 TempCurSens 40;
BA_ "CI_SigName" SG_ 2566890368 TempCurSens "Temperature Current Sensor";
BA_ "CI_SigId" SG_ 2566890368 TempCurSens 1391;
BA_ "CI_ParId" SG_ 2566890368 TempCurSens "IB115";
BA_ "SigType" SG_ 2566890368 OpportunitySwstateofhealth 1;
BA_ "GenSigTimeoutTime_SGW" SG_ 2566890368 OpportunitySwstateofhealth 25000;
BA_ "GenSigTimeoutTime_PCM" SG_ 2566890368 OpportunitySwstateofhealth 25000;
BA_ "CI_SigName" SG_ 2566890368 OpportunitySwstateofhealth "Opportunity SwitchStateOfHealth";
BA_ "CI_SigId" SG_ 2566890368 OpportunitySwstateofhealth 1390;
BA_ "CI_ParId" SG_ 2566890368 OpportunitySwstateofhealth "IB114";
BA_ "SigType" SG_ 2566890368 OvernightContactStsofhealth 1;
BA_ "GenSigTimeoutTime_SGW" SG_ 2566890368 OvernightContactStsofhealth 25000;
BA_ "GenSigTimeoutTime_PCM" SG_ 2566890368 OvernightContactStsofhealth 25000;
BA_ "CI_SigName" SG_ 2566890368 OvernightContactStsofhealth "Overnight Contactor StateOfHealth";
BA_ "CI_SigId" SG_ 2566890368 OvernightContactStsofhealth 1389;
BA_ "CI_ParId" SG_ 2566890368 OvernightContactStsofhealth "IB113";
BA_ "SigType" SG_ 2364575834 HvessCur 1;
BA_ "SPN" SG_ 2364575834 HvessCur 5920;
BA_ "GenSigTimeoutTime_SGW" SG_ 2364575834 HvessCur 5000;
BA_ "GenSigTimeoutTime_PCM" SG_ 2364575834 HvessCur 5000;
BA_ "GenSigTimeoutTime_MPPxPTFE2" SG_ 2364575834 HvessCur 5000;
BA_ "GenSigTimeoutTime_IC_MulticII" SG_ 2364575834 HvessCur 5000;
BA_ "GenSigTimeoutTime_FMS_FMS4" SG_ 2364575834 HvessCur 5000;
BA_ "GenSigStartValue" SG_ 2364575834 HvessCur 32000;
BA_ "CI_SigName" SG_ 2364575834 HvessCur "HVESS Current";
BA_ "CI_SigId" SG_ 2364575834 HvessCur 2330;
BA_ "CI_ParId" SG_ 2364575834 HvessCur "5920";
BA_ "SigType" SG_ 2364575834 HvessVLev 1;
BA_ "SPN" SG_ 2364575834 HvessVLev 5919;
BA_ "GenSigTimeoutTime_SGW" SG_ 2364575834 HvessVLev 5000;
BA_ "GenSigTimeoutTime_PCM" SG_ 2364575834 HvessVLev 5000;
BA_ "GenSigTimeoutTime_MPPxPTFE2" SG_ 2364575834 HvessVLev 5000;
BA_ "GenSigTimeoutTime_IC_MulticII" SG_ 2364575834 HvessVLev 5000;
BA_ "GenSigTimeoutTime_FMS_FMS4" SG_ 2364575834 HvessVLev 5000;
BA_ "CI_SigName" SG_ 2364575834 HvessVLev "HVESS Voltage Level";
BA_ "CI_SigId" SG_ 2364575834 HvessVLev 2329;
BA_ "CI_ParId" SG_ 2364575834 HvessVLev "5919";
BA_ "SigType" SG_ 2364575834 HvessAvChgPwr 1;
BA_ "SPN" SG_ 2364575834 HvessAvChgPwr 5918;
BA_ "GenSigTimeoutTime_SGW" SG_ 2364575834 HvessAvChgPwr 5000;
BA_ "GenSigTimeoutTime_PCM" SG_ 2364575834 HvessAvChgPwr 5000;
BA_ "GenSigTimeoutTime_MPPxPTFE2" SG_ 2364575834 HvessAvChgPwr 5000;
BA_ "GenSigTimeoutTime_IC_MulticII" SG_ 2364575834 HvessAvChgPwr 5000;
BA_ "GenSigTimeoutTime_FMS_FMS4" SG_ 2364575834 HvessAvChgPwr 5000;
BA_ "CI_SigName" SG_ 2364575834 HvessAvChgPwr "HVESS Available Charge Power";
BA_ "CI_SigId" SG_ 2364575834 HvessAvChgPwr 2328;
BA_ "CI_ParId" SG_ 2364575834 HvessAvChgPwr "5918";
BA_ "SigType" SG_ 2364575834 HvessAvDischPwr 1;
BA_ "SPN" SG_ 2364575834 HvessAvDischPwr 5917;
BA_ "GenSigTimeoutTime_SGW" SG_ 2364575834 HvessAvDischPwr 5000;
BA_ "GenSigTimeoutTime_PCM" SG_ 2364575834 HvessAvDischPwr 5000;
BA_ "GenSigTimeoutTime_MPPxPTFE2" SG_ 2364575834 HvessAvDischPwr 5000;
BA_ "GenSigTimeoutTime_IC_MulticII" SG_ 2364575834 HvessAvDischPwr 5000;
BA_ "GenSigTimeoutTime_FMS_FMS4" SG_ 2364575834 HvessAvDischPwr 5000;
BA_ "CI_SigName" SG_ 2364575834 HvessAvDischPwr "HVESS Available Discharge Power";
BA_ "CI_SigId" SG_ 2364575834 HvessAvDischPwr 2327;
BA_ "CI_ParId" SG_ 2364575834 HvessAvDischPwr "5917";
BA_ "SigType" SG_ 2365349619 HvessTotAccumChg 1;
BA_ "SPN" SG_ 2365349619 HvessTotAccumChg 8212;
BA_ "GenSigTimeoutTime_SGW" SG_ 2365349619 HvessTotAccumChg 5000;
BA_ "GenSigTimeoutTime_PCM" SG_ 2365349619 HvessTotAccumChg 5000;
BA_ "CI_SigName" SG_ 2365349619 HvessTotAccumChg "HVESS Total Accumulated Charge";
BA_ "CI_SigId" SG_ 2365349619 HvessTotAccumChg 2522;
BA_ "CI_ParId" SG_ 2365349619 HvessTotAccumChg "8212";
BA_ "SigType" SG_ 2365349619 HvessTotEnergyTput 1;
BA_ "SPN" SG_ 2365349619 HvessTotEnergyTput 8211;
BA_ "GenSigTimeoutTime_SGW" SG_ 2365349619 HvessTotEnergyTput 5000;
BA_ "GenSigTimeoutTime_PCM" SG_ 2365349619 HvessTotEnergyTput 5000;
BA_ "CI_SigName" SG_ 2365349619 HvessTotEnergyTput "HVESS Total Energy Throughput";
BA_ "CI_SigId" SG_ 2365349619 HvessTotEnergyTput 2521;
BA_ "CI_ParId" SG_ 2365349619 HvessTotEnergyTput "8211";
BA_ "SigType" SG_ 2365349619 HvessSoh 1;
BA_ "SPN" SG_ 2365349619 HvessSoh 8121;
BA_ "GenSigTimeoutTime_SGW" SG_ 2365349619 HvessSoh 5000;
BA_ "GenSigTimeoutTime_PCM" SG_ 2365349619 HvessSoh 5000;
BA_ "CI_SigName" SG_ 2365349619 HvessSoh "HVESS State of Health";
BA_ "CI_SigId" SG_ 2365349619 HvessSoh 2519;
BA_ "CI_ParId" SG_ 2365349619 HvessSoh "8121";
BA_ "SigType" SG_ 2566845952 EngExhTemp 1;
BA_ "SPN" SG_ 2566845952 EngExhTemp 173;
BA_ "GenSigTimeoutTime_VCM" SG_ 2566845952 EngExhTemp 500;
BA_ "GenSigTimeoutTime_SGW" SG_ 2566845952 EngExhTemp 500;
BA_ "GenSigTimeoutTime_PCM" SG_ 2566845952 EngExhTemp 500;
BA_ "GenSigTimeoutTime_FMS_FMS5" SG_ 2566845952 EngExhTemp 500;
BA_ "GenSigTimeoutTime_FMS_FMS4" SG_ 2566845952 EngExhTemp 500;
BA_ "GenSigTimeoutTime_BCM_NBM" SG_ 2566845952 EngExhTemp 500;
BA_ "GenSigStartValue" SG_ 2566845952 EngExhTemp 8736;
BA_ "CI_SigName" SG_ 2566845952 EngExhTemp "Engine Exhaust Temperature";
BA_ "CI_SigId" SG_ 2566845952 EngExhTemp 1103;
BA_ "CI_ParId" SG_ 2566845952 EngExhTemp "173";
BA_ "SigType" SG_ 2566845952 EngInMan1Temp 1;
BA_ "SPN" SG_ 2566845952 EngInMan1Temp 105;
BA_ "GenSigTimeoutTime_VCM" SG_ 2566845952 EngInMan1Temp 500;
BA_ "GenSigTimeoutTime_SGW" SG_ 2566845952 EngInMan1Temp 500;
BA_ "GenSigTimeoutTime_PCM" SG_ 2566845952 EngInMan1Temp 500;
BA_ "GenSigTimeoutTime_FMS_FMS5" SG_ 2566845952 EngInMan1Temp 500;
BA_ "GenSigTimeoutTime_FMS_FMS4" SG_ 2566845952 EngInMan1Temp 500;
BA_ "GenSigTimeoutTime_BCM_NBM" SG_ 2566845952 EngInMan1Temp 500;
BA_ "GenSigStartValue" SG_ 2566845952 EngInMan1Temp 40;
BA_ "CI_SigName" SG_ 2566845952 EngInMan1Temp "Engine Intake Manifold 1 Temperature";
BA_ "CI_SigId" SG_ 2566845952 EngInMan1Temp 1100;
BA_ "CI_ParId" SG_ 2566845952 EngInMan1Temp "105";
BA_ "SigType" SG_ 2566845952 EngInMan1Prs 1;
BA_ "SPN" SG_ 2566845952 EngInMan1Prs 102;
BA_ "GenSigTimeoutTime_VCM" SG_ 2566845952 EngInMan1Prs 500;
BA_ "GenSigTimeoutTime_SGW" SG_ 2566845952 EngInMan1Prs 500;
BA_ "GenSigTimeoutTime_PCM" SG_ 2566845952 EngInMan1Prs 500;
BA_ "GenSigTimeoutTime_IC_MulticS" SG_ 2566845952 EngInMan1Prs 500;
BA_ "GenSigTimeoutTime_FMS_FMS5" SG_ 2566845952 EngInMan1Prs 500;
BA_ "GenSigTimeoutTime_FMS_FMS4" SG_ 2566845952 EngInMan1Prs 500;
BA_ "GenSigTimeoutTime_DMS" SG_ 2566845952 EngInMan1Prs 500;
BA_ "GenSigTimeoutTime_BCM_NBM" SG_ 2566845952 EngInMan1Prs 500;
BA_ "GenSigTimeoutTime_Av2HP" SG_ 2566845952 EngInMan1Prs 500;
BA_ "GenSigTimeoutTime_ADCU" SG_ 2566845952 EngInMan1Prs 500;
BA_ "CI_SigName" SG_ 2566845952 EngInMan1Prs "Engine Intake Manifold #1 Pressure";
BA_ "CI_SigId" SG_ 2566845952 EngInMan1Prs 1099;
BA_ "CI_ParId" SG_ 2566845952 EngInMan1Prs "102";
BA_ "SigType" SG_ 2566910080 Aux2DcPwr 1;
BA_ "GenSigTimeoutTime_SGW" SG_ 2566910080 Aux2DcPwr 2500;
BA_ "GenSigTimeoutTime_PCM" SG_ 2566910080 Aux2DcPwr 2500;
BA_ "GenSigTimeoutTime_MPPxPTFE2" SG_ 2566910080 Aux2DcPwr 2500;
BA_ "GenSigTimeoutTime_IC_MulticII" SG_ 2566910080 Aux2DcPwr 2500;
BA_ "GenSigTimeoutTime_FMS_FMS4" SG_ 2566910080 Aux2DcPwr 2500;
BA_ "CI_SigName" SG_ 2566910080 Aux2DcPwr "Auxiliary2 DC Power";
BA_ "CI_SigId" SG_ 2566910080 Aux2DcPwr 1128;
BA_ "CI_ParId" SG_ 2566910080 Aux2DcPwr "IB057";
BA_ "SigType" SG_ 2566910080 Aux2AcPwr 1;
BA_ "GenSigTimeoutTime_SGW" SG_ 2566910080 Aux2AcPwr 2500;
BA_ "GenSigTimeoutTime_PCM" SG_ 2566910080 Aux2AcPwr 2500;
BA_ "GenSigTimeoutTime_MPPxPTFE2" SG_ 2566910080 Aux2AcPwr 2500;
BA_ "GenSigTimeoutTime_IC_MulticII" SG_ 2566910080 Aux2AcPwr 2500;
BA_ "GenSigTimeoutTime_FMS_FMS4" SG_ 2566910080 Aux2AcPwr 2500;
BA_ "CI_SigName" SG_ 2566910080 Aux2AcPwr "Auxiliary2 AC Power";
BA_ "CI_SigId" SG_ 2566910080 Aux2AcPwr 1127;
BA_ "CI_ParId" SG_ 2566910080 Aux2AcPwr "IB056";
BA_ "SigType" SG_ 2566910080 Aux1DcPwr 1;
BA_ "GenSigTimeoutTime_SGW" SG_ 2566910080 Aux1DcPwr 2500;
BA_ "GenSigTimeoutTime_PCM" SG_ 2566910080 Aux1DcPwr 2500;
BA_ "GenSigTimeoutTime_MPPxPTFE2" SG_ 2566910080 Aux1DcPwr 2500;
BA_ "GenSigTimeoutTime_IC_MulticII" SG_ 2566910080 Aux1DcPwr 2500;
BA_ "GenSigTimeoutTime_FMS_FMS4" SG_ 2566910080 Aux1DcPwr 2500;
BA_ "CI_SigName" SG_ 2566910080 Aux1DcPwr "Auxiliary1 DC Power";
BA_ "CI_SigId" SG_ 2566910080 Aux1DcPwr 1126;
BA_ "CI_ParId" SG_ 2566910080 Aux1DcPwr "IB055";
BA_ "SigType" SG_ 2566910080 Aux1AcPwr 1;
BA_ "GenSigTimeoutTime_SGW" SG_ 2566910080 Aux1AcPwr 2500;
BA_ "GenSigTimeoutTime_PCM" SG_ 2566910080 Aux1AcPwr 2500;
BA_ "GenSigTimeoutTime_MPPxPTFE2" SG_ 2566910080 Aux1AcPwr 2500;
BA_ "GenSigTimeoutTime_IC_MulticII" SG_ 2566910080 Aux1AcPwr 2500;
BA_ "GenSigTimeoutTime_FMS_FMS4" SG_ 2566910080 Aux1AcPwr 2500;
BA_ "CI_SigName" SG_ 2566910080 Aux1AcPwr "Auxiliary1 AC Power";
BA_ "CI_SigId" SG_ 2566910080 Aux1AcPwr 1125;
BA_ "CI_ParId" SG_ 2566910080 Aux1AcPwr "IB054";
BA_ "SigType" SG_ 2566910080 EngCur 1;
BA_ "GenSigTimeoutTime_SGW" SG_ 2566910080 EngCur 2500;
BA_ "GenSigTimeoutTime_PCM" SG_ 2566910080 EngCur 2500;
BA_ "GenSigTimeoutTime_MPPxPTFE2" SG_ 2566910080 EngCur 2500;
BA_ "GenSigTimeoutTime_IC_MulticII" SG_ 2566910080 EngCur 2500;
BA_ "GenSigTimeoutTime_FMS_FMS4" SG_ 2566910080 EngCur 2500;
BA_ "GenSigStartValue" SG_ 2566910080 EngCur 125;
BA_ "CI_SigName" SG_ 2566910080 EngCur "Engine Current";
BA_ "CI_SigId" SG_ 2566910080 EngCur 1124;
BA_ "CI_ParId" SG_ 2566910080 EngCur "IB053";
BA_ "SigType" SG_ 2566910080 EngV 1;
BA_ "GenSigTimeoutTime_SGW" SG_ 2566910080 EngV 2500;
BA_ "GenSigTimeoutTime_PCM" SG_ 2566910080 EngV 2500;
BA_ "GenSigTimeoutTime_MPPxPTFE2" SG_ 2566910080 EngV 2500;
BA_ "GenSigTimeoutTime_IC_MulticII" SG_ 2566910080 EngV 2500;
BA_ "GenSigTimeoutTime_FMS_FMS4" SG_ 2566910080 EngV 2500;
BA_ "CI_SigName" SG_ 2566910080 EngV "Engine Voltage";
BA_ "CI_SigId" SG_ 2566910080 EngV 1123;
BA_ "CI_ParId" SG_ 2566910080 EngV "IB052";
BA_ "SigType" SG_ 2566910080 EngPwrLoss 1;
BA_ "GenSigTimeoutTime_SGW" SG_ 2566910080 EngPwrLoss 2500;
BA_ "GenSigTimeoutTime_PCM" SG_ 2566910080 EngPwrLoss 2500;
BA_ "GenSigTimeoutTime_MPPxPTFE2" SG_ 2566910080 EngPwrLoss 2500;
BA_ "GenSigTimeoutTime_IC_MulticII" SG_ 2566910080 EngPwrLoss 2500;
BA_ "GenSigTimeoutTime_FMS_FMS4" SG_ 2566910080 EngPwrLoss 2500;
BA_ "CI_SigName" SG_ 2566910080 EngPwrLoss "Engine Power Losses";
BA_ "CI_SigId" SG_ 2566910080 EngPwrLoss 1122;
BA_ "CI_ParId" SG_ 2566910080 EngPwrLoss "IB051";
BA_ "SigType" SG_ 2566910080 EngPwrInfo 1;
BA_ "GenSigTimeoutTime_SGW" SG_ 2566910080 EngPwrInfo 2500;
BA_ "GenSigTimeoutTime_PCM" SG_ 2566910080 EngPwrInfo 2500;
BA_ "GenSigTimeoutTime_MPPxPTFE2" SG_ 2566910080 EngPwrInfo 2500;
BA_ "GenSigTimeoutTime_IC_MulticII" SG_ 2566910080 EngPwrInfo 2500;
BA_ "GenSigTimeoutTime_FMS_FMS4" SG_ 2566910080 EngPwrInfo 2500;
BA_ "GenSigStartValue" SG_ 2566910080 EngPwrInfo 125;
BA_ "CI_SigName" SG_ 2566910080 EngPwrInfo "Engine Power Information";
BA_ "CI_SigId" SG_ 2566910080 EngPwrInfo 1121;
BA_ "CI_ParId" SG_ 2566910080 EngPwrInfo "IB050";
BA_ "SigType" SG_ 2566909824 Aux3DcPwr 1;
BA_ "GenSigTimeoutTime_SGW" SG_ 2566909824 Aux3DcPwr 5000;
BA_ "GenSigTimeoutTime_PCM" SG_ 2566909824 Aux3DcPwr 5000;
BA_ "GenSigTimeoutTime_MPPxPTFE2" SG_ 2566909824 Aux3DcPwr 5000;
BA_ "GenSigTimeoutTime_FMS_FMS4" SG_ 2566909824 Aux3DcPwr 5000;
BA_ "GenSigTimeoutTime_BCM_NBM" SG_ 2566909824 Aux3DcPwr 5000;
BA_ "CI_SigName" SG_ 2566909824 Aux3DcPwr "Auxiliary3 DC Power";
BA_ "CI_SigId" SG_ 2566909824 Aux3DcPwr 20551;
BA_ "CI_ParId" SG_ 2566909824 Aux3DcPwr "IB3999";
BA_ "SigType" SG_ 2566909824 Aux3AcPwr 1;
BA_ "GenSigTimeoutTime_SGW" SG_ 2566909824 Aux3AcPwr 5000;
BA_ "GenSigTimeoutTime_PCM" SG_ 2566909824 Aux3AcPwr 5000;
BA_ "GenSigTimeoutTime_MPPxPTFE2" SG_ 2566909824 Aux3AcPwr 5000;
BA_ "GenSigTimeoutTime_IC_MulticII" SG_ 2566909824 Aux3AcPwr 5000;
BA_ "GenSigTimeoutTime_FMS_FMS4" SG_ 2566909824 Aux3AcPwr 5000;
BA_ "GenSigTimeoutTime_BCM_NBM" SG_ 2566909824 Aux3AcPwr 5000;
BA_ "CI_SigName" SG_ 2566909824 Aux3AcPwr "Auxiliary3 AC Power";
BA_ "CI_SigId" SG_ 2566909824 Aux3AcPwr 20550;
BA_ "CI_ParId" SG_ 2566909824 Aux3AcPwr "IB3998";
BA_ "SigType" SG_ 2566909824 HighVEnergyChgdTot 1;
BA_ "GenSigTimeoutTime_SGW" SG_ 2566909824 HighVEnergyChgdTot 5000;
BA_ "GenSigTimeoutTime_PCM" SG_ 2566909824 HighVEnergyChgdTot 5000;
BA_ "GenSigTimeoutTime_MPPxPTFE2" SG_ 2566909824 HighVEnergyChgdTot 5000;
BA_ "GenSigTimeoutTime_IC_MulticS" SG_ 2566909824 HighVEnergyChgdTot 5000;
BA_ "GenSigTimeoutTime_FMS_FMS4" SG_ 2566909824 HighVEnergyChgdTot 5000;
BA_ "GenSigTimeoutTime_BCM_NBM" SG_ 2566909824 HighVEnergyChgdTot 5000;
BA_ "CI_SigName" SG_ 2566909824 HighVEnergyChgdTot "High Voltage Energy Charged Total";
BA_ "CI_SigId" SG_ 2566909824 HighVEnergyChgdTot 1130;
BA_ "CI_ParId" SG_ 2566909824 HighVEnergyChgdTot "IB058";
BA_ "SigType" SG_ 2566786839 LangCodeCmd 3;
BA_ "SPN" SG_ 2566786839 LangCodeCmd 2410;
BA_ "GenSigTimeoutTime_SGW" SG_ 2566786839 LangCodeCmd 5000;
BA_ "GenSigTimeoutTime_PCM" SG_ 2566786839 LangCodeCmd 5000;
BA_ "CI_SigName" SG_ 2566786839 LangCodeCmd "Language Code Command";
BA_ "CI_SigId" SG_ 2566786839 LangCodeCmd 2645;
BA_ "CI_ParId" SG_ 2566786839 LangCodeCmd "2410";
BA_ "SigType" SG_ 2566842624 EngTotFuelUsed 1;
BA_ "SPN" SG_ 2566842624 EngTotFuelUsed 250;
BA_ "GenSigTimeoutTime_VCM" SG_ 2566842624 EngTotFuelUsed 5000;
BA_ "GenSigTimeoutTime_SGW" SG_ 2566842624 EngTotFuelUsed 5000;
BA_ "GenSigTimeoutTime_PCM" SG_ 2566842624 EngTotFuelUsed 5000;
BA_ "GenSigTimeoutTime_IC_MulticS" SG_ 2566842624 EngTotFuelUsed 5000;
BA_ "GenSigTimeoutTime_FMS_FMS5" SG_ 2566842624 EngTotFuelUsed 5000;
BA_ "GenSigTimeoutTime_FMS_FMS4" SG_ 2566842624 EngTotFuelUsed 5000;
BA_ "CI_SigName" SG_ 2566842624 EngTotFuelUsed "Engine Total Fuel Used";
BA_ "CI_SigId" SG_ 2566842624 EngTotFuelUsed 1107;
BA_ "CI_ParId" SG_ 2566842624 EngTotFuelUsed "250";
BA_ "SigType" SG_ 2566844928 EngAvgFuelEcon 1;
BA_ "SPN" SG_ 2566844928 EngAvgFuelEcon 185;
BA_ "GenSigTimeoutTime_VCM" SG_ 2566844928 EngAvgFuelEcon 500;
BA_ "GenSigTimeoutTime_SGW" SG_ 2566844928 EngAvgFuelEcon 500;
BA_ "GenSigTimeoutTime_PCM" SG_ 2566844928 EngAvgFuelEcon 500;
BA_ "CI_SigName" SG_ 2566844928 EngAvgFuelEcon "Engine Average Fuel Economy";
BA_ "CI_SigId" SG_ 2566844928 EngAvgFuelEcon 1175;
BA_ "CI_ParId" SG_ 2566844928 EngAvgFuelEcon "185";
BA_ "SigType" SG_ 2566844928 EngInstFuelEcon 1;
BA_ "SPN" SG_ 2566844928 EngInstFuelEcon 184;
BA_ "GenSigTimeoutTime_VCM" SG_ 2566844928 EngInstFuelEcon 500;
BA_ "GenSigTimeoutTime_SGW" SG_ 2566844928 EngInstFuelEcon 500;
BA_ "GenSigTimeoutTime_PCM" SG_ 2566844928 EngInstFuelEcon 500;
BA_ "GenSigTimeoutTime_IC_MulticS" SG_ 2566844928 EngInstFuelEcon 500;
BA_ "GenSigTimeoutTime_FMS_FMS5" SG_ 2566844928 EngInstFuelEcon 500;
BA_ "GenSigTimeoutTime_FMS_FMS4" SG_ 2566844928 EngInstFuelEcon 500;
BA_ "CI_SigName" SG_ 2566844928 EngInstFuelEcon "Engine Instantaneous Fuel Economy";
BA_ "CI_SigId" SG_ 2566844928 EngInstFuelEcon 1174;
BA_ "CI_ParId" SG_ 2566844928 EngInstFuelEcon "184";
BA_ "SigType" SG_ 2566844928 EngFuelRate 1;
BA_ "SPN" SG_ 2566844928 EngFuelRate 183;
BA_ "GenSigTimeoutTime_VCM" SG_ 2566844928 EngFuelRate 500;
BA_ "GenSigTimeoutTime_SGW" SG_ 2566844928 EngFuelRate 500;
BA_ "GenSigTimeoutTime_PCM" SG_ 2566844928 EngFuelRate 500;
BA_ "GenSigTimeoutTime_IC_MulticS" SG_ 2566844928 EngFuelRate 500;
BA_ "GenSigTimeoutTime_FMS_FMS5" SG_ 2566844928 EngFuelRate 500;
BA_ "GenSigTimeoutTime_FMS_FMS4" SG_ 2566844928 EngFuelRate 500;
BA_ "CI_SigName" SG_ 2566844928 EngFuelRate "Engine Fuel Rate";
BA_ "CI_SigId" SG_ 2566844928 EngFuelRate 1173;
BA_ "CI_ParId" SG_ 2566844928 EngFuelRate "183";
BA_ "SigType" SG_ 2566861299 ChgComplSts 4;
BA_ "GenSigTimeoutTime_SGW" SG_ 2566861299 ChgComplSts 25000;
BA_ "GenSigTimeoutTime_PCM" SG_ 2566861299 ChgComplSts 25000;
BA_ "GenSigTimeoutTime_MPPxPTFE2" SG_ 2566861299 ChgComplSts 25000;
BA_ "GenSigTimeoutTime_IC_MulticS" SG_ 2566861299 ChgComplSts 25000;
BA_ "GenSigTimeoutTime_FMS_FMS4" SG_ 2566861299 ChgComplSts 25000;
BA_ "CI_SigName" SG_ 2566861299 ChgComplSts "Charge Complete Status";
BA_ "CI_SigId" SG_ 2566861299 ChgComplSts 1493;
BA_ "CI_ParId" SG_ 2566861299 ChgComplSts "IB188";
BA_ "SigType" SG_ 2566861299 MaxSysDischCur 1;
BA_ "GenSigTimeoutTime_SGW" SG_ 2566861299 MaxSysDischCur 25000;
BA_ "GenSigTimeoutTime_PCM" SG_ 2566861299 MaxSysDischCur 25000;
BA_ "GenSigTimeoutTime_MPPxPTFE2" SG_ 2566861299 MaxSysDischCur 25000;
BA_ "GenSigTimeoutTime_IC_MulticS" SG_ 2566861299 MaxSysDischCur 25000;
BA_ "GenSigTimeoutTime_FMS_FMS4" SG_ 2566861299 MaxSysDischCur 25000;
BA_ "CI_SigName" SG_ 2566861299 MaxSysDischCur "Maximum System Discharge Current";
BA_ "CI_SigId" SG_ 2566861299 MaxSysDischCur 1486;
BA_ "CI_ParId" SG_ 2566861299 MaxSysDischCur "IB182";
BA_ "SigType" SG_ 2566861299 MaxSysChgCur 1;
BA_ "GenSigTimeoutTime_SGW" SG_ 2566861299 MaxSysChgCur 25000;
BA_ "GenSigTimeoutTime_PCM" SG_ 2566861299 MaxSysChgCur 25000;
BA_ "GenSigTimeoutTime_MPPxPTFE2" SG_ 2566861299 MaxSysChgCur 25000;
BA_ "GenSigTimeoutTime_IC_MulticS" SG_ 2566861299 MaxSysChgCur 25000;
BA_ "GenSigTimeoutTime_FMS_FMS4" SG_ 2566861299 MaxSysChgCur 25000;
BA_ "CI_SigName" SG_ 2566861299 MaxSysChgCur "Maximum System Charge Current";
BA_ "CI_SigId" SG_ 2566861299 MaxSysChgCur 1485;
BA_ "CI_ParId" SG_ 2566861299 MaxSysChgCur "IB181";
BA_ "SigType" SG_ 2566861299 ActBatSysCur 1;
BA_ "GenSigTimeoutTime_SGW" SG_ 2566861299 ActBatSysCur 25000;
BA_ "GenSigTimeoutTime_PCM" SG_ 2566861299 ActBatSysCur 25000;
BA_ "GenSigTimeoutTime_MPPxPTFE2" SG_ 2566861299 ActBatSysCur 25000;
BA_ "GenSigTimeoutTime_IC_MulticS" SG_ 2566861299 ActBatSysCur 25000;
BA_ "GenSigTimeoutTime_FMS_FMS4" SG_ 2566861299 ActBatSysCur 25000;
BA_ "GenSigStartValue" SG_ 2566861299 ActBatSysCur 125;
BA_ "CI_SigName" SG_ 2566861299 ActBatSysCur "Actual Battery System Current";
BA_ "CI_SigId" SG_ 2566861299 ActBatSysCur 1484;
BA_ "CI_ParId" SG_ 2566861299 ActBatSysCur "IB180";
BA_ "SigType" SG_ 2566861299 ActBatSysV 1;
BA_ "GenSigTimeoutTime_SGW" SG_ 2566861299 ActBatSysV 25000;
BA_ "GenSigTimeoutTime_PCM" SG_ 2566861299 ActBatSysV 25000;
BA_ "GenSigTimeoutTime_MPPxPTFE2" SG_ 2566861299 ActBatSysV 25000;
BA_ "GenSigTimeoutTime_IC_MulticS" SG_ 2566861299 ActBatSysV 25000;
BA_ "GenSigTimeoutTime_FMS_FMS4" SG_ 2566861299 ActBatSysV 25000;
BA_ "GenSigTimeoutTime_ACM_CANAIR" SG_ 2566861299 ActBatSysV 25000;
BA_ "CI_SigName" SG_ 2566861299 ActBatSysV "Actual Battery System Voltage";
BA_ "CI_SigId" SG_ 2566861299 ActBatSysV 1483;
BA_ "CI_ParId" SG_ 2566861299 ActBatSysV "IB179";
BA_ "SigType" SG_ 2566861351 ActBatSysSoc 1;
BA_ "GenSigTimeoutTime_VMU" SG_ 2566861351 ActBatSysSoc 5000;
BA_ "GenSigTimeoutTime_VCU" SG_ 2566861351 ActBatSysSoc 5000;
BA_ "CI_SigName" SG_ 2566861351 ActBatSysSoc "Actual Battery System State Of Charge";
BA_ "CI_SigId" SG_ 2566861351 ActBatSysSoc 1520;
BA_ "CI_ParId" SG_ 2566861351 ActBatSysSoc "IB192";
BA_ "SigType" SG_ 2566861351 MinBatSysTemp 1;
BA_ "GenSigTimeoutTime_VMU" SG_ 2566861351 MinBatSysTemp 5000;
BA_ "GenSigTimeoutTime_VCU" SG_ 2566861351 MinBatSysTemp 5000;
BA_ "GenSigStartValue" SG_ 2566861351 MinBatSysTemp 40;
BA_ "CI_SigName" SG_ 2566861351 MinBatSysTemp "Minimum Battery System Temperature";
BA_ "CI_SigId" SG_ 2566861351 MinBatSysTemp 1519;
BA_ "CI_ParId" SG_ 2566861351 MinBatSysTemp "IB191";
BA_ "SigType" SG_ 2566861351 MaxBatSysTemp 1;
BA_ "GenSigTimeoutTime_VMU" SG_ 2566861351 MaxBatSysTemp 5000;
BA_ "GenSigTimeoutTime_VCU" SG_ 2566861351 MaxBatSysTemp 5000;
BA_ "GenSigStartValue" SG_ 2566861351 MaxBatSysTemp 40;
BA_ "CI_SigName" SG_ 2566861351 MaxBatSysTemp "Maximum Battery System Temperature";
BA_ "CI_SigId" SG_ 2566861351 MaxBatSysTemp 1518;
BA_ "CI_ParId" SG_ 2566861351 MaxBatSysTemp "IB190";
BA_ "SigType" SG_ 2566861555 BatSysDeltaCellV 1;
BA_ "GenSigTimeoutTime_SGW" SG_ 2566861555 BatSysDeltaCellV 25000;
BA_ "GenSigTimeoutTime_PCM" SG_ 2566861555 BatSysDeltaCellV 25000;
BA_ "GenSigTimeoutTime_MPPxPTFE2" SG_ 2566861555 BatSysDeltaCellV 25000;
BA_ "GenSigTimeoutTime_IC_MulticS" SG_ 2566861555 BatSysDeltaCellV 25000;
BA_ "GenSigTimeoutTime_FMS_FMS4" SG_ 2566861555 BatSysDeltaCellV 25000;
BA_ "CI_SigName" SG_ 2566861555 BatSysDeltaCellV "Battery System Delta Cell Voltage";
BA_ "CI_SigId" SG_ 2566861555 BatSysDeltaCellV 1515;
BA_ "CI_ParId" SG_ 2566861555 BatSysDeltaCellV "IB196";
BA_ "SigType" SG_ 2566861555 BatWaterFlowRateReq 1;
BA_ "GenSigTimeoutTime_SGW" SG_ 2566861555 BatWaterFlowRateReq 25000;
BA_ "GenSigTimeoutTime_PCM" SG_ 2566861555 BatWaterFlowRateReq 25000;
BA_ "GenSigTimeoutTime_MPPxPTFE2" SG_ 2566861555 BatWaterFlowRateReq 25000;
BA_ "GenSigTimeoutTime_IC_MulticS" SG_ 2566861555 BatWaterFlowRateReq 25000;
BA_ "GenSigTimeoutTime_FMS_FMS4" SG_ 2566861555 BatWaterFlowRateReq 25000;
BA_ "CI_SigName" SG_ 2566861555 BatWaterFlowRateReq "Battery Water Flow Rate Request";
BA_ "CI_SigId" SG_ 2566861555 BatWaterFlowRateReq 1514;
BA_ "CI_ParId" SG_ 2566861555 BatWaterFlowRateReq "IB195";
BA_ "SigType" SG_ 2566861555 BatOutWaterTempReq 1;
BA_ "GenSigTimeoutTime_SGW" SG_ 2566861555 BatOutWaterTempReq 25000;
BA_ "GenSigTimeoutTime_PCM" SG_ 2566861555 BatOutWaterTempReq 25000;
BA_ "GenSigTimeoutTime_MPPxPTFE2" SG_ 2566861555 BatOutWaterTempReq 25000;
BA_ "GenSigTimeoutTime_IC_MulticS" SG_ 2566861555 BatOutWaterTempReq 25000;
BA_ "GenSigTimeoutTime_FMS_FMS4" SG_ 2566861555 BatOutWaterTempReq 25000;
BA_ "GenSigStartValue" SG_ 2566861555 BatOutWaterTempReq 40;
BA_ "CI_SigName" SG_ 2566861555 BatOutWaterTempReq "Battery Outlet Water Temperature Request";
BA_ "CI_SigId" SG_ 2566861555 BatOutWaterTempReq 1513;
BA_ "CI_ParId" SG_ 2566861555 BatOutWaterTempReq "IB194";
BA_ "SigType" SG_ 2566861555 PacksOnLine 1;
BA_ "GenSigTimeoutTime_SGW" SG_ 2566861555 PacksOnLine 25000;
BA_ "GenSigTimeoutTime_PCM" SG_ 2566861555 PacksOnLine 25000;
BA_ "GenSigTimeoutTime_MPPxPTFE2" SG_ 2566861555 PacksOnLine 25000;
BA_ "GenSigTimeoutTime_IC_MulticS" SG_ 2566861555 PacksOnLine 25000;
BA_ "GenSigTimeoutTime_FMS_FMS4" SG_ 2566861555 PacksOnLine 25000;
BA_ "CI_SigName" SG_ 2566861555 PacksOnLine "Packs on Line";
BA_ "CI_SigId" SG_ 2566861555 PacksOnLine 1512;
BA_ "CI_ParId" SG_ 2566861555 PacksOnLine "IB193";
BA_ "SigType" SG_ 2566861555 ActBatSysSoc_FF32F3 1;
BA_ "GenSigTimeoutTime_SGW" SG_ 2566861555 ActBatSysSoc_FF32F3 25000;
BA_ "GenSigTimeoutTime_PCM" SG_ 2566861555 ActBatSysSoc_FF32F3 25000;
BA_ "GenSigTimeoutTime_MPPxPTFE2" SG_ 2566861555 ActBatSysSoc_FF32F3 25000;
BA_ "GenSigTimeoutTime_IC_MulticS" SG_ 2566861555 ActBatSysSoc_FF32F3 25000;
BA_ "GenSigTimeoutTime_FMS_FMS4" SG_ 2566861555 ActBatSysSoc_FF32F3 25000;
BA_ "CI_SigName" SG_ 2566861555 ActBatSysSoc_FF32F3 "Actual Battery System State Of Charge";
BA_ "CI_SigId" SG_ 2566861555 ActBatSysSoc_FF32F3 1511;
BA_ "CI_ParId" SG_ 2566861555 ActBatSysSoc_FF32F3 "IB192";
BA_ "SigType" SG_ 2566861555 MinBatSysTemp_FF32F3 1;
BA_ "GenSigTimeoutTime_SGW" SG_ 2566861555 MinBatSysTemp_FF32F3 25000;
BA_ "GenSigTimeoutTime_PCM" SG_ 2566861555 MinBatSysTemp_FF32F3 25000;
BA_ "GenSigTimeoutTime_MPPxPTFE2" SG_ 2566861555 MinBatSysTemp_FF32F3 25000;
BA_ "GenSigTimeoutTime_IC_MulticS" SG_ 2566861555 MinBatSysTemp_FF32F3 25000;
BA_ "GenSigTimeoutTime_FMS_FMS4" SG_ 2566861555 MinBatSysTemp_FF32F3 25000;
BA_ "GenSigTimeoutTime_BCM_NBM" SG_ 2566861555 MinBatSysTemp_FF32F3 25000;
BA_ "GenSigStartValue" SG_ 2566861555 MinBatSysTemp_FF32F3 40;
BA_ "CI_SigName" SG_ 2566861555 MinBatSysTemp_FF32F3 "Minimum Battery System Temperature";
BA_ "CI_SigId" SG_ 2566861555 MinBatSysTemp_FF32F3 1510;
BA_ "CI_ParId" SG_ 2566861555 MinBatSysTemp_FF32F3 "IB191";
BA_ "SigType" SG_ 2566861555 MaxBatSysTemp_FF32F3 1;
BA_ "GenSigTimeoutTime_SGW" SG_ 2566861555 MaxBatSysTemp_FF32F3 25000;
BA_ "GenSigTimeoutTime_PCM" SG_ 2566861555 MaxBatSysTemp_FF32F3 25000;
BA_ "GenSigTimeoutTime_MPPxPTFE2" SG_ 2566861555 MaxBatSysTemp_FF32F3 25000;
BA_ "GenSigTimeoutTime_IC_MulticS" SG_ 2566861555 MaxBatSysTemp_FF32F3 25000;
BA_ "GenSigTimeoutTime_FMS_FMS4" SG_ 2566861555 MaxBatSysTemp_FF32F3 25000;
BA_ "GenSigTimeoutTime_BCM_NBM" SG_ 2566861555 MaxBatSysTemp_FF32F3 25000;
BA_ "GenSigStartValue" SG_ 2566861555 MaxBatSysTemp_FF32F3 40;
BA_ "CI_SigName" SG_ 2566861555 MaxBatSysTemp_FF32F3 "Maximum Battery System Temperature";
BA_ "CI_SigId" SG_ 2566861555 MaxBatSysTemp_FF32F3 1509;
BA_ "CI_ParId" SG_ 2566861555 MaxBatSysTemp_FF32F3 "IB190";
BA_ "SigType" SG_ 2566861555 MinSysV 1;
BA_ "GenSigTimeoutTime_SGW" SG_ 2566861555 MinSysV 25000;
BA_ "GenSigTimeoutTime_PCM" SG_ 2566861555 MinSysV 25000;
BA_ "GenSigTimeoutTime_MPPxPTFE2" SG_ 2566861555 MinSysV 25000;
BA_ "GenSigTimeoutTime_IC_MulticS" SG_ 2566861555 MinSysV 25000;
BA_ "GenSigTimeoutTime_FMS_FMS4" SG_ 2566861555 MinSysV 25000;
BA_ "CI_SigName" SG_ 2566861555 MinSysV "Minimum System Voltage";
BA_ "CI_SigId" SG_ 2566861555 MinSysV 1508;
BA_ "CI_ParId" SG_ 2566861555 MinSysV "IB189";
BA_ "GenSigTimeoutTime_PCM" SG_ 2365554927 CrcIb 500;
BA_ "CI_SigName" SG_ 2365554927 CrcIb "CRC_IB";
BA_ "CI_SigId" SG_ 2365554927 CrcIb 1412;
BA_ "CI_ParId" SG_ 2365554927 CrcIb "IB1093";
BA_ "GenSigTimeoutTime_PCM" SG_ 2365554927 MsgCntIb 500;
BA_ "CI_SigName" SG_ 2365554927 MsgCntIb "Message Counter_IB";
BA_ "CI_SigId" SG_ 2365554927 MsgCntIb 1411;
BA_ "CI_ParId" SG_ 2365554927 MsgCntIb "IB652";
BA_ "SigType" SG_ 2365554927 ActMaxavmotnegpercenttq 1;
BA_ "GenSigTimeoutTime_SGW" SG_ 2365554927 ActMaxavmotnegpercenttq 500;
BA_ "GenSigTimeoutTime_PCM" SG_ 2365554927 ActMaxavmotnegpercenttq 500;
BA_ "GenSigStartValue" SG_ 2365554927 ActMaxavmotnegpercenttq 125;
BA_ "CI_SigName" SG_ 2365554927 ActMaxavmotnegpercenttq "Actual MaxAvMotNegPercentTq";
BA_ "CI_SigId" SG_ 2365554927 ActMaxavmotnegpercenttq 1410;
BA_ "CI_ParId" SG_ 2365554927 ActMaxavmotnegpercenttq "IB131";
BA_ "SigType" SG_ 2365554927 ActMaxavmotpospercenttq 1;
BA_ "GenSigTimeoutTime_SGW" SG_ 2365554927 ActMaxavmotpospercenttq 500;
BA_ "GenSigTimeoutTime_PCM" SG_ 2365554927 ActMaxavmotpospercenttq 500;
BA_ "GenSigStartValue" SG_ 2365554927 ActMaxavmotpospercenttq 125;
BA_ "CI_SigName" SG_ 2365554927 ActMaxavmotpospercenttq "Actual MaxAvMotPosPercentTq";
BA_ "CI_SigId" SG_ 2365554927 ActMaxavmotpospercenttq 1409;
BA_ "CI_ParId" SG_ 2365554927 ActMaxavmotpospercenttq "IB130";
BA_ "SigType" SG_ 2365554927 ActMotSpeed 1;
BA_ "GenSigTimeoutTime_VMU" SG_ 2365554927 ActMotSpeed 500;
BA_ "GenSigTimeoutTime_VCU" SG_ 2365554927 ActMotSpeed 500;
BA_ "GenSigTimeoutTime_SGW" SG_ 2365554927 ActMotSpeed 500;
BA_ "GenSigTimeoutTime_PCM" SG_ 2365554927 ActMotSpeed 500;
BA_ "GenSigStartValue" SG_ 2365554927 ActMotSpeed 32127;
BA_ "CI_SigName" SG_ 2365554927 ActMotSpeed "Actual Motor Speed";
BA_ "CI_SigId" SG_ 2365554927 ActMotSpeed 1408;
BA_ "CI_ParId" SG_ 2365554927 ActMotSpeed "IB129";
BA_ "SigType" SG_ 2365554927 ActMotPcTrq 1;
BA_ "GenSigTimeoutTime_VMU" SG_ 2365554927 ActMotPcTrq 500;
BA_ "GenSigTimeoutTime_VCU" SG_ 2365554927 ActMotPcTrq 500;
BA_ "GenSigTimeoutTime_SGW" SG_ 2365554927 ActMotPcTrq 500;
BA_ "GenSigTimeoutTime_PCM" SG_ 2365554927 ActMotPcTrq 500;
BA_ "GenSigStartValue" SG_ 2365554927 ActMotPcTrq 125;
BA_ "CI_SigName" SG_ 2365554927 ActMotPcTrq "Actual Motor Percent Torque";
BA_ "CI_SigId" SG_ 2365554927 ActMotPcTrq 1407;
BA_ "CI_ParId" SG_ 2365554927 ActMotPcTrq "IB128";
BA_ "SigType" SG_ 2566878241 InterSansSecu_DrivWithH2HatchOp 4;
BA_ "GenSigTimeoutTime_VMU" SG_ 2566878241 InterSansSecu_DrivWithH2HatchOp 500;
BA_ "GenSigTimeoutTime_SGW" SG_ 2566878241 InterSansSecu_DrivWithH2HatchOp 500;
BA_ "GenSigTimeoutTime_PCM" SG_ 2566878241 InterSansSecu_DrivWithH2HatchOp 500;
BA_ "CI_SigName" SG_ 2566878241 InterSansSecu_DrivWithH2HatchOp "InterSansSecu_Switch WO any security from driver to allow driving with H2 hatch open";
BA_ "CI_SigId" SG_ 2566878241 InterSansSecu_DrivWithH2HatchOp 18962;
BA_ "CI_ParId" SG_ 2566878241 InterSansSecu_DrivWithH2HatchOp "IB4055";
BA_ "SigType" SG_ 2566878241 FC_CoolGroupLevTooLow 4;
BA_ "GenSigTimeoutTime_VMU" SG_ 2566878241 FC_CoolGroupLevTooLow 500;
BA_ "GenSigTimeoutTime_SGW" SG_ 2566878241 FC_CoolGroupLevTooLow 500;
BA_ "GenSigTimeoutTime_PCM" SG_ 2566878241 FC_CoolGroupLevTooLow 500;
BA_ "CI_SigName" SG_ 2566878241 FC_CoolGroupLevTooLow "FC cooling group level too low";
BA_ "CI_SigId" SG_ 2566878241 FC_CoolGroupLevTooLow 18961;
BA_ "CI_ParId" SG_ 2566878241 FC_CoolGroupLevTooLow "IB4054";
BA_ "SigType" SG_ 2566878241 LimpHomeFC_Mode_OvReq 4;
BA_ "GenSigTimeoutTime_VMU" SG_ 2566878241 LimpHomeFC_Mode_OvReq 500;
BA_ "GenSigTimeoutTime_SGW" SG_ 2566878241 LimpHomeFC_Mode_OvReq 500;
BA_ "GenSigTimeoutTime_PCM" SG_ 2566878241 LimpHomeFC_Mode_OvReq 500;
BA_ "CI_SigName" SG_ 2566878241 LimpHomeFC_Mode_OvReq "LimpHomeFCMode_OverrideModeReqByDriver";
BA_ "CI_SigId" SG_ 2566878241 LimpHomeFC_Mode_OvReq 18960;
BA_ "CI_ParId" SG_ 2566878241 LimpHomeFC_Mode_OvReq "IB4053";
BA_ "SigType" SG_ 2566878241 Fill_AuthorizFromVehSide 4;
BA_ "GenSigTimeoutTime_VMU" SG_ 2566878241 Fill_AuthorizFromVehSide 500;
BA_ "GenSigTimeoutTime_SGW" SG_ 2566878241 Fill_AuthorizFromVehSide 500;
BA_ "GenSigTimeoutTime_PCM" SG_ 2566878241 Fill_AuthorizFromVehSide 500;
BA_ "CI_SigName" SG_ 2566878241 Fill_AuthorizFromVehSide "Filling authorization from vehicle side";
BA_ "CI_SigId" SG_ 2566878241 Fill_AuthorizFromVehSide 18959;
BA_ "CI_ParId" SG_ 2566878241 Fill_AuthorizFromVehSide "IB4052";
BA_ "SigType" SG_ 2566878241 Authoriz_FC_ActivByVehCond 4;
BA_ "GenSigTimeoutTime_VMU" SG_ 2566878241 Authoriz_FC_ActivByVehCond 500;
BA_ "GenSigTimeoutTime_SGW" SG_ 2566878241 Authoriz_FC_ActivByVehCond 500;
BA_ "GenSigTimeoutTime_PCM" SG_ 2566878241 Authoriz_FC_ActivByVehCond 500;
BA_ "CI_SigName" SG_ 2566878241 Authoriz_FC_ActivByVehCond "Authorization FC activation by vehicle conditions";
BA_ "CI_SigId" SG_ 2566878241 Authoriz_FC_ActivByVehCond 18958;
BA_ "CI_ParId" SG_ 2566878241 Authoriz_FC_ActivByVehCond "IB4051";
BA_ "SigType" SG_ 2566776097 AppliedVsl 1;
BA_ "SPN" SG_ 2566776097 AppliedVsl 2595;
BA_ "GenSigTimeoutTime_SGW" SG_ 2566776097 AppliedVsl 5000;
BA_ "GenSigTimeoutTime_PCM" SG_ 2566776097 AppliedVsl 5000;
BA_ "CI_SigName" SG_ 2566776097 AppliedVsl "Applied Vehicle Speed Limit";
BA_ "CI_SigId" SG_ 2566776097 AppliedVsl 2177;
BA_ "CI_ParId" SG_ 2566776097 AppliedVsl "2595";
BA_ "SigType" SG_ 2566776097 MaxVsl1 1;
BA_ "SPN" SG_ 2566776097 MaxVsl1 2588;
BA_ "GenSigTimeoutTime_VMU" SG_ 2566776097 MaxVsl1 5000;
BA_ "GenSigTimeoutTime_VCU" SG_ 2566776097 MaxVsl1 5000;
BA_ "GenSigTimeoutTime_SGW" SG_ 2566776097 MaxVsl1 5000;
BA_ "GenSigTimeoutTime_PCM" SG_ 2566776097 MaxVsl1 5000;
BA_ "CI_SigName" SG_ 2566776097 MaxVsl1 "Maximum Vehicle Speed Limit 1";
BA_ "CI_SigId" SG_ 2566776097 MaxVsl1 2176;
BA_ "CI_ParId" SG_ 2566776097 MaxVsl1 "2588";
BA_ "SPN" SG_ 2365443105 TurnSigSw 2876;
BA_ "GenSigTimeoutTime_SGW" SG_ 2365443105 TurnSigSw 1250;
BA_ "GenSigTimeoutTime_PCM" SG_ 2365443105 TurnSigSw 1250;
BA_ "GenSigTimeoutTime_MPPxPTFE2" SG_ 2365443105 TurnSigSw 1250;
BA_ "GenSigTimeoutTime_FMS_FMS5" SG_ 2365443105 TurnSigSw 1250;
BA_ "GenSigTimeoutTime_ADCU" SG_ 2365443105 TurnSigSw 1250;
BA_ "CI_SigName" SG_ 2365443105 TurnSigSw "Turn Signal Switch";
BA_ "CI_SigId" SG_ 2365443105 TurnSigSw 2629;
BA_ "CI_ParId" SG_ 2365443105 TurnSigSw "2876";
BA_ "SPN" SG_ 2566769953 FrontOpWasherSw 2866;
BA_ "GenSigTimeoutTime_SGW" SG_ 2566769953 FrontOpWasherSw 5000;
BA_ "GenSigTimeoutTime_PCM" SG_ 2566769953 FrontOpWasherSw 5000;
BA_ "GenSigTimeoutTime_MPPxPTFE2" SG_ 2566769953 FrontOpWasherSw 5000;
BA_ "GenSigTimeoutTime_FMS_FMS5" SG_ 2566769953 FrontOpWasherSw 5000;
BA_ "GenSigTimeoutTime_ADCU" SG_ 2566769953 FrontOpWasherSw 5000;
BA_ "GenSigSendType" SG_ 2566769953 FrontOpWasherSw 3;
BA_ "CI_SigName" SG_ 2566769953 FrontOpWasherSw "Front Operator Washer Switch";
BA_ "CI_SigId" SG_ 2566769953 FrontOpWasherSw 2642;
BA_ "CI_ParId" SG_ 2566769953 FrontOpWasherSw "2866";
BA_ "SPN" SG_ 2566769953 FrontOpWiperSw 2863;
BA_ "GenSigTimeoutTime_SGW" SG_ 2566769953 FrontOpWiperSw 5000;
BA_ "GenSigTimeoutTime_PCM" SG_ 2566769953 FrontOpWiperSw 5000;
BA_ "GenSigTimeoutTime_MPPxPTFE2" SG_ 2566769953 FrontOpWiperSw 5000;
BA_ "GenSigTimeoutTime_FMS_FMS5" SG_ 2566769953 FrontOpWiperSw 5000;
BA_ "GenSigTimeoutTime_ADCU" SG_ 2566769953 FrontOpWiperSw 5000;
BA_ "GenSigSendType" SG_ 2566769953 FrontOpWiperSw 3;
BA_ "CI_SigName" SG_ 2566769953 FrontOpWiperSw "Front Operator Wiper Switch";
BA_ "CI_SigId" SG_ 2566769953 FrontOpWiperSw 2636;
BA_ "CI_ParId" SG_ 2566769953 FrontOpWiperSw "2863";
BA_ "SigType" SG_ 2633959399 StopLamp 4;
BA_ "GenSigTimeoutTime_SGW" SG_ 2633959399 StopLamp 500;
BA_ "GenSigTimeoutTime_PCM" SG_ 2633959399 StopLamp 500;
BA_ "GenSigTimeoutTime_MPPxPTFE2" SG_ 2633959399 StopLamp 500;
BA_ "GenSigTimeoutTime_IC_MulticII" SG_ 2633959399 StopLamp 500;
BA_ "GenSigTimeoutTime_FMS_FMS5" SG_ 2633959399 StopLamp 500;
BA_ "GenSigTimeoutTime_FMS_FMS4" SG_ 2633959399 StopLamp 500;
BA_ "GenSigTimeoutTime_BCM_NBM" SG_ 2633959399 StopLamp 500;
BA_ "CI_SigName" SG_ 2633959399 StopLamp "ACU_Stop Lamp";
BA_ "CI_SigId" SG_ 2633959399 StopLamp 12752;
BA_ "CI_ParId" SG_ 2633959399 StopLamp "IB839";
BA_ "SigType" SG_ 2633959399 FunctLamp 4;
BA_ "GenSigTimeoutTime_SGW" SG_ 2633959399 FunctLamp 500;
BA_ "GenSigTimeoutTime_PCM" SG_ 2633959399 FunctLamp 500;
BA_ "GenSigTimeoutTime_MPPxPTFE2" SG_ 2633959399 FunctLamp 500;
BA_ "GenSigTimeoutTime_IC_MulticII" SG_ 2633959399 FunctLamp 500;
BA_ "GenSigTimeoutTime_FMS_FMS5" SG_ 2633959399 FunctLamp 500;
BA_ "GenSigTimeoutTime_FMS_FMS4" SG_ 2633959399 FunctLamp 500;
BA_ "GenSigTimeoutTime_BCM_NBM" SG_ 2633959399 FunctLamp 500;
BA_ "CI_SigName" SG_ 2633959399 FunctLamp "ACU_Function Lamp";
BA_ "CI_SigId" SG_ 2633959399 FunctLamp 12751;
BA_ "CI_ParId" SG_ 2633959399 FunctLamp "IB838";
BA_ "SigType" SG_ 2566850535 StopLamp_FF07E7 4;
BA_ "GenSigTimeoutTime_SGW" SG_ 2566850535 StopLamp_FF07E7 500;
BA_ "GenSigTimeoutTime_PCM" SG_ 2566850535 StopLamp_FF07E7 500;
BA_ "GenSigTimeoutTime_MPPxPTFE2" SG_ 2566850535 StopLamp_FF07E7 500;
BA_ "GenSigTimeoutTime_IC_MulticII" SG_ 2566850535 StopLamp_FF07E7 500;
BA_ "GenSigTimeoutTime_FMS_FMS5" SG_ 2566850535 StopLamp_FF07E7 500;
BA_ "GenSigTimeoutTime_FMS_FMS4" SG_ 2566850535 StopLamp_FF07E7 500;
BA_ "GenSigTimeoutTime_BCM_NBM" SG_ 2566850535 StopLamp_FF07E7 500;
BA_ "CI_SigName" SG_ 2566850535 StopLamp_FF07E7 "ACU_Stop Lamp";
BA_ "CI_SigId" SG_ 2566850535 StopLamp_FF07E7 12743;
BA_ "CI_ParId" SG_ 2566850535 StopLamp_FF07E7 "IB839";
BA_ "SigType" SG_ 2566850535 FunctLamp_FF07E7 4;
BA_ "GenSigTimeoutTime_SGW" SG_ 2566850535 FunctLamp_FF07E7 500;
BA_ "GenSigTimeoutTime_PCM" SG_ 2566850535 FunctLamp_FF07E7 500;
BA_ "GenSigTimeoutTime_MPPxPTFE2" SG_ 2566850535 FunctLamp_FF07E7 500;
BA_ "GenSigTimeoutTime_IC_MulticII" SG_ 2566850535 FunctLamp_FF07E7 500;
BA_ "GenSigTimeoutTime_FMS_FMS5" SG_ 2566850535 FunctLamp_FF07E7 500;
BA_ "GenSigTimeoutTime_FMS_FMS4" SG_ 2566850535 FunctLamp_FF07E7 500;
BA_ "GenSigTimeoutTime_BCM_NBM" SG_ 2566850535 FunctLamp_FF07E7 500;
BA_ "CI_SigName" SG_ 2566850535 FunctLamp_FF07E7 "ACU_Function Lamp";
BA_ "CI_SigId" SG_ 2566850535 FunctLamp_FF07E7 12742;
BA_ "CI_ParId" SG_ 2566850535 FunctLamp_FF07E7 "IB838";
BA_ "GenSigTimeoutTime_SGW" SG_ 2566908574 DdawRunMode 1000;
BA_ "GenSigTimeoutTime_PCM" SG_ 2566908574 DdawRunMode 1000;
BA_ "GenSigTimeoutTime_IC_MulticS" SG_ 2566908574 DdawRunMode 1000;
BA_ "GenSigTimeoutTime_IC_MulticII" SG_ 2566908574 DdawRunMode 1000;
BA_ "GenSigTimeoutTime_BCM_NBM" SG_ 2566908574 DdawRunMode 1000;
BA_ "CI_SigName" SG_ 2566908574 DdawRunMode "DDAW Running Mode";
BA_ "CI_SigId" SG_ 2566908574 DdawRunMode 629;
BA_ "CI_ParId" SG_ 2566908574 DdawRunMode "IMH0104";
BA_ "GenSigTimeoutTime_SGW" SG_ 2566908574 DrowsDrivLev 1000;
BA_ "GenSigTimeoutTime_PCM" SG_ 2566908574 DrowsDrivLev 1000;
BA_ "GenSigTimeoutTime_IC_MulticS" SG_ 2566908574 DrowsDrivLev 1000;
BA_ "GenSigTimeoutTime_IC_MulticII" SG_ 2566908574 DrowsDrivLev 1000;
BA_ "CI_SigName" SG_ 2566908574 DrowsDrivLev "Drowsiness Driver Level";
BA_ "CI_SigId" SG_ 2566908574 DrowsDrivLev 628;
BA_ "CI_ParId" SG_ 2566908574 DrowsDrivLev "IS939";
BA_ "SigType" SG_ 2583638515 TotEnergyTput 1;
BA_ "GenSigTimeoutTime_VMU" SG_ 2583638515 TotEnergyTput 7500;
BA_ "GenSigTimeoutTime_SGW2" SG_ 2583638515 TotEnergyTput 7500;
BA_ "GenSigTimeoutTime_SGW" SG_ 2583638515 TotEnergyTput 7500;
BA_ "GenSigTimeoutTime_PCM" SG_ 2583638515 TotEnergyTput 7500;
BA_ "CI_SigName" SG_ 2583638515 TotEnergyTput "Total Energy Throughput";
BA_ "CI_SigId" SG_ 2583638515 TotEnergyTput 21479;
BA_ "CI_ParId" SG_ 2583638515 TotEnergyTput "MV0011";
BA_ "SigType" SG_ 2583638515 Soh 1;
BA_ "GenSigTimeoutTime_VMU" SG_ 2583638515 Soh 7500;
BA_ "GenSigTimeoutTime_SGW2" SG_ 2583638515 Soh 7500;
BA_ "GenSigTimeoutTime_SGW" SG_ 2583638515 Soh 7500;
BA_ "GenSigTimeoutTime_PCM" SG_ 2583638515 Soh 7500;
BA_ "CI_SigName" SG_ 2583638515 Soh "State of Health";
BA_ "CI_SigId" SG_ 2583638515 Soh 21478;
BA_ "CI_ParId" SG_ 2583638515 Soh "MV0010";
BA_ "GenSigTimeoutTime_VMU" SG_ 2583638515 AsrProf2Cnt 7500;
BA_ "GenSigTimeoutTime_SGW2" SG_ 2583638515 AsrProf2Cnt 7500;
BA_ "GenSigTimeoutTime_SGW" SG_ 2583638515 AsrProf2Cnt 7500;
BA_ "GenSigTimeoutTime_PCM" SG_ 2583638515 AsrProf2Cnt 7500;
BA_ "CI_SigName" SG_ 2583638515 AsrProf2Cnt "Autosar Profile 2 Counter";
BA_ "CI_SigId" SG_ 2583638515 AsrProf2Cnt 21477;
BA_ "CI_ParId" SG_ 2583638515 AsrProf2Cnt "IMH0066";
BA_ "GenSigTimeoutTime_VMU" SG_ 2583638515 AsrProf2Crc 7500;
BA_ "GenSigTimeoutTime_SGW2" SG_ 2583638515 AsrProf2Crc 7500;
BA_ "GenSigTimeoutTime_SGW" SG_ 2583638515 AsrProf2Crc 7500;
BA_ "GenSigTimeoutTime_PCM" SG_ 2583638515 AsrProf2Crc 7500;
BA_ "CI_SigName" SG_ 2583638515 AsrProf2Crc "Autosar Profile 2 CRC";
BA_ "CI_SigId" SG_ 2583638515 AsrProf2Crc 21476;
BA_ "CI_ParId" SG_ 2583638515 AsrProf2Crc "IMH0067";
BA_ "SPN" SG_ 2566907159 MsgCks 4207;
BA_ "GenSigTimeoutTime_SGW" SG_ 2566907159 MsgCks 500;
BA_ "GenSigTimeoutTime_PCM" SG_ 2566907159 MsgCks 500;
BA_ "GenSigTimeoutTime_ADCU" SG_ 2566907159 MsgCks 500;
BA_ "GenSigSendType" SG_ 2566907159 MsgCks 3;
BA_ "CI_SigName" SG_ 2566907159 MsgCks "Message Checksum";
BA_ "CI_SigId" SG_ 2566907159 MsgCks 4031;
BA_ "CI_ParId" SG_ 2566907159 MsgCks "4207";
BA_ "SPN" SG_ 2566907159 MsgCnt 4206;
BA_ "GenSigTimeoutTime_SGW" SG_ 2566907159 MsgCnt 500;
BA_ "GenSigTimeoutTime_PCM" SG_ 2566907159 MsgCnt 500;
BA_ "GenSigTimeoutTime_ADCU" SG_ 2566907159 MsgCnt 500;
BA_ "GenSigSendType" SG_ 2566907159 MsgCnt 3;
BA_ "CI_SigName" SG_ 2566907159 MsgCnt "Message Counter";
BA_ "CI_SigId" SG_ 2566907159 MsgCnt 4030;
BA_ "CI_ParId" SG_ 2566907159 MsgCnt "4206";
BA_ "SigType" SG_ 2566907159 LdwsCsfPreSel 4;
BA_ "GenSigTimeoutTime_VCM" SG_ 2566907159 LdwsCsfPreSel 500;
BA_ "GenSigTimeoutTime_SGW" SG_ 2566907159 LdwsCsfPreSel 500;
BA_ "GenSigTimeoutTime_PCM" SG_ 2566907159 LdwsCsfPreSel 500;
BA_ "GenSigTimeoutTime_BCM_NBM" SG_ 2566907159 LdwsCsfPreSel 500;
BA_ "GenSigTimeoutTime_ADCU" SG_ 2566907159 LdwsCsfPreSel 500;
BA_ "GenSigSendType" SG_ 2566907159 LdwsCsfPreSel 3;
BA_ "CI_SigName" SG_ 2566907159 LdwsCsfPreSel "LDWS CSF Pre-selection";
BA_ "CI_SigId" SG_ 2566907159 LdwsCsfPreSel 14751;
BA_ "CI_ParId" SG_ 2566907159 LdwsCsfPreSel "IMH0218";
BA_ "SigType" SG_ 2566907159 RightVibratorFail 4;
BA_ "GenSigTimeoutTime_SGW" SG_ 2566907159 RightVibratorFail 500;
BA_ "GenSigTimeoutTime_PCM" SG_ 2566907159 RightVibratorFail 500;
BA_ "GenSigTimeoutTime_BCM_NBM" SG_ 2566907159 RightVibratorFail 500;
BA_ "GenSigTimeoutTime_ADCU" SG_ 2566907159 RightVibratorFail 500;
BA_ "GenSigSendType" SG_ 2566907159 RightVibratorFail 3;
BA_ "CI_SigName" SG_ 2566907159 RightVibratorFail "Right Vibrator Failure";
BA_ "CI_SigId" SG_ 2566907159 RightVibratorFail 4029;
BA_ "CI_ParId" SG_ 2566907159 RightVibratorFail "IMH0188";
BA_ "SigType" SG_ 2566907159 LeftVibratorFail 4;
BA_ "GenSigTimeoutTime_SGW" SG_ 2566907159 LeftVibratorFail 500;
BA_ "GenSigTimeoutTime_PCM" SG_ 2566907159 LeftVibratorFail 500;
BA_ "GenSigTimeoutTime_BCM_NBM" SG_ 2566907159 LeftVibratorFail 500;
BA_ "GenSigTimeoutTime_ADCU" SG_ 2566907159 LeftVibratorFail 500;
BA_ "GenSigSendType" SG_ 2566907159 LeftVibratorFail 3;
BA_ "CI_SigName" SG_ 2566907159 LeftVibratorFail "Left Vibrator Failure";
BA_ "CI_SigId" SG_ 2566907159 LeftVibratorFail 4028;
BA_ "CI_ParId" SG_ 2566907159 LeftVibratorFail "IMH0187";
BA_ "SigType" SG_ 2566907159 BsisFuncEn 4;
BA_ "GenSigTimeoutTime_SGW" SG_ 2566907159 BsisFuncEn 500;
BA_ "GenSigTimeoutTime_PCM" SG_ 2566907159 BsisFuncEn 500;
BA_ "GenSigTimeoutTime_ADCU" SG_ 2566907159 BsisFuncEn 500;
BA_ "GenSigSendType" SG_ 2566907159 BsisFuncEn 3;
BA_ "CI_SigName" SG_ 2566907159 BsisFuncEn "Blind Spot Information System Function Enable";
BA_ "CI_SigId" SG_ 2566907159 BsisFuncEn 4027;
BA_ "CI_ParId" SG_ 2566907159 BsisFuncEn "IMH0180";
BA_ "SigType" SG_ 2566907159 PlcaWarnEn 4;
BA_ "GenSigTimeoutTime_SGW" SG_ 2566907159 PlcaWarnEn 500;
BA_ "GenSigTimeoutTime_PCM" SG_ 2566907159 PlcaWarnEn 500;
BA_ "GenSigTimeoutTime_ADCU" SG_ 2566907159 PlcaWarnEn 500;
BA_ "GenSigSendType" SG_ 2566907159 PlcaWarnEn 3;
BA_ "CI_SigName" SG_ 2566907159 PlcaWarnEn "Passive Lane Change Assist Warning Enable";
BA_ "CI_SigId" SG_ 2566907159 PlcaWarnEn 4026;
BA_ "CI_ParId" SG_ 2566907159 PlcaWarnEn "IMH0178";
BA_ "SigType" SG_ 2566907159 PlcaFuncEn 4;
BA_ "GenSigTimeoutTime_SGW" SG_ 2566907159 PlcaFuncEn 500;
BA_ "GenSigTimeoutTime_PCM" SG_ 2566907159 PlcaFuncEn 500;
BA_ "GenSigTimeoutTime_ADCU" SG_ 2566907159 PlcaFuncEn 500;
BA_ "GenSigSendType" SG_ 2566907159 PlcaFuncEn 3;
BA_ "CI_SigName" SG_ 2566907159 PlcaFuncEn "Passive Lane Change Assist Function Enable";
BA_ "CI_SigId" SG_ 2566907159 PlcaFuncEn 4025;
BA_ "CI_ParId" SG_ 2566907159 PlcaFuncEn "IMH0179";
BA_ "SigType" SG_ 2566907159 RightLedbarFail 4;
BA_ "GenSigTimeoutTime_SGW" SG_ 2566907159 RightLedbarFail 500;
BA_ "GenSigTimeoutTime_PCM" SG_ 2566907159 RightLedbarFail 500;
BA_ "GenSigTimeoutTime_ADCU" SG_ 2566907159 RightLedbarFail 500;
BA_ "GenSigSendType" SG_ 2566907159 RightLedbarFail 3;
BA_ "CI_SigName" SG_ 2566907159 RightLedbarFail "Right Ledbar Failure";
BA_ "CI_SigId" SG_ 2566907159 RightLedbarFail 4024;
BA_ "CI_ParId" SG_ 2566907159 RightLedbarFail "IMH0175";
BA_ "SigType" SG_ 2566907159 LeftLedbarFail 4;
BA_ "GenSigTimeoutTime_SGW" SG_ 2566907159 LeftLedbarFail 500;
BA_ "GenSigTimeoutTime_PCM" SG_ 2566907159 LeftLedbarFail 500;
BA_ "GenSigTimeoutTime_ADCU" SG_ 2566907159 LeftLedbarFail 500;
BA_ "GenSigSendType" SG_ 2566907159 LeftLedbarFail 3;
BA_ "CI_SigName" SG_ 2566907159 LeftLedbarFail "Left Ledbar Failure";
BA_ "CI_SigId" SG_ 2566907159 LeftLedbarFail 4023;
BA_ "CI_ParId" SG_ 2566907159 LeftLedbarFail "IMH0174";
BA_ "SigType" SG_ 2566907159 BuzFail 4;
BA_ "GenSigTimeoutTime_SGW" SG_ 2566907159 BuzFail 500;
BA_ "GenSigTimeoutTime_PCM" SG_ 2566907159 BuzFail 500;
BA_ "GenSigTimeoutTime_ADCU" SG_ 2566907159 BuzFail 500;
BA_ "GenSigSendType" SG_ 2566907159 BuzFail 3;
BA_ "CI_SigName" SG_ 2566907159 BuzFail "Buzzer Failure";
BA_ "CI_SigId" SG_ 2566907159 BuzFail 4022;
BA_ "CI_ParId" SG_ 2566907159 BuzFail "IMH0173";
BA_ "SigType" SG_ 2566907159 RightSpeakFail 4;
BA_ "GenSigTimeoutTime_SGW" SG_ 2566907159 RightSpeakFail 500;
BA_ "GenSigTimeoutTime_PCM" SG_ 2566907159 RightSpeakFail 500;
BA_ "GenSigTimeoutTime_ADCU" SG_ 2566907159 RightSpeakFail 500;
BA_ "GenSigSendType" SG_ 2566907159 RightSpeakFail 3;
BA_ "CI_SigName" SG_ 2566907159 RightSpeakFail "Right Speaker Failure";
BA_ "CI_SigId" SG_ 2566907159 RightSpeakFail 4021;
BA_ "CI_ParId" SG_ 2566907159 RightSpeakFail "IMH0172";
BA_ "SigType" SG_ 2566907159 LeftSpeakFail 4;
BA_ "GenSigTimeoutTime_SGW" SG_ 2566907159 LeftSpeakFail 500;
BA_ "GenSigTimeoutTime_PCM" SG_ 2566907159 LeftSpeakFail 500;
BA_ "GenSigTimeoutTime_ADCU" SG_ 2566907159 LeftSpeakFail 500;
BA_ "GenSigSendType" SG_ 2566907159 LeftSpeakFail 3;
BA_ "CI_SigName" SG_ 2566907159 LeftSpeakFail "Left Speaker Failure";
BA_ "CI_SigId" SG_ 2566907159 LeftSpeakFail 4020;
BA_ "CI_ParId" SG_ 2566907159 LeftSpeakFail "IMH0171";
BA_ "SigType" SG_ 2566907159 DrivDrowsWarnEnaSet 4;
BA_ "GenSigTimeoutTime_SGW" SG_ 2566907159 DrivDrowsWarnEnaSet 500;
BA_ "GenSigTimeoutTime_PCM" SG_ 2566907159 DrivDrowsWarnEnaSet 500;
BA_ "GenSigTimeoutTime_ADCU" SG_ 2566907159 DrivDrowsWarnEnaSet 500;
BA_ "GenSigSendType" SG_ 2566907159 DrivDrowsWarnEnaSet 3;
BA_ "CI_SigName" SG_ 2566907159 DrivDrowsWarnEnaSet "Driver Drowsiness Warning Enable Setting ";
BA_ "CI_SigId" SG_ 2566907159 DrivDrowsWarnEnaSet 4019;
BA_ "CI_ParId" SG_ 2566907159 DrivDrowsWarnEnaSet "IS979";
BA_ "SigType" SG_ 2583638259 StsOfSaf 1;
BA_ "GenSigTimeoutTime_VMU" SG_ 2583638259 StsOfSaf 1250;
BA_ "GenSigTimeoutTime_SGW2" SG_ 2583638259 StsOfSaf 1250;
BA_ "GenSigTimeoutTime_SGW" SG_ 2583638259 StsOfSaf 1250;
BA_ "GenSigTimeoutTime_PCM" SG_ 2583638259 StsOfSaf 1250;
BA_ "CI_SigName" SG_ 2583638259 StsOfSaf "State of Safety";
BA_ "CI_SigId" SG_ 2583638259 StsOfSaf 21378;
BA_ "CI_ParId" SG_ 2583638259 StsOfSaf "MV0007";
BA_ "GenSigTimeoutTime_VMU" SG_ 2583638259 OpSts 1250;
BA_ "GenSigTimeoutTime_SGW2" SG_ 2583638259 OpSts 1250;
BA_ "GenSigTimeoutTime_SGW" SG_ 2583638259 OpSts 1250;
BA_ "GenSigTimeoutTime_PCM" SG_ 2583638259 OpSts 1250;
BA_ "CI_SigName" SG_ 2583638259 OpSts "Operational Status";
BA_ "CI_SigId" SG_ 2583638259 OpSts 21377;
BA_ "CI_ParId" SG_ 2583638259 OpSts "MV0006";
BA_ "SigType" SG_ 2583638259 Temp 1;
BA_ "GenSigTimeoutTime_VMU" SG_ 2583638259 Temp 1250;
BA_ "GenSigTimeoutTime_SGW2" SG_ 2583638259 Temp 1250;
BA_ "GenSigTimeoutTime_SGW" SG_ 2583638259 Temp 1250;
BA_ "GenSigTimeoutTime_PCM" SG_ 2583638259 Temp 1250;
BA_ "GenSigStartValue" SG_ 2583638259 Temp 40;
BA_ "CI_SigName" SG_ 2583638259 Temp "Temperature";
BA_ "CI_SigId" SG_ 2583638259 Temp 21376;
BA_ "CI_ParId" SG_ 2583638259 Temp "MV0004";
BA_ "SigType" SG_ 2583638259 ThermEvtDet 4;
BA_ "GenSigTimeoutTime_VMU" SG_ 2583638259 ThermEvtDet 1250;
BA_ "GenSigTimeoutTime_SGW2" SG_ 2583638259 ThermEvtDet 1250;
BA_ "GenSigTimeoutTime_SGW" SG_ 2583638259 ThermEvtDet 1250;
BA_ "GenSigTimeoutTime_PCM" SG_ 2583638259 ThermEvtDet 1250;
BA_ "CI_SigName" SG_ 2583638259 ThermEvtDet "Thermal Event Detection";
BA_ "CI_SigId" SG_ 2583638259 ThermEvtDet 21375;
BA_ "CI_ParId" SG_ 2583638259 ThermEvtDet "MV0001";
BA_ "GenSigTimeoutTime_VMU" SG_ 2583638259 AsrProf2Cnt_FF30F3 1250;
BA_ "GenSigTimeoutTime_SGW2" SG_ 2583638259 AsrProf2Cnt_FF30F3 1250;
BA_ "GenSigTimeoutTime_SGW" SG_ 2583638259 AsrProf2Cnt_FF30F3 1250;
BA_ "GenSigTimeoutTime_PCM" SG_ 2583638259 AsrProf2Cnt_FF30F3 1250;
BA_ "CI_SigName" SG_ 2583638259 AsrProf2Cnt_FF30F3 "Autosar Profile 2 Counter";
BA_ "CI_SigId" SG_ 2583638259 AsrProf2Cnt_FF30F3 21374;
BA_ "CI_ParId" SG_ 2583638259 AsrProf2Cnt_FF30F3 "IMH0066";
BA_ "GenSigTimeoutTime_VMU" SG_ 2583638259 AsrProf2Crc_FF30F3 1250;
BA_ "GenSigTimeoutTime_SGW2" SG_ 2583638259 AsrProf2Crc_FF30F3 1250;
BA_ "GenSigTimeoutTime_SGW" SG_ 2583638259 AsrProf2Crc_FF30F3 1250;
BA_ "GenSigTimeoutTime_PCM" SG_ 2583638259 AsrProf2Crc_FF30F3 1250;
BA_ "CI_SigName" SG_ 2583638259 AsrProf2Crc_FF30F3 "Autosar Profile 2 CRC";
BA_ "CI_SigId" SG_ 2583638259 AsrProf2Crc_FF30F3 21373;
BA_ "CI_ParId" SG_ 2583638259 AsrProf2Crc_FF30F3 "IMH0067";
BA_ "SigType" SG_ 2650750451 HvessTotAccumChg_FF3DF3 1;
BA_ "SPN" SG_ 2650750451 HvessTotAccumChg_FF3DF3 8212;
BA_ "GenSigTimeoutTime_SGW" SG_ 2650750451 HvessTotAccumChg_FF3DF3 5000;
BA_ "GenSigTimeoutTime_PCM" SG_ 2650750451 HvessTotAccumChg_FF3DF3 5000;
BA_ "GenSigTimeoutTime_MPPxPTFE2" SG_ 2650750451 HvessTotAccumChg_FF3DF3 5000;
BA_ "GenSigTimeoutTime_FMS_FMS5" SG_ 2650750451 HvessTotAccumChg_FF3DF3 5000;
BA_ "CI_SigName" SG_ 2650750451 HvessTotAccumChg_FF3DF3 "HVESS Total Accumulated Charge";
BA_ "CI_SigId" SG_ 2650750451 HvessTotAccumChg_FF3DF3 13904;
BA_ "CI_ParId" SG_ 2650750451 HvessTotAccumChg_FF3DF3 "8212";
BA_ "SigType" SG_ 2650750451 HvessTotEnergyTput_FF3DF3 1;
BA_ "SPN" SG_ 2650750451 HvessTotEnergyTput_FF3DF3 8211;
BA_ "GenSigTimeoutTime_SGW" SG_ 2650750451 HvessTotEnergyTput_FF3DF3 5000;
BA_ "GenSigTimeoutTime_PCM" SG_ 2650750451 HvessTotEnergyTput_FF3DF3 5000;
BA_ "GenSigTimeoutTime_MPPxPTFE2" SG_ 2650750451 HvessTotEnergyTput_FF3DF3 5000;
BA_ "GenSigTimeoutTime_IC_MulticII" SG_ 2650750451 HvessTotEnergyTput_FF3DF3 5000;
BA_ "GenSigTimeoutTime_FMS_FMS5" SG_ 2650750451 HvessTotEnergyTput_FF3DF3 5000;
BA_ "CI_SigName" SG_ 2650750451 HvessTotEnergyTput_FF3DF3 "HVESS Total Energy Throughput";
BA_ "CI_SigId" SG_ 2650750451 HvessTotEnergyTput_FF3DF3 13903;
BA_ "CI_ParId" SG_ 2650750451 HvessTotEnergyTput_FF3DF3 "8211";
BA_ "SigType" SG_ 2650750451 HvessSoh_FF3DF3 1;
BA_ "SPN" SG_ 2650750451 HvessSoh_FF3DF3 8121;
BA_ "GenSigTimeoutTime_SGW" SG_ 2650750451 HvessSoh_FF3DF3 5000;
BA_ "GenSigTimeoutTime_PCM" SG_ 2650750451 HvessSoh_FF3DF3 5000;
BA_ "GenSigTimeoutTime_MPPxPTFE2" SG_ 2650750451 HvessSoh_FF3DF3 5000;
BA_ "GenSigTimeoutTime_FMS_FMS5" SG_ 2650750451 HvessSoh_FF3DF3 5000;
BA_ "CI_SigName" SG_ 2650750451 HvessSoh_FF3DF3 "HVESS State of Health";
BA_ "CI_SigId" SG_ 2650750451 HvessSoh_FF3DF3 13901;
BA_ "CI_ParId" SG_ 2650750451 HvessSoh_FF3DF3 "8121";
BA_ "GenSigTimeoutTime_SGW" SG_ 2566894871 CntryCode 5000;
BA_ "GenSigTimeoutTime_PCM" SG_ 2566894871 CntryCode 5000;
BA_ "GenSigTimeoutTime_ADCU" SG_ 2566894871 CntryCode 5000;
BA_ "GenSigSendType" SG_ 2566894871 CntryCode 3;
BA_ "CI_SigName" SG_ 2566894871 CntryCode "Country Code";
BA_ "CI_SigId" SG_ 2566894871 CntryCode 2814;
BA_ "CI_ParId" SG_ 2566894871 CntryCode "IMH0088";
BA_ "GenSigTimeoutTime_SGW" SG_ 2566894871 IntlSpeedAssantActv 5000;
BA_ "GenSigTimeoutTime_PCM" SG_ 2566894871 IntlSpeedAssantActv 5000;
BA_ "GenSigTimeoutTime_ADCU" SG_ 2566894871 IntlSpeedAssantActv 5000;
BA_ "GenSigSendType" SG_ 2566894871 IntlSpeedAssantActv 3;
BA_ "CI_SigName" SG_ 2566894871 IntlSpeedAssantActv "Intelligent Speed Assistant Activation";
BA_ "CI_SigId" SG_ 2566894871 IntlSpeedAssantActv 2813;
BA_ "CI_ParId" SG_ 2566894871 IntlSpeedAssantActv "IS949";
BA_ "SigType" SG_ 2566895006 IsaSpeedOverridden 4;
BA_ "GenSigTimeoutTime_SGW" SG_ 2566895006 IsaSpeedOverridden 5000;
BA_ "GenSigTimeoutTime_PCM" SG_ 2566895006 IsaSpeedOverridden 5000;
BA_ "GenSigSendType" SG_ 2566895006 IsaSpeedOverridden 3;
BA_ "CI_SigName" SG_ 2566895006 IsaSpeedOverridden "IsaSpeedOverridden";
BA_ "CI_SigId" SG_ 2566895006 IsaSpeedOverridden 19927;
BA_ "CI_ParId" SG_ 2566895006 IsaSpeedOverridden "IMH0223";
BA_ "SigType" SG_ 2566895006 SpeedLimConf 4;
BA_ "GenSigTimeoutTime_SGW" SG_ 2566895006 SpeedLimConf 5000;
BA_ "GenSigTimeoutTime_PCM" SG_ 2566895006 SpeedLimConf 5000;
BA_ "GenSigSendType" SG_ 2566895006 SpeedLimConf 3;
BA_ "CI_SigName" SG_ 2566895006 SpeedLimConf "Speed Limit Confidence";
BA_ "CI_SigId" SG_ 2566895006 SpeedLimConf 2811;
BA_ "CI_ParId" SG_ 2566895006 SpeedLimConf "IMH0182";
BA_ "GenSigTimeoutTime_SGW" SG_ 2566895006 MaxVslUnitless 5000;
BA_ "GenSigTimeoutTime_PCM" SG_ 2566895006 MaxVslUnitless 5000;
BA_ "GenSigTimeoutTime_IC_MulticS" SG_ 2566895006 MaxVslUnitless 5000;
BA_ "GenSigTimeoutTime_IC_MulticII" SG_ 2566895006 MaxVslUnitless 5000;
BA_ "GenSigSendType" SG_ 2566895006 MaxVslUnitless 3;
BA_ "CI_SigName" SG_ 2566895006 MaxVslUnitless "Maximum Vehicle Speed Limit Unitless";
BA_ "CI_SigId" SG_ 2566895006 MaxVslUnitless 2810;
BA_ "CI_ParId" SG_ 2566895006 MaxVslUnitless "IMH0119";
BA_ "GenSigTimeoutTime_SGW" SG_ 2566895006 CntryCode_FFB59E 5000;
BA_ "GenSigTimeoutTime_PCM" SG_ 2566895006 CntryCode_FFB59E 5000;
BA_ "GenSigTimeoutTime_IC_MulticS" SG_ 2566895006 CntryCode_FFB59E 5000;
BA_ "GenSigTimeoutTime_IC_MulticII" SG_ 2566895006 CntryCode_FFB59E 5000;
BA_ "GenSigSendType" SG_ 2566895006 CntryCode_FFB59E 3;
BA_ "CI_SigName" SG_ 2566895006 CntryCode_FFB59E "Country Code";
BA_ "CI_SigId" SG_ 2566895006 CntryCode_FFB59E 2809;
BA_ "CI_ParId" SG_ 2566895006 CntryCode_FFB59E "IMH0088";
BA_ "SigType" SG_ 2566895006 CntryCodeCfg 4;
BA_ "GenSigTimeoutTime_SGW" SG_ 2566895006 CntryCodeCfg 5000;
BA_ "GenSigTimeoutTime_PCM" SG_ 2566895006 CntryCodeCfg 5000;
BA_ "GenSigTimeoutTime_IC_MulticS" SG_ 2566895006 CntryCodeCfg 5000;
BA_ "GenSigTimeoutTime_IC_MulticII" SG_ 2566895006 CntryCodeCfg 5000;
BA_ "GenSigSendType" SG_ 2566895006 CntryCodeCfg 3;
BA_ "CI_SigName" SG_ 2566895006 CntryCodeCfg "Country Code Configuration";
BA_ "CI_SigId" SG_ 2566895006 CntryCodeCfg 2808;
BA_ "CI_ParId" SG_ 2566895006 CntryCodeCfg "IMH0087";
BA_ "GenSigTimeoutTime_SGW" SG_ 2566895006 IsaDbgSts 5000;
BA_ "GenSigTimeoutTime_PCM" SG_ 2566895006 IsaDbgSts 5000;
BA_ "GenSigSendType" SG_ 2566895006 IsaDbgSts 3;
BA_ "CI_SigName" SG_ 2566895006 IsaDbgSts "ISA Debug Status";
BA_ "CI_SigId" SG_ 2566895006 IsaDbgSts 2807;
BA_ "CI_ParId" SG_ 2566895006 IsaDbgSts "IS989";
BA_ "GenSigTimeoutTime_SGW" SG_ 2566895006 IntlSpeedAssantSts 5000;
BA_ "GenSigTimeoutTime_PCM" SG_ 2566895006 IntlSpeedAssantSts 5000;
BA_ "GenSigTimeoutTime_IC_MulticS" SG_ 2566895006 IntlSpeedAssantSts 5000;
BA_ "GenSigTimeoutTime_IC_MulticII" SG_ 2566895006 IntlSpeedAssantSts 5000;
BA_ "GenSigSendType" SG_ 2566895006 IntlSpeedAssantSts 3;
BA_ "CI_SigName" SG_ 2566895006 IntlSpeedAssantSts "Intelligent Speed Assistant Status";
BA_ "CI_SigId" SG_ 2566895006 IntlSpeedAssantSts 2806;
BA_ "CI_ParId" SG_ 2566895006 IntlSpeedAssantSts "IS947";
BA_ "GenSigTimeoutTime_SGW" SG_ 2566895006 IntlSpeedAssantActv_FFB59E 5000;
BA_ "GenSigTimeoutTime_PCM" SG_ 2566895006 IntlSpeedAssantActv_FFB59E 5000;
BA_ "GenSigTimeoutTime_IC_MulticS" SG_ 2566895006 IntlSpeedAssantActv_FFB59E 5000;
BA_ "GenSigTimeoutTime_IC_MulticII" SG_ 2566895006 IntlSpeedAssantActv_FFB59E 5000;
BA_ "GenSigSendType" SG_ 2566895006 IntlSpeedAssantActv_FFB59E 3;
BA_ "CI_SigName" SG_ 2566895006 IntlSpeedAssantActv_FFB59E "Intelligent Speed Assistant Activation";
BA_ "CI_SigId" SG_ 2566895006 IntlSpeedAssantActv_FFB59E 19926;
BA_ "CI_ParId" SG_ 2566895006 IntlSpeedAssantActv_FFB59E "IS949";
BA_ "GenSigTimeoutTime_SGW" SG_ 2566895006 MaxVslWarn 5000;
BA_ "GenSigTimeoutTime_PCM" SG_ 2566895006 MaxVslWarn 5000;
BA_ "GenSigTimeoutTime_IC_MulticS" SG_ 2566895006 MaxVslWarn 5000;
BA_ "GenSigTimeoutTime_IC_MulticII" SG_ 2566895006 MaxVslWarn 5000;
BA_ "GenSigSendType" SG_ 2566895006 MaxVslWarn 3;
BA_ "CI_SigName" SG_ 2566895006 MaxVslWarn "Maximum Vehicle Speed Limit Warning";
BA_ "CI_SigId" SG_ 2566895006 MaxVslWarn 2804;
BA_ "CI_ParId" SG_ 2566895006 MaxVslWarn "IS945";
BA_ "SigType" SG_ 2365575713 EngStarterSts 4;
BA_ "GenSigTimeoutTime_SGW2" SG_ 2365575713 EngStarterSts 5000;
BA_ "GenSigTimeoutTime_SGW" SG_ 2365575713 EngStarterSts 5000;
BA_ "GenSigTimeoutTime_PCM" SG_ 2365575713 EngStarterSts 5000;
BA_ "GenSigTimeoutTime_AI_CAID" SG_ 2365575713 EngStarterSts 5000;
BA_ "GenSigSendType" SG_ 2365575713 EngStarterSts 3;
BA_ "CI_SigName" SG_ 2365575713 EngStarterSts "Engine Starter Status";
BA_ "CI_SigId" SG_ 2365575713 EngStarterSts 10492;
BA_ "CI_ParId" SG_ 2365575713 EngStarterSts "I186";
BA_ "SigType" SG_ 2365575713 IgnOn 4;
BA_ "GenSigTimeoutTime_TPMS" SG_ 2365575713 IgnOn 5000;
BA_ "GenSigTimeoutTime_SGW2" SG_ 2365575713 IgnOn 5000;
BA_ "GenSigTimeoutTime_SGW" SG_ 2365575713 IgnOn 5000;
BA_ "GenSigTimeoutTime_SAS" SG_ 2365575713 IgnOn 5000;
BA_ "GenSigTimeoutTime_PCM" SG_ 2365575713 IgnOn 5000;
BA_ "GenSigTimeoutTime_DMS" SG_ 2365575713 IgnOn 5000;
BA_ "GenSigTimeoutTime_AI_CAID" SG_ 2365575713 IgnOn 5000;
BA_ "GenSigSendType" SG_ 2365575713 IgnOn 3;
BA_ "CI_SigName" SG_ 2365575713 IgnOn "Ignition On";
BA_ "CI_SigId" SG_ 2365575713 IgnOn 10488;
BA_ "CI_ParId" SG_ 2365575713 IgnOn "I013";
BA_ "SigType" SG_ 2566892573 SevAnomalyInBlk2 4;
BA_ "CI_SigName" SG_ 2566892573 SevAnomalyInBlk2 "Severe anomaly in Block 2";
BA_ "CI_SigId" SG_ 2566892573 SevAnomalyInBlk2 2515;
BA_ "CI_ParId" SG_ 2566892573 SevAnomalyInBlk2 "IMH0064";
BA_ "SigType" SG_ 2566892573 SevAnomalyInBlk1 4;
BA_ "CI_SigName" SG_ 2566892573 SevAnomalyInBlk1 "Severe anomaly in Block 1";
BA_ "CI_SigId" SG_ 2566892573 SevAnomalyInBlk1 2514;
BA_ "CI_ParId" SG_ 2566892573 SevAnomalyInBlk1 "IMH0063";
BA_ "SigType" SG_ 2566892573 Blk2Full 4;
BA_ "CI_SigName" SG_ 2566892573 Blk2Full "Block 2 full";
BA_ "CI_SigId" SG_ 2566892573 Blk2Full 2513;
BA_ "CI_ParId" SG_ 2566892573 Blk2Full "IMH0062";
BA_ "SigType" SG_ 2566892573 Blk1Full 4;
BA_ "CI_SigName" SG_ 2566892573 Blk1Full "Block 1 full";
BA_ "CI_SigId" SG_ 2566892573 Blk1Full 2512;
BA_ "CI_ParId" SG_ 2566892573 Blk1Full "IMH0061";
BA_ "SigType" SG_ 2566892618 WarnRx 4;
BA_ "CI_SigName" SG_ 2566892618 WarnRx "Warning Received";
BA_ "CI_SigId" SG_ 2566892618 WarnRx 2517;
BA_ "CI_ParId" SG_ 2566892618 WarnRx "IMH0065";
BA_ "GenSigTimeoutTime_SGW" SG_ 2566885148 SpeedLimType 5000;
BA_ "GenSigTimeoutTime_ADCU" SG_ 2566885148 SpeedLimType 5000;
BA_ "CI_SigName" SG_ 2566885148 SpeedLimType "Speed Limit Type";
BA_ "CI_SigId" SG_ 2566885148 SpeedLimType 12998;
BA_ "CI_ParId" SG_ 2566885148 SpeedLimType "V584";
BA_ "GenSigTimeoutTime_SGW" SG_ 2566885148 BuiltUpArea 5000;
BA_ "GenSigTimeoutTime_ADCU" SG_ 2566885148 BuiltUpArea 5000;
BA_ "CI_SigName" SG_ 2566885148 BuiltUpArea "Built Up Area";
BA_ "CI_SigId" SG_ 2566885148 BuiltUpArea 12994;
BA_ "CI_ParId" SG_ 2566885148 BuiltUpArea "V580";
BA_ "GenSigTimeoutTime_SGW" SG_ 2566885148 FunctRoadClass 5000;
BA_ "GenSigTimeoutTime_ADCU" SG_ 2566885148 FunctRoadClass 5000;
BA_ "CI_SigName" SG_ 2566885148 FunctRoadClass "Functional Road Class";
BA_ "CI_SigId" SG_ 2566885148 FunctRoadClass 12995;
BA_ "CI_ParId" SG_ 2566885148 FunctRoadClass "V581";
BA_ "SigType" SG_ 2566898670 WFact 1;
BA_ "GenSigTimeoutTime_SGW" SG_ 2566898670 WFact 300000;
BA_ "GenSigTimeoutTime_PCM" SG_ 2566898670 WFact 300000;
BA_ "GenSigStartValue" SG_ 2566898670 WFact 2400;
BA_ "GenSigSendType" SG_ 2566898670 WFact 3;
BA_ "CI_SigName" SG_ 2566898670 WFact "W Factor";
BA_ "CI_SigId" SG_ 2566898670 WFact 751;
BA_ "CI_ParId" SG_ 2566898670 WFact "V007";
BA_ "SigType" SG_ 2566898670 NextCalDateYr 1;
BA_ "GenSigTimeoutTime_SGW" SG_ 2566898670 NextCalDateYr 300000;
BA_ "GenSigTimeoutTime_PCM" SG_ 2566898670 NextCalDateYr 300000;
BA_ "GenSigSendType" SG_ 2566898670 NextCalDateYr 3;
BA_ "CI_SigName" SG_ 2566898670 NextCalDateYr "Next Calibration Date - Year";
BA_ "CI_SigId" SG_ 2566898670 NextCalDateYr 750;
BA_ "CI_ParId" SG_ 2566898670 NextCalDateYr "V052";
BA_ "SigType" SG_ 2566898670 NextCalDateMonth 1;
BA_ "GenSigTimeoutTime_SGW" SG_ 2566898670 NextCalDateMonth 300000;
BA_ "GenSigTimeoutTime_PCM" SG_ 2566898670 NextCalDateMonth 300000;
BA_ "GenSigStartValue" SG_ 2566898670 NextCalDateMonth 1;
BA_ "GenSigSendType" SG_ 2566898670 NextCalDateMonth 3;
BA_ "CI_SigName" SG_ 2566898670 NextCalDateMonth "Next Calibration Date - Month";
BA_ "CI_SigId" SG_ 2566898670 NextCalDateMonth 749;
BA_ "CI_ParId" SG_ 2566898670 NextCalDateMonth "V051";
BA_ "SigType" SG_ 2566898670 NextCalDateDay 1;
BA_ "GenSigTimeoutTime_SGW" SG_ 2566898670 NextCalDateDay 300000;
BA_ "GenSigTimeoutTime_PCM" SG_ 2566898670 NextCalDateDay 300000;
BA_ "GenSigStartValue" SG_ 2566898670 NextCalDateDay 1;
BA_ "GenSigSendType" SG_ 2566898670 NextCalDateDay 3;
BA_ "CI_SigName" SG_ 2566898670 NextCalDateDay "Next Calibration Date - Day";
BA_ "CI_SigId" SG_ 2566898670 NextCalDateDay 748;
BA_ "CI_ParId" SG_ 2566898670 NextCalDateDay "V050";
BA_ "SigType" SG_ 2566898670 PrefLang 3;
BA_ "GenSigTimeoutTime_SGW" SG_ 2566898670 PrefLang 300000;
BA_ "GenSigTimeoutTime_PCM" SG_ 2566898670 PrefLang 300000;
BA_ "GenSigSendType" SG_ 2566898670 PrefLang 3;
BA_ "CI_SigName" SG_ 2566898670 PrefLang "Preferred Language";
BA_ "CI_SigId" SG_ 2566898670 PrefLang 747;
BA_ "CI_ParId" SG_ 2566898670 PrefLang "V005";
BA_ "SigType" SG_ 2566898670 Driv1Id_FFC3EE 3;
BA_ "GenSigTimeoutTime_SGW" SG_ 2566898670 Driv1Id_FFC3EE 300000;
BA_ "GenSigTimeoutTime_PCM" SG_ 2566898670 Driv1Id_FFC3EE 300000;
BA_ "GenSigSendType" SG_ 2566898670 Driv1Id_FFC3EE 3;
BA_ "CI_SigName" SG_ 2566898670 Driv1Id_FFC3EE "Driver 1 Identification";
BA_ "CI_SigId" SG_ 2566898670 Driv1Id_FFC3EE 746;
BA_ "CI_ParId" SG_ 2566898670 Driv1Id_FFC3EE "V004";
BA_ "SigType" SG_ 2566898926 PrintDrawSts 4;
BA_ "GenSigTimeoutTime_SGW" SG_ 2566898926 PrintDrawSts 50000;
BA_ "GenSigTimeoutTime_PCM" SG_ 2566898926 PrintDrawSts 50000;
BA_ "CI_SigName" SG_ 2566898926 PrintDrawSts "Printer Drawer State";
BA_ "CI_SigId" SG_ 2566898926 PrintDrawSts 758;
BA_ "CI_ParId" SG_ 2566898926 PrintDrawSts "V013";
BA_ "SigType" SG_ 2566898926 EndOfLifeDriv1CardAlert 4;
BA_ "GenSigTimeoutTime_SGW" SG_ 2566898926 EndOfLifeDriv1CardAlert 50000;
BA_ "GenSigTimeoutTime_PCM" SG_ 2566898926 EndOfLifeDriv1CardAlert 50000;
BA_ "CI_SigName" SG_ 2566898926 EndOfLifeDriv1CardAlert "End Of Life Driver 1 Card Alert";
BA_ "CI_SigId" SG_ 2566898926 EndOfLifeDriv1CardAlert 757;
BA_ "CI_ParId" SG_ 2566898926 EndOfLifeDriv1CardAlert "V012";
BA_ "SigType" SG_ 2566898926 Driv1CardDwlAlert 4;
BA_ "GenSigTimeoutTime_SGW" SG_ 2566898926 Driv1CardDwlAlert 50000;
BA_ "GenSigTimeoutTime_PCM" SG_ 2566898926 Driv1CardDwlAlert 50000;
BA_ "CI_SigName" SG_ 2566898926 Driv1CardDwlAlert "Driver1 Card Download Alert";
BA_ "CI_SigId" SG_ 2566898926 Driv1CardDwlAlert 756;
BA_ "CI_ParId" SG_ 2566898926 Driv1CardDwlAlert "V011";
BA_ "SigType" SG_ 2566898926 Driv1CurDurOfSelActv 1;
BA_ "GenSigTimeoutTime_SGW" SG_ 2566898926 Driv1CurDurOfSelActv 50000;
BA_ "GenSigTimeoutTime_PCM" SG_ 2566898926 Driv1CurDurOfSelActv 50000;
BA_ "CI_SigName" SG_ 2566898926 Driv1CurDurOfSelActv "Driver1 Current Duration Of Selected Activity";
BA_ "CI_SigId" SG_ 2566898926 Driv1CurDurOfSelActv 755;
BA_ "CI_ParId" SG_ 2566898926 Driv1CurDurOfSelActv "V010";
BA_ "SigType" SG_ 2566898926 Driv1CumulBreakTime 1;
BA_ "GenSigTimeoutTime_SGW" SG_ 2566898926 Driv1CumulBreakTime 50000;
BA_ "GenSigTimeoutTime_PCM" SG_ 2566898926 Driv1CumulBreakTime 50000;
BA_ "CI_SigName" SG_ 2566898926 Driv1CumulBreakTime "Driver1 Cumulative Break Time";
BA_ "CI_SigId" SG_ 2566898926 Driv1CumulBreakTime 754;
BA_ "CI_ParId" SG_ 2566898926 Driv1CumulBreakTime "V009";
BA_ "SigType" SG_ 2566898926 Driv1ContDrivTime 1;
BA_ "GenSigTimeoutTime_SGW" SG_ 2566898926 Driv1ContDrivTime 50000;
BA_ "GenSigTimeoutTime_PCM" SG_ 2566898926 Driv1ContDrivTime 50000;
BA_ "CI_SigName" SG_ 2566898926 Driv1ContDrivTime "Driver1 Continuous Driving Time";
BA_ "CI_SigId" SG_ 2566898926 Driv1ContDrivTime 753;
BA_ "CI_ParId" SG_ 2566898926 Driv1ContDrivTime "V008";
BA_ "SigType" SG_ 2566899694 AvCnt 1;
BA_ "GenSigTimeoutTime_SGW" SG_ 2566899694 AvCnt 300000;
BA_ "GenSigTimeoutTime_PCM" SG_ 2566899694 AvCnt 300000;
BA_ "GenSigSendType" SG_ 2566899694 AvCnt 3;
BA_ "CI_SigName" SG_ 2566899694 AvCnt "Available Counter";
BA_ "CI_SigId" SG_ 2566899694 AvCnt 770;
BA_ "CI_ParId" SG_ 2566899694 AvCnt "V049";
BA_ "SigType" SG_ 2566899694 WorkCnt 1;
BA_ "GenSigTimeoutTime_SGW" SG_ 2566899694 WorkCnt 300000;
BA_ "GenSigTimeoutTime_PCM" SG_ 2566899694 WorkCnt 300000;
BA_ "GenSigSendType" SG_ 2566899694 WorkCnt 3;
BA_ "CI_SigName" SG_ 2566899694 WorkCnt "Work Counter";
BA_ "CI_SigId" SG_ 2566899694 WorkCnt 769;
BA_ "CI_ParId" SG_ 2566899694 WorkCnt "V048";
BA_ "SigType" SG_ 2566899694 DrivCnt 1;
BA_ "GenSigTimeoutTime_SGW" SG_ 2566899694 DrivCnt 300000;
BA_ "GenSigTimeoutTime_PCM" SG_ 2566899694 DrivCnt 300000;
BA_ "GenSigSendType" SG_ 2566899694 DrivCnt 3;
BA_ "CI_SigName" SG_ 2566899694 DrivCnt "Driving Counter";
BA_ "CI_SigId" SG_ 2566899694 DrivCnt 768;
BA_ "CI_ParId" SG_ 2566899694 DrivCnt "V047";
BA_ "SigType" SG_ 2566899694 TwoWeeksTotOdo 1;
BA_ "GenSigTimeoutTime_SGW" SG_ 2566899694 TwoWeeksTotOdo 300000;
BA_ "GenSigTimeoutTime_PCM" SG_ 2566899694 TwoWeeksTotOdo 300000;
BA_ "GenSigSendType" SG_ 2566899694 TwoWeeksTotOdo 3;
BA_ "CI_SigName" SG_ 2566899694 TwoWeeksTotOdo "Two Weeks Total Odometer";
BA_ "CI_SigId" SG_ 2566899694 TwoWeeksTotOdo 767;
BA_ "CI_ParId" SG_ 2566899694 TwoWeeksTotOdo "V046";
BA_ "SigType" SG_ 2566899694 WeekTotOdo 1;
BA_ "GenSigTimeoutTime_SGW" SG_ 2566899694 WeekTotOdo 300000;
BA_ "GenSigTimeoutTime_PCM" SG_ 2566899694 WeekTotOdo 300000;
BA_ "GenSigSendType" SG_ 2566899694 WeekTotOdo 3;
BA_ "CI_SigName" SG_ 2566899694 WeekTotOdo "Weekly Total Odometer";
BA_ "CI_SigId" SG_ 2566899694 WeekTotOdo 766;
BA_ "CI_ParId" SG_ 2566899694 WeekTotOdo "V045";
BA_ "SigType" SG_ 2566899694 DayOdo 1;
BA_ "GenSigTimeoutTime_SGW" SG_ 2566899694 DayOdo 300000;
BA_ "GenSigTimeoutTime_PCM" SG_ 2566899694 DayOdo 300000;
BA_ "GenSigSendType" SG_ 2566899694 DayOdo 3;
BA_ "CI_SigName" SG_ 2566899694 DayOdo "Daily Odometer";
BA_ "CI_SigId" SG_ 2566899694 DayOdo 765;
BA_ "CI_ParId" SG_ 2566899694 DayOdo "V044";
BA_ "GenSigTimeoutTime_SGW" SG_ 2566899694 DayRestPer7Flag 300000;
BA_ "GenSigTimeoutTime_PCM" SG_ 2566899694 DayRestPer7Flag 300000;
BA_ "GenSigSendType" SG_ 2566899694 DayRestPer7Flag 3;
BA_ "CI_SigName" SG_ 2566899694 DayRestPer7Flag "Daily Resting Period 7 Flag";
BA_ "CI_SigId" SG_ 2566899694 DayRestPer7Flag 13526;
BA_ "CI_ParId" SG_ 2566899694 DayRestPer7Flag "V043";
BA_ "GenSigTimeoutTime_SGW" SG_ 2566899694 DayRestPer7 300000;
BA_ "GenSigTimeoutTime_PCM" SG_ 2566899694 DayRestPer7 300000;
BA_ "GenSigSendType" SG_ 2566899694 DayRestPer7 3;
BA_ "CI_SigName" SG_ 2566899694 DayRestPer7 "Daily Resting Period 7";
BA_ "CI_SigId" SG_ 2566899694 DayRestPer7 13525;
BA_ "CI_ParId" SG_ 2566899694 DayRestPer7 "V042";
BA_ "GenSigTimeoutTime_SGW" SG_ 2566899694 DayRestPer6Flag 300000;
BA_ "GenSigTimeoutTime_PCM" SG_ 2566899694 DayRestPer6Flag 300000;
BA_ "GenSigSendType" SG_ 2566899694 DayRestPer6Flag 3;
BA_ "CI_SigName" SG_ 2566899694 DayRestPer6Flag "Daily Resting Period 6 Flag";
BA_ "CI_SigId" SG_ 2566899694 DayRestPer6Flag 13524;
BA_ "CI_ParId" SG_ 2566899694 DayRestPer6Flag "V041";
BA_ "GenSigTimeoutTime_SGW" SG_ 2566899694 DayRestPer6 300000;
BA_ "GenSigTimeoutTime_PCM" SG_ 2566899694 DayRestPer6 300000;
BA_ "GenSigSendType" SG_ 2566899694 DayRestPer6 3;
BA_ "CI_SigName" SG_ 2566899694 DayRestPer6 "Daily Resting Period 6";
BA_ "CI_SigId" SG_ 2566899694 DayRestPer6 13523;
BA_ "CI_ParId" SG_ 2566899694 DayRestPer6 "V040";
BA_ "GenSigTimeoutTime_SGW" SG_ 2566899694 DayRestPer5Flag 300000;
BA_ "GenSigTimeoutTime_PCM" SG_ 2566899694 DayRestPer5Flag 300000;
BA_ "GenSigSendType" SG_ 2566899694 DayRestPer5Flag 3;
BA_ "CI_SigName" SG_ 2566899694 DayRestPer5Flag "Daily Resting Period 5 Flag";
BA_ "CI_SigId" SG_ 2566899694 DayRestPer5Flag 13522;
BA_ "CI_ParId" SG_ 2566899694 DayRestPer5Flag "V039";
BA_ "GenSigTimeoutTime_SGW" SG_ 2566899694 DayRestPer5 300000;
BA_ "GenSigTimeoutTime_PCM" SG_ 2566899694 DayRestPer5 300000;
BA_ "GenSigSendType" SG_ 2566899694 DayRestPer5 3;
BA_ "CI_SigName" SG_ 2566899694 DayRestPer5 "Daily Resting Period 5";
BA_ "CI_SigId" SG_ 2566899694 DayRestPer5 13521;
BA_ "CI_ParId" SG_ 2566899694 DayRestPer5 "V038";
BA_ "GenSigTimeoutTime_SGW" SG_ 2566899694 DayRestPer4Flag 300000;
BA_ "GenSigTimeoutTime_PCM" SG_ 2566899694 DayRestPer4Flag 300000;
BA_ "GenSigSendType" SG_ 2566899694 DayRestPer4Flag 3;
BA_ "CI_SigName" SG_ 2566899694 DayRestPer4Flag "Daily Resting Period 4 Flag";
BA_ "CI_SigId" SG_ 2566899694 DayRestPer4Flag 13520;
BA_ "CI_ParId" SG_ 2566899694 DayRestPer4Flag "V037";
BA_ "GenSigTimeoutTime_SGW" SG_ 2566899694 DayRestPer4 300000;
BA_ "GenSigTimeoutTime_PCM" SG_ 2566899694 DayRestPer4 300000;
BA_ "GenSigSendType" SG_ 2566899694 DayRestPer4 3;
BA_ "CI_SigName" SG_ 2566899694 DayRestPer4 "Daily Resting Period 4";
BA_ "CI_SigId" SG_ 2566899694 DayRestPer4 13519;
BA_ "CI_ParId" SG_ 2566899694 DayRestPer4 "V036";
BA_ "GenSigTimeoutTime_SGW" SG_ 2566899694 DayRestPer3Flag 300000;
BA_ "GenSigTimeoutTime_PCM" SG_ 2566899694 DayRestPer3Flag 300000;
BA_ "GenSigSendType" SG_ 2566899694 DayRestPer3Flag 3;
BA_ "CI_SigName" SG_ 2566899694 DayRestPer3Flag "Daily Resting Period 3 Flag";
BA_ "CI_SigId" SG_ 2566899694 DayRestPer3Flag 13518;
BA_ "CI_ParId" SG_ 2566899694 DayRestPer3Flag "V035";
BA_ "GenSigTimeoutTime_SGW" SG_ 2566899694 DayRestPer3 300000;
BA_ "GenSigTimeoutTime_PCM" SG_ 2566899694 DayRestPer3 300000;
BA_ "GenSigSendType" SG_ 2566899694 DayRestPer3 3;
BA_ "CI_SigName" SG_ 2566899694 DayRestPer3 "Daily Resting Period 3";
BA_ "CI_SigId" SG_ 2566899694 DayRestPer3 13517;
BA_ "CI_ParId" SG_ 2566899694 DayRestPer3 "V034";
BA_ "GenSigTimeoutTime_SGW" SG_ 2566899694 DayRestPer2Flag 300000;
BA_ "GenSigTimeoutTime_PCM" SG_ 2566899694 DayRestPer2Flag 300000;
BA_ "GenSigSendType" SG_ 2566899694 DayRestPer2Flag 3;
BA_ "CI_SigName" SG_ 2566899694 DayRestPer2Flag "Daily Resting Period 2 Flag";
BA_ "CI_SigId" SG_ 2566899694 DayRestPer2Flag 13516;
BA_ "CI_ParId" SG_ 2566899694 DayRestPer2Flag "V033";
BA_ "GenSigTimeoutTime_SGW" SG_ 2566899694 DayRestPer2 300000;
BA_ "GenSigTimeoutTime_PCM" SG_ 2566899694 DayRestPer2 300000;
BA_ "GenSigSendType" SG_ 2566899694 DayRestPer2 3;
BA_ "CI_SigName" SG_ 2566899694 DayRestPer2 "Daily Resting Period 2";
BA_ "CI_SigId" SG_ 2566899694 DayRestPer2 13515;
BA_ "CI_ParId" SG_ 2566899694 DayRestPer2 "V032";
BA_ "GenSigTimeoutTime_SGW" SG_ 2566899694 DayRestPer1Flag 300000;
BA_ "GenSigTimeoutTime_PCM" SG_ 2566899694 DayRestPer1Flag 300000;
BA_ "GenSigSendType" SG_ 2566899694 DayRestPer1Flag 3;
BA_ "CI_SigName" SG_ 2566899694 DayRestPer1Flag "Daily Resting Period 1 Flag";
BA_ "CI_SigId" SG_ 2566899694 DayRestPer1Flag 13514;
BA_ "CI_ParId" SG_ 2566899694 DayRestPer1Flag "V031";
BA_ "GenSigTimeoutTime_SGW" SG_ 2566899694 DayRestPer1 300000;
BA_ "GenSigTimeoutTime_PCM" SG_ 2566899694 DayRestPer1 300000;
BA_ "GenSigSendType" SG_ 2566899694 DayRestPer1 3;
BA_ "CI_SigName" SG_ 2566899694 DayRestPer1 "Daily Resting Period 1";
BA_ "CI_SigId" SG_ 2566899694 DayRestPer1 13513;
BA_ "CI_ParId" SG_ 2566899694 DayRestPer1 "V030";
BA_ "GenSigTimeoutTime_SGW" SG_ 2566899694 DayDrivTimeShift6Flag 300000;
BA_ "GenSigTimeoutTime_PCM" SG_ 2566899694 DayDrivTimeShift6Flag 300000;
BA_ "GenSigSendType" SG_ 2566899694 DayDrivTimeShift6Flag 3;
BA_ "CI_SigName" SG_ 2566899694 DayDrivTimeShift6Flag "Daily Driving Time Shift 6 Flag";
BA_ "CI_SigId" SG_ 2566899694 DayDrivTimeShift6Flag 13512;
BA_ "CI_ParId" SG_ 2566899694 DayDrivTimeShift6Flag "V029";
BA_ "GenSigTimeoutTime_SGW" SG_ 2566899694 DayDrivTimeShift6 300000;
BA_ "GenSigTimeoutTime_PCM" SG_ 2566899694 DayDrivTimeShift6 300000;
BA_ "GenSigSendType" SG_ 2566899694 DayDrivTimeShift6 3;
BA_ "CI_SigName" SG_ 2566899694 DayDrivTimeShift6 "Daily Driving Time Shift 6";
BA_ "CI_SigId" SG_ 2566899694 DayDrivTimeShift6 13511;
BA_ "CI_ParId" SG_ 2566899694 DayDrivTimeShift6 "V028";
BA_ "GenSigTimeoutTime_SGW" SG_ 2566899694 DayDrivTimeShift5Flag 300000;
BA_ "GenSigTimeoutTime_PCM" SG_ 2566899694 DayDrivTimeShift5Flag 300000;
BA_ "GenSigSendType" SG_ 2566899694 DayDrivTimeShift5Flag 3;
BA_ "CI_SigName" SG_ 2566899694 DayDrivTimeShift5Flag "Daily Driving Time Shift 5 Flag";
BA_ "CI_SigId" SG_ 2566899694 DayDrivTimeShift5Flag 13510;
BA_ "CI_ParId" SG_ 2566899694 DayDrivTimeShift5Flag "V027";
BA_ "GenSigTimeoutTime_SGW" SG_ 2566899694 DayDrivTimeShift5 300000;
BA_ "GenSigTimeoutTime_PCM" SG_ 2566899694 DayDrivTimeShift5 300000;
BA_ "GenSigSendType" SG_ 2566899694 DayDrivTimeShift5 3;
BA_ "CI_SigName" SG_ 2566899694 DayDrivTimeShift5 "Daily Driving Time Shift 5";
BA_ "CI_SigId" SG_ 2566899694 DayDrivTimeShift5 13509;
BA_ "CI_ParId" SG_ 2566899694 DayDrivTimeShift5 "V026";
BA_ "GenSigTimeoutTime_SGW" SG_ 2566899694 DayDrivTimeShift4Flag 300000;
BA_ "GenSigTimeoutTime_PCM" SG_ 2566899694 DayDrivTimeShift4Flag 300000;
BA_ "GenSigSendType" SG_ 2566899694 DayDrivTimeShift4Flag 3;
BA_ "CI_SigName" SG_ 2566899694 DayDrivTimeShift4Flag "Daily Driving Time Shift 4 Flag";
BA_ "CI_SigId" SG_ 2566899694 DayDrivTimeShift4Flag 13508;
BA_ "CI_ParId" SG_ 2566899694 DayDrivTimeShift4Flag "V025";
BA_ "GenSigTimeoutTime_SGW" SG_ 2566899694 DayDrivTimeShift4 300000;
BA_ "GenSigTimeoutTime_PCM" SG_ 2566899694 DayDrivTimeShift4 300000;
BA_ "GenSigSendType" SG_ 2566899694 DayDrivTimeShift4 3;
BA_ "CI_SigName" SG_ 2566899694 DayDrivTimeShift4 "Daily Driving Time Shift 4";
BA_ "CI_SigId" SG_ 2566899694 DayDrivTimeShift4 13507;
BA_ "CI_ParId" SG_ 2566899694 DayDrivTimeShift4 "V024";
BA_ "GenSigTimeoutTime_SGW" SG_ 2566899694 DayDrivTimeShift3Flag 300000;
BA_ "GenSigTimeoutTime_PCM" SG_ 2566899694 DayDrivTimeShift3Flag 300000;
BA_ "GenSigSendType" SG_ 2566899694 DayDrivTimeShift3Flag 3;
BA_ "CI_SigName" SG_ 2566899694 DayDrivTimeShift3Flag "Daily Driving Time Shift 3 Flag";
BA_ "CI_SigId" SG_ 2566899694 DayDrivTimeShift3Flag 13506;
BA_ "CI_ParId" SG_ 2566899694 DayDrivTimeShift3Flag "V023";
BA_ "GenSigTimeoutTime_SGW" SG_ 2566899694 DayDrivTimeShift3 300000;
BA_ "GenSigTimeoutTime_PCM" SG_ 2566899694 DayDrivTimeShift3 300000;
BA_ "GenSigSendType" SG_ 2566899694 DayDrivTimeShift3 3;
BA_ "CI_SigName" SG_ 2566899694 DayDrivTimeShift3 "Daily Driving Time Shift 3";
BA_ "CI_SigId" SG_ 2566899694 DayDrivTimeShift3 13505;
BA_ "CI_ParId" SG_ 2566899694 DayDrivTimeShift3 "V022";
BA_ "GenSigTimeoutTime_SGW" SG_ 2566899694 DayDrivTimeShift2Flag 300000;
BA_ "GenSigTimeoutTime_PCM" SG_ 2566899694 DayDrivTimeShift2Flag 300000;
BA_ "GenSigSendType" SG_ 2566899694 DayDrivTimeShift2Flag 3;
BA_ "CI_SigName" SG_ 2566899694 DayDrivTimeShift2Flag "Daily Driving Time Shift 2 Flag";
BA_ "CI_SigId" SG_ 2566899694 DayDrivTimeShift2Flag 13504;
BA_ "CI_ParId" SG_ 2566899694 DayDrivTimeShift2Flag "V021";
BA_ "GenSigTimeoutTime_SGW" SG_ 2566899694 DayDrivTimeShift2 300000;
BA_ "GenSigTimeoutTime_PCM" SG_ 2566899694 DayDrivTimeShift2 300000;
BA_ "GenSigSendType" SG_ 2566899694 DayDrivTimeShift2 3;
BA_ "CI_SigName" SG_ 2566899694 DayDrivTimeShift2 "Daily Driving Time Shift 2";
BA_ "CI_SigId" SG_ 2566899694 DayDrivTimeShift2 13503;
BA_ "CI_ParId" SG_ 2566899694 DayDrivTimeShift2 "V020";
BA_ "GenSigTimeoutTime_SGW" SG_ 2566899694 DayDrivTimeShift1Flag 300000;
BA_ "GenSigTimeoutTime_PCM" SG_ 2566899694 DayDrivTimeShift1Flag 300000;
BA_ "GenSigSendType" SG_ 2566899694 DayDrivTimeShift1Flag 3;
BA_ "CI_SigName" SG_ 2566899694 DayDrivTimeShift1Flag "Daily Driving Time Shift 1 Flag";
BA_ "CI_SigId" SG_ 2566899694 DayDrivTimeShift1Flag 13502;
BA_ "CI_ParId" SG_ 2566899694 DayDrivTimeShift1Flag "V019";
BA_ "GenSigTimeoutTime_SGW" SG_ 2566899694 DayDrivTimeShift1 300000;
BA_ "GenSigTimeoutTime_PCM" SG_ 2566899694 DayDrivTimeShift1 300000;
BA_ "GenSigSendType" SG_ 2566899694 DayDrivTimeShift1 3;
BA_ "CI_SigName" SG_ 2566899694 DayDrivTimeShift1 "Daily Driving Time Shift 1";
BA_ "CI_SigId" SG_ 2566899694 DayDrivTimeShift1 764;
BA_ "CI_ParId" SG_ 2566899694 DayDrivTimeShift1 "V018";
BA_ "GenSigTimeoutTime_SGW" SG_ 2566899694 DayDrivTimeFlag 300000;
BA_ "GenSigTimeoutTime_PCM" SG_ 2566899694 DayDrivTimeFlag 300000;
BA_ "GenSigSendType" SG_ 2566899694 DayDrivTimeFlag 3;
BA_ "CI_SigName" SG_ 2566899694 DayDrivTimeFlag "Daily Driving Time Flag";
BA_ "CI_SigId" SG_ 2566899694 DayDrivTimeFlag 763;
BA_ "CI_ParId" SG_ 2566899694 DayDrivTimeFlag "V017";
BA_ "GenSigTimeoutTime_SGW" SG_ 2566899694 DayDrivTime 300000;
BA_ "GenSigTimeoutTime_PCM" SG_ 2566899694 DayDrivTime 300000;
BA_ "GenSigSendType" SG_ 2566899694 DayDrivTime 3;
BA_ "CI_SigName" SG_ 2566899694 DayDrivTime "Daily Driving Time";
BA_ "CI_SigId" SG_ 2566899694 DayDrivTime 762;
BA_ "CI_ParId" SG_ 2566899694 DayDrivTime "V016";
BA_ "SigType" SG_ 2566899694 WeekTotDrivTime 1;
BA_ "GenSigTimeoutTime_SGW" SG_ 2566899694 WeekTotDrivTime 300000;
BA_ "GenSigTimeoutTime_PCM" SG_ 2566899694 WeekTotDrivTime 300000;
BA_ "GenSigSendType" SG_ 2566899694 WeekTotDrivTime 3;
BA_ "CI_SigName" SG_ 2566899694 WeekTotDrivTime "Weekly Total Driving Time";
BA_ "CI_SigId" SG_ 2566899694 WeekTotDrivTime 761;
BA_ "CI_ParId" SG_ 2566899694 WeekTotDrivTime "V015";
BA_ "SigType" SG_ 2566899694 TwoWeeksTotDrivTime 1;
BA_ "GenSigTimeoutTime_SGW" SG_ 2566899694 TwoWeeksTotDrivTime 300000;
BA_ "GenSigTimeoutTime_PCM" SG_ 2566899694 TwoWeeksTotDrivTime 300000;
BA_ "GenSigSendType" SG_ 2566899694 TwoWeeksTotDrivTime 3;
BA_ "CI_SigName" SG_ 2566899694 TwoWeeksTotDrivTime "Two Weeks Total Driving Time";
BA_ "CI_SigId" SG_ 2566899694 TwoWeeksTotDrivTime 760;
BA_ "CI_ParId" SG_ 2566899694 TwoWeeksTotDrivTime "V014";
BA_ "GenSigTimeoutTime_SGW" SG_ 2650771712 DatasetCustEOL06 25000;
BA_ "GenSigTimeoutTime_PCM" SG_ 2650771712 DatasetCustEOL06 25000;
BA_ "CI_SigName" SG_ 2650771712 DatasetCustEOL06 "Dataset Customization EOL 06";
BA_ "CI_SigId" SG_ 2650771712 DatasetCustEOL06 17428;
BA_ "CI_ParId" SG_ 2650771712 DatasetCustEOL06 "F297";
BA_ "GenSigTimeoutTime_SGW" SG_ 2650771712 DatasetCustEOL05 25000;
BA_ "GenSigTimeoutTime_PCM" SG_ 2650771712 DatasetCustEOL05 25000;
BA_ "CI_SigName" SG_ 2650771712 DatasetCustEOL05 "Dataset Customization EOL 05";
BA_ "CI_SigId" SG_ 2650771712 DatasetCustEOL05 17427;
BA_ "CI_ParId" SG_ 2650771712 DatasetCustEOL05 "F296";
BA_ "GenSigTimeoutTime_SGW" SG_ 2650771712 DatasetCustEOL04 25000;
BA_ "GenSigTimeoutTime_PCM" SG_ 2650771712 DatasetCustEOL04 25000;
BA_ "CI_SigName" SG_ 2650771712 DatasetCustEOL04 "Dataset Customization EOL 04";
BA_ "CI_SigId" SG_ 2650771712 DatasetCustEOL04 17426;
BA_ "CI_ParId" SG_ 2650771712 DatasetCustEOL04 "F295";
BA_ "GenSigTimeoutTime_SGW" SG_ 2650771712 DatasetCustEOL03 25000;
BA_ "GenSigTimeoutTime_PCM" SG_ 2650771712 DatasetCustEOL03 25000;
BA_ "CI_SigName" SG_ 2650771712 DatasetCustEOL03 "Dataset Customization EOL 03";
BA_ "CI_SigId" SG_ 2650771712 DatasetCustEOL03 17425;
BA_ "CI_ParId" SG_ 2650771712 DatasetCustEOL03 "F294";
BA_ "GenSigTimeoutTime_SGW" SG_ 2650771712 DatasetCustEOL02 25000;
BA_ "GenSigTimeoutTime_PCM" SG_ 2650771712 DatasetCustEOL02 25000;
BA_ "CI_SigName" SG_ 2650771712 DatasetCustEOL02 "Dataset Customization EOL 02";
BA_ "CI_SigId" SG_ 2650771712 DatasetCustEOL02 17424;
BA_ "CI_ParId" SG_ 2650771712 DatasetCustEOL02 "F293";
BA_ "GenSigTimeoutTime_SGW" SG_ 2650771712 DatasetCustEOL01 25000;
BA_ "GenSigTimeoutTime_PCM" SG_ 2650771712 DatasetCustEOL01 25000;
BA_ "CI_SigName" SG_ 2650771712 DatasetCustEOL01 "Dataset Customization EOL 01";
BA_ "CI_SigId" SG_ 2650771712 DatasetCustEOL01 17423;
BA_ "CI_ParId" SG_ 2650771712 DatasetCustEOL01 "F292";
BA_ "GenSigTimeoutTime_SGW" SG_ 2650771712 MinorVer 25000;
BA_ "GenSigTimeoutTime_PCM" SG_ 2650771712 MinorVer 25000;
BA_ "CI_SigName" SG_ 2650771712 MinorVer "Minor Version";
BA_ "CI_SigId" SG_ 2650771712 MinorVer 17422;
BA_ "CI_ParId" SG_ 2650771712 MinorVer "F291";
BA_ "GenSigTimeoutTime_SGW" SG_ 2650771712 MajorVer 25000;
BA_ "GenSigTimeoutTime_PCM" SG_ 2650771712 MajorVer 25000;
BA_ "CI_SigName" SG_ 2650771712 MajorVer "Major Version";
BA_ "CI_SigId" SG_ 2650771712 MajorVer 17421;
BA_ "CI_ParId" SG_ 2650771712 MajorVer "F290";
BA_ "GenSigTimeoutTime_SGW" SG_ 2650771968 DatasetCustEOL14 25000;
BA_ "GenSigTimeoutTime_PCM" SG_ 2650771968 DatasetCustEOL14 25000;
BA_ "CI_SigName" SG_ 2650771968 DatasetCustEOL14 "Dataset Customization EOL 14";
BA_ "CI_SigId" SG_ 2650771968 DatasetCustEOL14 17437;
BA_ "CI_ParId" SG_ 2650771968 DatasetCustEOL14 "F305";
BA_ "GenSigTimeoutTime_SGW" SG_ 2650771968 DatasetCustEOL13 25000;
BA_ "GenSigTimeoutTime_PCM" SG_ 2650771968 DatasetCustEOL13 25000;
BA_ "CI_SigName" SG_ 2650771968 DatasetCustEOL13 "Dataset Customization EOL 13";
BA_ "CI_SigId" SG_ 2650771968 DatasetCustEOL13 17436;
BA_ "CI_ParId" SG_ 2650771968 DatasetCustEOL13 "F304";
BA_ "GenSigTimeoutTime_SGW" SG_ 2650771968 DatasetCustEOL12 25000;
BA_ "GenSigTimeoutTime_PCM" SG_ 2650771968 DatasetCustEOL12 25000;
BA_ "CI_SigName" SG_ 2650771968 DatasetCustEOL12 "Dataset Customization EOL 12";
BA_ "CI_SigId" SG_ 2650771968 DatasetCustEOL12 17435;
BA_ "CI_ParId" SG_ 2650771968 DatasetCustEOL12 "F303";
BA_ "GenSigTimeoutTime_SGW" SG_ 2650771968 DatasetCustEOL11 25000;
BA_ "GenSigTimeoutTime_PCM" SG_ 2650771968 DatasetCustEOL11 25000;
BA_ "CI_SigName" SG_ 2650771968 DatasetCustEOL11 "Dataset Customization EOL 11";
BA_ "CI_SigId" SG_ 2650771968 DatasetCustEOL11 17434;
BA_ "CI_ParId" SG_ 2650771968 DatasetCustEOL11 "F302";
BA_ "GenSigTimeoutTime_SGW" SG_ 2650771968 DatasetCustEOL10 25000;
BA_ "GenSigTimeoutTime_PCM" SG_ 2650771968 DatasetCustEOL10 25000;
BA_ "CI_SigName" SG_ 2650771968 DatasetCustEOL10 "Dataset Customization EOL 10";
BA_ "CI_SigId" SG_ 2650771968 DatasetCustEOL10 17433;
BA_ "CI_ParId" SG_ 2650771968 DatasetCustEOL10 "F301";
BA_ "GenSigTimeoutTime_SGW" SG_ 2650771968 DatasetCustEOL09 25000;
BA_ "GenSigTimeoutTime_PCM" SG_ 2650771968 DatasetCustEOL09 25000;
BA_ "CI_SigName" SG_ 2650771968 DatasetCustEOL09 "Dataset Customization EOL 09";
BA_ "CI_SigId" SG_ 2650771968 DatasetCustEOL09 17432;
BA_ "CI_ParId" SG_ 2650771968 DatasetCustEOL09 "F300";
BA_ "GenSigTimeoutTime_SGW" SG_ 2650771968 DatasetCustEOL08 25000;
BA_ "GenSigTimeoutTime_PCM" SG_ 2650771968 DatasetCustEOL08 25000;
BA_ "CI_SigName" SG_ 2650771968 DatasetCustEOL08 "Dataset Customization EOL 08";
BA_ "CI_SigId" SG_ 2650771968 DatasetCustEOL08 17431;
BA_ "CI_ParId" SG_ 2650771968 DatasetCustEOL08 "F299";
BA_ "GenSigTimeoutTime_SGW" SG_ 2650771968 DatasetCustEOL07 25000;
BA_ "GenSigTimeoutTime_PCM" SG_ 2650771968 DatasetCustEOL07 25000;
BA_ "CI_SigName" SG_ 2650771968 DatasetCustEOL07 "Dataset Customization EOL 07";
BA_ "CI_SigId" SG_ 2650771968 DatasetCustEOL07 17430;
BA_ "CI_ParId" SG_ 2650771968 DatasetCustEOL07 "F298";
BA_ "SigType" SG_ 2650766848 osMisfCoilCyl2Tmp200 1;
BA_ "GenSigTimeoutTime_SGW" SG_ 2650766848 osMisfCoilCyl2Tmp200 2500;
BA_ "GenSigTimeoutTime_PCM" SG_ 2650766848 osMisfCoilCyl2Tmp200 2500;
BA_ "CI_SigName" SG_ 2650766848 osMisfCoilCyl2Tmp200 "Misfire counter for cylinder 2 in a 200 rpm window";
BA_ "CI_SigId" SG_ 2650766848 osMisfCoilCyl2Tmp200 17443;
BA_ "CI_ParId" SG_ 2650766848 osMisfCoilCyl2Tmp200 "F337";
BA_ "SigType" SG_ 2650766848 osMisfCoilCyl1Tmp200 1;
BA_ "GenSigTimeoutTime_SGW" SG_ 2650766848 osMisfCoilCyl1Tmp200 2500;
BA_ "GenSigTimeoutTime_PCM" SG_ 2650766848 osMisfCoilCyl1Tmp200 2500;
BA_ "CI_SigName" SG_ 2650766848 osMisfCoilCyl1Tmp200 "Misfire counter for cylinder 1 in a 200 rpm window";
BA_ "CI_SigId" SG_ 2650766848 osMisfCoilCyl1Tmp200 17442;
BA_ "CI_ParId" SG_ 2650766848 osMisfCoilCyl1Tmp200 "F336";
BA_ "SigType" SG_ 2650766848 csExhaustVFlow 1;
BA_ "GenSigTimeoutTime_SGW" SG_ 2650766848 csExhaustVFlow 2500;
BA_ "GenSigTimeoutTime_PCM" SG_ 2650766848 csExhaustVFlow 2500;
BA_ "CI_SigName" SG_ 2650766848 csExhaustVFlow "Exhaust flow";
BA_ "CI_SigId" SG_ 2650766848 csExhaustVFlow 17441;
BA_ "CI_ParId" SG_ 2650766848 csExhaustVFlow "F335";
BA_ "SigType" SG_ 2650766848 asQacMapSD 1;
BA_ "GenSigTimeoutTime_SGW" SG_ 2650766848 asQacMapSD 2500;
BA_ "GenSigTimeoutTime_PCM" SG_ 2650766848 asQacMapSD 2500;
BA_ "CI_SigName" SG_ 2650766848 asQacMapSD "Fresh air mass flow per stroke";
BA_ "CI_SigId" SG_ 2650766848 asQacMapSD 17440;
BA_ "CI_ParId" SG_ 2650766848 asQacMapSD "F334";
BA_ "SigType" SG_ 2650766848 zsCrankCasePres 1;
BA_ "GenSigTimeoutTime_SGW" SG_ 2650766848 zsCrankCasePres 2500;
BA_ "GenSigTimeoutTime_PCM" SG_ 2650766848 zsCrankCasePres 2500;
BA_ "CI_SigName" SG_ 2650766848 zsCrankCasePres "Crankcase pressure";
BA_ "CI_SigId" SG_ 2650766848 zsCrankCasePres 17439;
BA_ "CI_ParId" SG_ 2650766848 zsCrankCasePres "F333";
VAL_ 2364539395 TransmInSpeed 65534 "Error" 65535 "Not_available" ;
VAL_ 2364539395 TransmOutSpeed 65534 "Error" 65535 "Not_available" ;
VAL_ 2364539395 TransmDrvlEngd 0 "Driveline disengaged" 1 "Driveline engaged" 2 "Error" 3 "Not Available" ;
VAL_ 2565866755 TransmCurGear 124 "Reverse" 125 "Neutral" 126 "1st Gear" 127 "2nd Gear" 128 "3rd Gear" 129 "4th Gear" 130 "5th Gear" 131 "6th Gear" 132 "7th Gear" 133 "8th Gear" 251 "Park" 254 "Error" 255 "Not Available" ;
VAL_ 2565866755 TransmSelGear 251 "Park" 254 "Error" 255 "Not Available" ;
VAL_ 2364541955 TransmTrqConvRatio 1000 "torque_converte_Locked" 64256 "Engine_Brake_Mode" 65024 "Error" 65535 "Not_available" ;
VAL_ 2431649694 LaneDepImmLh 0 "Not imminent" 1 "Imminent" 2 "Reserved" 3 "Not used" ;
VAL_ 2431649694 LaneDepImmRh 0 "Not imminent" 1 "Imminent" 2 "Reserved" 3 "Not Used" ;
VAL_ 2566806430 FwLaneImagerSts 0 "Ffully operational" 1 "Warming up / initializing" 2 "Part. blocked / part. blind" 3 "Fully blocked / fully blind" 4 "Misaligned" 5 "View degraded but functional" 6 "Reserved" 7 "Reserved" 8 "Reserved" 9 "Reserved" 10 "Reserved" 11 "Reserved" 12 "Reserved" 13 "Reserved" 14 "Error" 15 "Not Available" ;
VAL_ 2566806430 LdwSysSts 0 "Not ready" 1 "Temporarily not available" 2 "Deactivated by driver" 3 "Ready (no warnings active)" 4 "Suppressed by operator behavior" 5 "Warning lane departure" 6 "Reserved" 7 "Reserved" 8 "Reserved" 9 "Reserved" 10 "Reserved" 11 "Reserved" 12 "Reserved" 13 "Reserved" 14 "Error" 15 "Not Available" ;
VAL_ 2566806430 DrivAlertWarnSysSts 0 ">Installed but disabled" 1 "Initializing" 2 "Temporarily not available" 3 "Available" 4 "Monitoring driver behavior" 5 "Reserved" 6 "Reserved" 7 "Not Available / Not Installed" ;
VAL_ 2566806430 LaneDepIndEnaSts 0 "Disabled" 1 "Enabled" 2 "Reserved" 3 "Not Used" ;
VAL_ 2566837793 HybSysPwrElnCoolLevSw 0 "Not sufficient" 1 "Sufficient" 2 "Error" 3 "Not Available" ;
VAL_ 2566701658 ExtEnergySrcConnSts 0 "No Conn." 1 "Conn.1, Error (Verific. failed)" 2 "Conn.1, Verification in Process" 3 "Conn.1, Energy Source and Drain" 4 "Conn.1, Energy Source" 5 "Conn.1, Energy Drain" 6 "Conn.2, Error (Verific. failed)" 7 "Conn.2, Verification in Process" 8 "Conn.2, Energy Source and Drain" 9 "Conn.2, Energy Source" 10 "Conn.2, Energy Drain" 11 "Reserved" 12 "Reserved" 13 "Reserved" 14 "Error" 15 "Not Available" ;
VAL_ 2566701658 HybPropModeSts 0 "No mode requested" 1 "Sustaining" 2 "Increasing" 3 "Depleting" 4 "Offline" 5 "Only" 6 "Reserved" 7 "Reserved" 8 "Reserved" 9 "Reserved" 10 "Reserved" 11 "Reserved" 12 "Reserved" 13 "Reserved" 14 "Error" 15 "Not Available" ;
VAL_ 2566701658 HybSysRegenBrkInd 0 "Inactive" 1 "Active" 2 "Disabled or faulted" 3 "Not Available" ;
VAL_ 2566701658 HybSysMotOverspeedInd 0 "Off" 1 "On continously" 2 "Flashing" 3 "Not Available" ;
VAL_ 2566701658 PropSysActv 0 "Not ready to move" 1 "Ready to move or moving" 2 "Reserved" 3 "Not Available" ;
VAL_ 2566698842 HybSysEassRemPc 0 "No operation available" 250 "Max operation available" ;
VAL_ 2566698842 HybBatRemChg 0 "No charge" 40000 "Full charge" ;
VAL_ 2566851331 Isbalancingactive 0 "Balancing not active" 1 "Balancing active" 2 "Error" 3 "Not Available" ;
VAL_ 2566890368 CurSensSysSts 0 "NoError" 1 "AmberLamp" 2 "RedStopLamp" ;
VAL_ 2566909824 Aux3DcPwr 255 "not available" ;
VAL_ 2566909824 Aux3AcPwr 255 "not available" ;
VAL_ 2566844928 EngAvgFuelEcon 0 "vehicle_stop_at_idle" 251 "Engine off" ;
VAL_ 2566844928 EngInstFuelEcon 64256 "Infinite" ;
VAL_ 2566861299 ChgComplSts 0 "NotComplete/off" 1 "Complete" 2 "Error" 3 "NotAvailable" ;
VAL_ 2566878241 InterSansSecu_DrivWithH2HatchOp 0 "InterSansSecuNotActivated" 1 "InterSSecuPressAllowDrivH2HtchOp" ;
VAL_ 2566878241 FC_CoolGroupLevTooLow 0 "No Low level" 1 "Low level" ;
VAL_ 2566878241 LimpHomeFC_Mode_OvReq 0 "No override mode" 1 "Override mode req by driver" ;
VAL_ 2566878241 Fill_AuthorizFromVehSide 0 "H2 Filling not allowed" 1 "H2 Filling is allowed" ;
VAL_ 2566878241 Authoriz_FC_ActivByVehCond 0 "FC not allowed" 1 "FC allowed by vehicle conditions" 2 "Not used" 3 "Not used" ;
VAL_ 2566776097 AppliedVsl 251 "Speed limit not selected" ;
VAL_ 2365443105 TurnSigSw 0 "No Turn being signaled" 1 "Left Turn to be Flashing" 2 "Right turn to be Flashing" 14 "Error, left + right sel. simult." 15 "Not Available (do not change)" ;
VAL_ 2566769953 FrontOpWasherSw 0 "Off" 1 "Low" 2 "Medium" 3 "High" 4 "Reserved" 5 "Reserved" 6 "Reserved" 7 "Not Available (do not change)" ;
VAL_ 2566769953 FrontOpWiperSw 0 "Off" 1 "Low" 2 "Medium" 3 "High" 4 "Delayed 1" 5 "Delayed 2" 6 "Mist" 14 "Error" 15 "Not Available / Do not change" ;
VAL_ 2633959399 StopLamp 0 "Lamp_NotActive" 1 "Lamp_Active" 2 "Error" 3 "SNA" ;
VAL_ 2633959399 FunctLamp 0 "Lamp_NotActive" 1 "Lamp_Active" 2 "Error" 3 "SNA" ;
VAL_ 2566850535 StopLamp_FF07E7 0 "Lamp_NotActive" 1 "Lamp_Active" 2 "Error" 3 "SNA" ;
VAL_ 2566850535 FunctLamp_FF07E7 0 "Lamp_NotActive" 1 "Lamp_Active" 2 "Error" 3 "SNA" ;
VAL_ 2566908574 DdawRunMode 0 "Feature OFF" 1 "Standby" 2 "Driver Behaviour Learning" 3 "Driver Behaviour Monitoring" 4 "Reserved" 5 "Warning active" 6 "Error" 7 "Not Available" ;
VAL_ 2566908574 DrowsDrivLev 0 "Not Used" 1 "Extremely Alert" 2 "Alert" 3 "Neither Sleepy nor Alert" 4 "Drowsy" 5 "Extemely Drowsy" 6 "Reserved" 7 "Reserved" ;
VAL_ 2566907159 MsgCks 15 "Not Available, request honored" ;
VAL_ 2566907159 MsgCnt 8 "Reserved" 9 "Reserved" 10 "Reserved" 11 "Reserved" 12 "Reserved" 13 "Reserved" 14 "Reserved" 15 "Not Available, request honored" ;
VAL_ 2566907159 LdwsCsfPreSel 0 "LDWS" 1 "LDWS+CSF" 2 "Reserved" 3 "Not Available" ;
VAL_ 2566907159 RightVibratorFail 0 "Inactive" 1 "Active" 2 "Reserved" 3 "Take no action" ;
VAL_ 2566907159 LeftVibratorFail 0 "Inactive" 1 "Active" 2 "Reserved" 3 "Take no action" ;
VAL_ 2566907159 BsisFuncEn 0 "Off" 1 "On" 2 "Error" 3 "Not Available" ;
VAL_ 2566907159 PlcaWarnEn 0 "Disabled" 1 "Enabled" 2 "Error" 3 "Not Available" ;
VAL_ 2566907159 PlcaFuncEn 0 "Off" 1 "On" 2 "Error" 3 "Not Available" ;
VAL_ 2566907159 RightLedbarFail 0 "Inactive" 1 "Active" 2 "Reserved" 3 "Take no action" ;
VAL_ 2566907159 LeftLedbarFail 0 "Inactive" 1 "Active" 2 "Reserved" 3 "Take no action" ;
VAL_ 2566907159 BuzFail 0 "Inactive" 1 "Active" 2 "Reserved" 3 "Take no action" ;
VAL_ 2566907159 RightSpeakFail 0 "Inactive" 1 "Active" 2 "Reserved" 3 "Take no action" ;
VAL_ 2566907159 LeftSpeakFail 0 "Inactive" 1 "Active" 2 "Reserved" 3 "Take no action" ;
VAL_ 2566907159 DrivDrowsWarnEnaSet 0 "Disable" 1 "Enable" 2 "Error" 3 "Not Available" ;
VAL_ 2583638259 OpSts 0 "Initialization in process" 1 "Initialization Complete" 2 "Operational" 3 "Normal Pwr-Down in Process" 4 "Emergency Pwr-Down In Process" 5 "Disabled by external command" 6 "Disabled by internal decision" 7 "Not Operational" 8 "Reserved" 9 "Reserved" 10 "Reserved" 11 "Reserved" 12 "Reserved" 13 "Reserved" 14 "Error" 15 "Not Available" ;
VAL_ 2583638259 ThermEvtDet 0 "No Event Detected" 1 "Event Detected" 2 "Error" 3 "Not Available" ;
VAL_ 2566894871 CntryCode 0 "Unknown" ;
VAL_ 2566894871 IntlSpeedAssantActv 0 "normal op SLI enabled" 1 "normal op SLI Opt ena Snd ena" 2 "normal op SLI Opt only ena" 3 "Reserved" 4 "Reserved" 5 "Reserved" 6 "Error" 7 "Not Available" ;
VAL_ 2566895006 IsaSpeedOverridden 0 "NotOverspeeding" 1 "Overspeedding" 2 "Error" 3 "Not Available" ;
VAL_ 2566895006 SpeedLimConf 0 "Not Confidence" 1 "Confidence" 2 "Error" 3 "Not Available" ;
VAL_ 2566895006 MaxVslUnitless 29 "None" 30 "Sign Not Recognized" 31 "Signal Not Available" ;
VAL_ 2566895006 CntryCode_FFB59E 0 "Unknown" ;
VAL_ 2566895006 CntryCodeCfg 0 "Manual" 1 "Automatic" 2 "Error" 3 "Not available" ;
VAL_ 2566895006 IsaDbgSts 0 "NRTA" 1 "ERROR" 2 "RTA_SLWF_FULL_STANDBY" 3 "RTA_SLWF_FULL_WARN_ACTIVE" 4 "RTA_SLWF_PARTIAL_STANDBY" 5 "RTA_SLWF_PARTIAL_WARN_ACTIVE" 6 "DISABLED_BY_DRIVER_SLIF" 7 "DISABLED_BY_SYSTEM_SLIF" 8 "INIT" 15 "Not Available" ;
VAL_ 2566895006 IntlSpeedAssantSts 0 "SLI enabled" 1 "SLI ena SLW Vis ena Snd ena" 2 "SLI ena SLW Vis only ena" 3 "OutOfWorking boundaries SLI ena" 4 "Reserved" 5 "Initiation status" 6 "Error status" 7 "Not Available" ;
VAL_ 2566895006 IntlSpeedAssantActv_FFB59E 0 "normal op SLI enabled" 1 "normal op SLI Opt ena Snd ena" 2 "normal op SLI Opt only ena" 3 "Reserved" 4 "Reserved" 5 "Reserved" 6 "Error" 7 "Not Available" ;
VAL_ 2566895006 MaxVslWarn 0 "Disabled" 1 "Optical" 2 "Optical and Acoustic" 6 "Error" 7 "Not Available" ;
VAL_ 2365575713 EngStarterSts 0 "Off" 1 "On" 2 "Error Indicator" 3 "Not Available" ;
VAL_ 2365575713 IgnOn 0 "Off" 1 "On" 2 "Reserved" 3 "No Action" ;
VAL_ 2566892573 SevAnomalyInBlk2 0 "No" 1 "Yes" 2 "Error" 3 "Not Available" ;
VAL_ 2566892573 SevAnomalyInBlk1 0 "No" 1 "Yes" 2 "Error" 3 "Not Available" ;
VAL_ 2566892573 Blk2Full 0 "No" 1 "Yes" 2 "Error" 3 "Not Available" ;
VAL_ 2566892573 Blk1Full 0 "No" 1 "Yes" 2 "Error" 3 "Not Available" ;
VAL_ 2566892618 WarnRx 0 "No" 1 "Yes" 2 "Error" 3 "Not Available" ;
VAL_ 2566885148 SpeedLimType 0 "DERIVED/UNAVAILABLE" 1 "POSTED" ;
VAL_ 2566885148 BuiltUpArea 0 "false" 1 "true" ;
VAL_ 2566885148 FunctRoadClass 0 "Unkown" 1 "FC_1" 2 "FC_2" 3 "FC_3" 4 "FC_4" 5 "FC_5" 6 "Undefined" 7 "Not available" ;
VAL_ 2566898670 WFact 0 "Not used" ;
VAL_ 2566898670 NextCalDateMonth 0 "Not used" ;
VAL_ 2566898670 NextCalDateDay 0 "Not used" ;
VAL_ 2566898926 PrintDrawSts 0 "Open" 1 "Closed" 2 "Error" 3 "Not Available" ;
VAL_ 2566898926 EndOfLifeDriv1CardAlert 0 "No Alert" 1 "Alert Active" 2 "Error" 3 "Not Available" ;
VAL_ 2566898926 Driv1CardDwlAlert 0 "No Alert" 1 "Alert Active" 2 "Error" 3 "Not Available" ;
VAL_ 2566899694 DayRestPer7Flag 0 "No Unknown activities" 1 "At least 1 Unknown act period" ;
VAL_ 2566899694 DayRestPer7 32766 "Error" 32767 "Not Available" ;
VAL_ 2566899694 DayRestPer6Flag 0 "No Unknown activities" 1 "At least 1 Unknown act period" ;
VAL_ 2566899694 DayRestPer6 32766 "Error" 32767 "Not Available" ;
VAL_ 2566899694 DayRestPer5Flag 0 "No Unknown activities" 1 "At least 1 Unknown act period" ;
VAL_ 2566899694 DayRestPer5 32766 "Error" 32767 "Not Available" ;
VAL_ 2566899694 DayRestPer4Flag 0 "No Unknown activities" 1 "At least 1 Unknown act period" ;
VAL_ 2566899694 DayRestPer4 32766 "Error" 32767 "Not Available" ;
VAL_ 2566899694 DayRestPer3Flag 0 "No Unknown activities" 1 "At least 1 Unknown act period" ;
VAL_ 2566899694 DayRestPer3 32766 "Error" 32767 "Not Available" ;
VAL_ 2566899694 DayRestPer2Flag 0 "No Unknown activities" 1 "At least 1 Unknown act period" ;
VAL_ 2566899694 DayRestPer2 32766 "Error" 32767 "Not Available" ;
VAL_ 2566899694 DayRestPer1Flag 0 "No Unknown activities" 1 "At least 1 Unknown act period" ;
VAL_ 2566899694 DayRestPer1 32766 "Error" 32767 "Not Available" ;
VAL_ 2566899694 DayDrivTimeShift6Flag 0 "No resting period" 1 "At least one resting period" ;
VAL_ 2566899694 DayDrivTimeShift6 32766 "Error" 32767 "Not Available" ;
VAL_ 2566899694 DayDrivTimeShift5Flag 0 "No resting period" 1 "At least one resting period" ;
VAL_ 2566899694 DayDrivTimeShift5 32766 "Error" 32767 "Not Available" ;
VAL_ 2566899694 DayDrivTimeShift4Flag 0 "No resting period" 1 "At least one resting period" ;
VAL_ 2566899694 DayDrivTimeShift4 32766 "Error" 32767 "Not Available" ;
VAL_ 2566899694 DayDrivTimeShift3Flag 0 "No resting period" 1 "At least one resting period" ;
VAL_ 2566899694 DayDrivTimeShift3 32766 "Error" 32767 "Not Available" ;
VAL_ 2566899694 DayDrivTimeShift2Flag 0 "No resting period" 1 "At least one resting period" ;
VAL_ 2566899694 DayDrivTimeShift2 32766 "Error" 32767 "Not Available" ;
VAL_ 2566899694 DayDrivTimeShift1Flag 0 "No resting period" 1 "At least one resting period" ;
VAL_ 2566899694 DayDrivTimeShift1 32766 "Error" 32767 "Not Available" ;
VAL_ 2566899694 DayDrivTimeFlag 0 "No resting period" 1 "At least one resting period" ;
VAL_ 2566899694 DayDrivTime 32766 "Error" 32767 "Not Available" ;
